VERSION ""

NS_ :

BS_:

BU_: ETH

BO_ 1332 VCFRONT_alertLog: 8 Vector__XXX
 SG_ VCFRONT_alertID M : 0|10@1+ (1,0) [0|0] "" Vector__XXX
 SG_ VCFRONT_a117_VEH_status m117 : 37|1@1+ (1,0) [0|0] "" Vector__XXX
 SG_ VCFRONT_a118_CH_12VBatteryStatus m118 : 37|1@1+ (1,0) [0|0] "" Vector__XXX
 SG_ VCFRONT_a120_VEH_estimatedBrakeTemp m120 : 37|1@1+ (1,0) [0|0] "" Vector__XXX
 SG_ VCFRONT_a171_OPCS m171 : 37|1@1+ (1,0) [0|0] "" Vector__XXX
 SG_ VCFRONT_a180_serviceMode m180 : 37|1@1+ (1,0) [0|0] "" Vector__XXX
 SG_ VCFRONT_a192_serviceMode m192 : 37|1@1+ (1,0) [0|0] "" Vector__XXX
 SG_ VCFRONT_a257_vbatFusedFault m257 : 37|1@1+ (1,0) [0|0] "" Vector__XXX
 SG_ VCFRONT_a365_showroomMode m365 : 37|1@1+ (1,0) [0|0] "" Vector__XXX
 SG_ VCFRONT_a366_TransportMode m366 : 37|1@1+ (1,0) [0|0] "" Vector__XXX
 SG_ VCFRONT_a368_coolantNotFilled m368 : 37|1@1+ (1,0) [0|0] "" Vector__XXX
 SG_ VCFRONT_a444_overTempShutdown m444 : 37|1@1+ (1,0) [0|0] "" Vector__XXX
 SG_ VCFRONT_a446_usingModeledPl m446 : 37|1@1+ (1,0) [0|0] "" Vector__XXX
 SG_ VCFRONT_a462_MOSFETStuckOpen m462 : 37|1@1+ (1,0) [0|0] "" Vector__XXX
 SG_ VCFRONT_a474_drl1Status m474 : 37|3@1+ (1,0) [0|0] "" Vector__XXX
 SG_ VCFRONT_a475_drl1Status m475 : 37|3@1+ (1,0) [0|0] "" Vector__XXX
 SG_ VCFRONT_a478_notEnoughPowerForSupport m478 : 37|1@1+ (1,0) [0|0] "" Vector__XXX
 SG_ VCFRONT_a480_spiNotDone m480 : 37|1@1+ (1,0) [0|0] "" Vector__XXX
 SG_ VCFRONT_a514_cell4Voltage m514 : 37|7@1+ (0.08,0) [0|0] "" Vector__XXX
 SG_ VCFRONT_a515_cell4Voltage m515 : 37|7@1+ (0.08,0) [0|0] "" Vector__XXX
 SG_ VCFRONT_a516_LVBatteryCannotSupportVehicle m516 : 37|1@1+ (1,0) [0|0] "" Vector__XXX
 SG_ VCFRONT_a522_LVBatteryCannotSupportVehicle m522 : 37|1@1+ (1,0) [0|0] "" Vector__XXX
 SG_ VCFRONT_a606_ccQdotTotalBeforeEntry m606 : 37|6@1+ (111.11111111111111,0) [0|0] "" Vector__XXX
 SG_ VCFRONT_a669_vehicleSpeed m669 : 37|7@1+ (2,0) [0|0] "" Vector__XXX
 SG_ VCFRONT_a670_gpioEfuseEn m670 : 37|1@1+ (1,0) [0|0] "" Vector__XXX
 SG_ VCFRONT_a104_BDY_control m104 : 38|1@1+ (1,0) [0|0] "" Vector__XXX
 SG_ VCFRONT_a113_VEH_tripPlanning m113 : 38|1@1+ (1,0) [0|0] "" Vector__XXX
 SG_ VCFRONT_a117_PARTY_prndStatus m117 : 38|1@1+ (1,0) [0|0] "" Vector__XXX
 SG_ VCFRONT_a118_CH_LVBMS_statusHigh m118 : 38|1@1+ (1,0) [0|0] "" Vector__XXX
 SG_ VCFRONT_a120_PARTY_prndControl m120 : 38|1@1+ (1,0) [0|0] "" Vector__XXX
 SG_ VCFRONT_a171_SCCM m171 : 38|1@1+ (1,0) [0|0] "" Vector__XXX
 SG_ VCFRONT_a180_transportMode m180 : 38|1@1+ (1,0) [0|0] "" Vector__XXX
 SG_ VCFRONT_a192_frunkOpen m192 : 38|1@1+ (1,0) [0|0] "" Vector__XXX
 SG_ VCFRONT_a197_prechargeSuccessful m197 : 38|1@1+ (1,0) [0|0] "" Vector__XXX
 SG_ VCFRONT_a257_iBoosterFault m257 : 38|1@1+ (1,0) [0|0] "" Vector__XXX
 SG_ VCFRONT_a365_TransportMode m365 : 38|1@1+ (1,0) [0|0] "" Vector__XXX
 SG_ VCFRONT_a366_ScheduledDeparture m366 : 38|1@1+ (1,0) [0|0] "" Vector__XXX
 SG_ VCFRONT_a368_coolantPumpsFaulted m368 : 38|1@1+ (1,0) [0|0] "" Vector__XXX
 SG_ VCFRONT_a379_minUnfilteredVoltageReached m379 : 38|12@1+ (0.005443676098,0) [0|0] "" Vector__XXX
 SG_ VCFRONT_a400_VrefType m400 : 38|2@1+ (1,0) [0|0] "" Vector__XXX
 SG_ VCFRONT_a413_VrefType m413 : 38|2@1+ (1,0) [0|0] "" Vector__XXX
 SG_ VCFRONT_a415_IBSVoltage m415 : 38|9@1+ (0.04,0) [0|0] "" Vector__XXX
 SG_ VCFRONT_a444_overTempWarning m444 : 38|1@1+ (1,0) [0|0] "" Vector__XXX
 SG_ VCFRONT_a446_usingModeledTs m446 : 38|1@1+ (1,0) [0|0] "" Vector__XXX
 SG_ VCFRONT_a462_Imbalance m462 : 38|1@1+ (1,0) [0|0] "" Vector__XXX
 SG_ VCFRONT_a476_ECPAState m476 : 38|2@1+ (1,0) [0|0] "" Vector__XXX
 SG_ VCFRONT_a478_crashDetected m478 : 38|1@1+ (1,0) [0|0] "" Vector__XXX
 SG_ VCFRONT_a480_configIncorrect m480 : 38|1@1+ (1,0) [0|0] "" Vector__XXX
 SG_ VCFRONT_a595_IBSVoltage m595 : 38|10@1+ (0.1,-1) [0|0] "" Vector__XXX
 SG_ VCFRONT_a058_prevREstimate m58 : 39|12@1+ (0.00061,0) [0|0] "" Vector__XXX
 SG_ VCFRONT_a104_BDY_status m104 : 39|1@1+ (1,0) [0|0] "" Vector__XXX
 SG_ VCFRONT_a113_VEH_vehicleControl3 m113 : 39|1@1+ (1,0) [0|0] "" Vector__XXX
 SG_ VCFRONT_a117_PARTY_lightingSecondary m117 : 39|1@1+ (1,0) [0|0] "" Vector__XXX
 SG_ VCFRONT_a118_CH_alertMatrix m118 : 39|1@1+ (1,0) [0|0] "" Vector__XXX
 SG_ VCFRONT_a120_PARTY_locStatus2 m120 : 39|1@1+ (1,0) [0|0] "" Vector__XXX
 SG_ VCFRONT_a171_LVBMS m171 : 39|1@1+ (1,0) [0|0] "" Vector__XXX
 SG_ VCFRONT_a178_inverterTemp m178 : 39|6@1+ (3,-40) [0|0] "" Vector__XXX
 SG_ VCFRONT_a180_frunkOpen m180 : 39|1@1+ (1,0) [0|0] "" Vector__XXX
 SG_ VCFRONT_a182_dischargedAmpHours m182 : 39|8@1+ (60,0) [0|0] "" Vector__XXX
 SG_ VCFRONT_a183_dischargedAmpHours m183 : 39|8@1+ (60,0) [0|0] "" Vector__XXX
 SG_ VCFRONT_a197_dcrMilliOhms m197 : 39|8@1+ (1,0) [0|0] "" Vector__XXX
 SG_ VCFRONT_a257_espFault m257 : 39|1@1+ (1,0) [0|0] "" Vector__XXX
 SG_ VCFRONT_a365_ScheduledDeparture m365 : 39|1@1+ (1,0) [0|0] "" Vector__XXX
 SG_ VCFRONT_a366_LowCoolant m366 : 39|1@1+ (1,0) [0|0] "" Vector__XXX
 SG_ VCFRONT_a368_preconditionsNotMet m368 : 39|1@1+ (1,0) [0|0] "" Vector__XXX
 SG_ VCFRONT_a407_avgPulseCurrent m407 : 39|7@1+ (1,-127) [0|0] "" Vector__XXX
 SG_ VCFRONT_a444_highSide2GateDriver m444 : 39|1@1+ (1,0) [0|0] "" Vector__XXX
 SG_ VCFRONT_a446_usingModeledTd m446 : 39|1@1+ (1,0) [0|0] "" Vector__XXX
 SG_ VCFRONT_a462_serviceMode m462 : 39|1@1+ (1,0) [0|0] "" Vector__XXX
 SG_ VCFRONT_a478_BMS_MIA m478 : 39|1@1+ (1,0) [0|0] "" Vector__XXX
 SG_ VCFRONT_a480_bufferFull m480 : 39|1@1+ (1,0) [0|0] "" Vector__XXX
 SG_ VCFRONT_a561_cell2Voltage m561 : 39|7@1+ (0.04,0) [0|0] "" Vector__XXX
 SG_ VCFRONT_a562_cell2Voltage m562 : 39|7@1+ (0.04,0) [0|0] "" Vector__XXX
 SG_ VCFRONT_a626_avgPulseCurrent m626 : 39|7@1+ (1,-127) [0|0] "" Vector__XXX
 SG_ VCFRONT_a663_hcmlValidatedGroupsHighWaterMarkPercent_IC500 m663 : 39|5@1+ (3.225806451612903,0) [0|0] "" Vector__XXX
 SG_ VCFRONT_a664_hcmrValidatedGroupsHighWaterMarkPercent_IC500 m664 : 39|5@1+ (3.225806451612903,0) [0|0] "" Vector__XXX
 SG_ VCFRONT_a009_PlAtExit m9 : 40|5@1+ (1,0) [0|0] "" Vector__XXX
 SG_ VCFRONT_a022_TaskInitError2 m22 : 40|8@1+ (1,0) [0|0] "" Vector__XXX
 SG_ VCFRONT_a031_uds_bytes_3 m31 : 40|8@1+ (1,0) [0|0] "" Vector__XXX
 SG_ VCFRONT_a038_faultSource m38 : 40|7@1+ (1,0) [0|0] "" Vector__XXX
 SG_ VCFRONT_a041_CPULoad100msTask m41 : 40|8@1+ (1,0) [0|0] "" Vector__XXX
 SG_ VCFRONT_a042_Usage1000msTask m42 : 40|8@1+ (1,0) [0|0] "" Vector__XXX
 SG_ VCFRONT_a043_CallTrace1 m43 : 40|24@1+ (1,0) [0|0] "" Vector__XXX
 SG_ VCFRONT_a044_CallTrace1 m44 : 40|24@1+ (1,0) [0|0] "" Vector__XXX
 SG_ VCFRONT_a045_CallTrace1 m45 : 40|24@1+ (1,0) [0|0] "" Vector__XXX
 SG_ VCFRONT_a046_CallTrace1 m46 : 40|24@1+ (1,0) [0|0] "" Vector__XXX
 SG_ VCFRONT_a047_CsvHf m47 : 40|16@1+ (1,0) [0|0] "" Vector__XXX
 SG_ VCFRONT_a059_current m59 : 40|12@1+ (0.05,0) [0|0] "" Vector__XXX
 SG_ VCFRONT_a063_disconnected m63 : 40|1@1+ (1,0) [0|0] "" Vector__XXX
 SG_ VCFRONT_a104_PARTY_autonomyControl m104 : 40|1@1+ (1,0) [0|0] "" Vector__XXX
 SG_ VCFRONT_a113_VEH_vehicleControlThermal m113 : 40|1@1+ (1,0) [0|0] "" Vector__XXX
 SG_ VCFRONT_a118_BDY_outputPowerStatus m118 : 40|1@1+ (1,0) [0|0] "" Vector__XXX
 SG_ VCFRONT_a120_VEH_chassisCntl m120 : 40|1@1+ (1,0) [0|0] "" Vector__XXX
 SG_ VCFRONT_a154_lastSilentWakeIBSAmpHours m154 : 40|6@1+ (0.05,-3) [0|0] "" Vector__XXX
 SG_ VCFRONT_a171_IDB m171 : 40|1@1+ (1,0) [0|0] "" Vector__XXX
 SG_ VCFRONT_a180_dcdcLVSupportStatus m180 : 40|2@1+ (1,0) [0|0] "" Vector__XXX
 SG_ VCFRONT_a184_humidityRatio m184 : 40|4@1+ (4,0) [0|0] "" Vector__XXX
 SG_ VCFRONT_a192_IBSCurrent m192 : 40|8@1+ (0.5,-63) [0|0] "" Vector__XXX
 SG_ VCFRONT_a196_disconnectedBatteryTestVoltage m196 : 40|8@1+ (0.0392156862745098,6) [0|0] "" Vector__XXX
 SG_ VCFRONT_a220_serviceMode m220 : 40|1@1+ (1,0) [0|0] "" Vector__XXX
 SG_ VCFRONT_a228_measurementInterval m228 : 40|8@1+ (1,0) [0|0] "" Vector__XXX
 SG_ VCFRONT_a229_measurementInterval m229 : 40|8@1+ (1,0) [0|0] "" Vector__XXX
 SG_ VCFRONT_a230_measurementInterval m230 : 40|8@1+ (1,0) [0|0] "" Vector__XXX
 SG_ VCFRONT_a248_vbatMonitor m248 : 40|12@1+ (0.005443676098,0) [0|0] "" Vector__XXX
 SG_ VCFRONT_a250_calibratedHorizontalPositionHCML m250 : 40|10@1+ (1,0) [0|0] "" Vector__XXX
 SG_ VCFRONT_a257_epas3pFault m257 : 40|1@1+ (1,0) [0|0] "" Vector__XXX
 SG_ VCFRONT_a260_vehiclePowerState m260 : 40|2@1+ (1,0) [0|0] "" Vector__XXX
 SG_ VCFRONT_a283_thmlFanPhaseI m283 : 40|7@1+ (0.25,0) [0|0] "" Vector__XXX
 SG_ VCFRONT_a310_avgTemp m310 : 40|11@1+ (0.125,-40) [0|0] "" Vector__XXX
 SG_ VCFRONT_a311_avgTemp m311 : 40|11@1+ (0.125,-40) [0|0] "" Vector__XXX
 SG_ VCFRONT_a312_avgTemp m312 : 40|11@1+ (0.125,-40) [0|0] "" Vector__XXX
 SG_ VCFRONT_a313_avgTemp m313 : 40|11@1+ (0.125,-40) [0|0] "" Vector__XXX
 SG_ VCFRONT_a314_avgTemp m314 : 40|11@1+ (0.125,-40) [0|0] "" Vector__XXX
 SG_ VCFRONT_a315_avgTemp m315 : 40|11@1+ (0.125,-40) [0|0] "" Vector__XXX
 SG_ VCFRONT_a316_avgTemp m316 : 40|11@1+ (0.125,-40) [0|0] "" Vector__XXX
 SG_ VCFRONT_a317_avgTemp m317 : 40|11@1+ (0.125,-40) [0|0] "" Vector__XXX
 SG_ VCFRONT_a318_avgTemp m318 : 40|11@1+ (0.125,-40) [0|0] "" Vector__XXX
 SG_ VCFRONT_a319_avgTemp m319 : 40|11@1+ (0.125,-40) [0|0] "" Vector__XXX
 SG_ VCFRONT_a320_avgTemp m320 : 40|11@1+ (0.125,-40) [0|0] "" Vector__XXX
 SG_ VCFRONT_a321_avgTemp m321 : 40|11@1+ (0.125,-40) [0|0] "" Vector__XXX
 SG_ VCFRONT_a322_avgTemp m322 : 40|11@1+ (0.125,-40) [0|0] "" Vector__XXX
 SG_ VCFRONT_a323_avgTemp m323 : 40|11@1+ (0.125,-40) [0|0] "" Vector__XXX
 SG_ VCFRONT_a324_avgTemp m324 : 40|11@1+ (0.125,-40) [0|0] "" Vector__XXX
 SG_ VCFRONT_a325_avgTemp m325 : 40|11@1+ (0.125,-40) [0|0] "" Vector__XXX
 SG_ VCFRONT_a334_maxCurrent m334 : 40|12@1+ (0.1,0) [0|0] "" Vector__XXX
 SG_ VCFRONT_a335_maxCurrent m335 : 40|12@1+ (0.1,0) [0|0] "" Vector__XXX
 SG_ VCFRONT_a336_maxCurrent m336 : 40|12@1+ (0.1,0) [0|0] "" Vector__XXX
 SG_ VCFRONT_a337_maxCurrent m337 : 40|12@1+ (0.1,0) [0|0] "" Vector__XXX
 SG_ VCFRONT_a338_maxCurrent m338 : 40|12@1+ (0.1,0) [0|0] "" Vector__XXX
 SG_ VCFRONT_a339_maxCurrent m339 : 40|12@1+ (0.1,0) [0|0] "" Vector__XXX
 SG_ VCFRONT_a340_maxCurrent m340 : 40|12@1+ (0.1,0) [0|0] "" Vector__XXX
 SG_ VCFRONT_a341_maxCurrent m341 : 40|12@1+ (0.1,0) [0|0] "" Vector__XXX
 SG_ VCFRONT_a342_maxCurrent m342 : 40|12@1+ (0.1,0) [0|0] "" Vector__XXX
 SG_ VCFRONT_a343_maxCurrent m343 : 40|12@1+ (0.1,0) [0|0] "" Vector__XXX
 SG_ VCFRONT_a344_maxCurrent m344 : 40|12@1+ (0.1,0) [0|0] "" Vector__XXX
 SG_ VCFRONT_a345_maxCurrent m345 : 40|12@1+ (0.1,0) [0|0] "" Vector__XXX
 SG_ VCFRONT_a346_maxCurrent m346 : 40|12@1+ (0.1,0) [0|0] "" Vector__XXX
 SG_ VCFRONT_a347_maxCurrent m347 : 40|12@1+ (0.1,0) [0|0] "" Vector__XXX
 SG_ VCFRONT_a348_maxCurrent m348 : 40|12@1+ (0.1,0) [0|0] "" Vector__XXX
 SG_ VCFRONT_a349_maxCurrent m349 : 40|12@1+ (0.1,0) [0|0] "" Vector__XXX
 SG_ VCFRONT_a359_vehiclePowerState m359 : 40|2@1+ (1,0) [0|0] "" Vector__XXX
 SG_ VCFRONT_a365_LowCoolant m365 : 40|1@1+ (1,0) [0|0] "" Vector__XXX
 SG_ VCFRONT_a366_userChargeStatus m366 : 40|3@1+ (1,0) [0|0] "" Vector__XXX
 SG_ VCFRONT_a368_belowSocMin m368 : 40|1@1+ (1,0) [0|0] "" Vector__XXX
 SG_ VCFRONT_a370_notEnoughPowerForSupport m370 : 40|1@1+ (1,0) [0|0] "" Vector__XXX
 SG_ VCFRONT_a373_compDemandChiller m373 : 40|7@1+ (1,0) [0|0] "" Vector__XXX
 SG_ VCFRONT_a389_latchStatus m389 : 40|4@1+ (1,0) [0|0] "" Vector__XXX
 SG_ VCFRONT_a405_intervalCompareV m405 : 40|8@1+ (0.02,9) [0|0] "" Vector__XXX
 SG_ VCFRONT_a406_avgPulseCurrent m406 : 40|7@1+ (1,-127) [0|0] "" Vector__XXX
 SG_ VCFRONT_a412_pulseCompareVShifted m412 : 40|8@1+ (0.02,9) [0|0] "" Vector__XXX
 SG_ VCFRONT_a428_avgBrickCac m428 : 40|13@1+ (0.1,0) [0|0] "" Vector__XXX
 SG_ VCFRONT_a429_usableEnergy m429 : 40|10@1+ (0.2,-0.2) [0|0] "" Vector__XXX
 SG_ VCFRONT_a433_cellTypeData m433 : 40|8@1+ (1,0) [0|0] "" Vector__XXX
 SG_ VCFRONT_a434_cellTypeData m434 : 40|8@1+ (1,0) [0|0] "" Vector__XXX
 SG_ VCFRONT_a442_numBricksChanged m442 : 40|8@1+ (1,0) [0|0] "" Vector__XXX
 SG_ VCFRONT_a444_lowSide2GateDriver m444 : 40|1@1+ (1,0) [0|0] "" Vector__XXX
 SG_ VCFRONT_a445_actualMSB m445 : 40|8@1+ (1,0) [0|0] "" Vector__XXX
 SG_ VCFRONT_a446_usingModeledTl m446 : 40|1@1+ (1,0) [0|0] "" Vector__XXX
 SG_ VCFRONT_a461_maxSocAhErrorBrickId m461 : 40|7@1+ (1,1) [0|0] "" Vector__XXX
 SG_ VCFRONT_a462_frunkOpen m462 : 40|1@1+ (1,0) [0|0] "" Vector__XXX
 SG_ VCFRONT_a464_subcoolFiltered m464 : 40|7@1+ (0.4,-10) [0|0] "" Vector__XXX
 SG_ VCFRONT_a465_subcoolFiltered m465 : 40|7@1+ (0.4,-10) [0|0] "" Vector__XXX
 SG_ VCFRONT_a466_subcoolFiltered m466 : 40|7@1+ (0.4,-10) [0|0] "" Vector__XXX
 SG_ VCFRONT_a472_headlampTemperature_C m472 : 40|8@1+ (0.5,-40) [0|0] "" Vector__XXX
 SG_ VCFRONT_a473_headlampTemperature_C m473 : 40|8@1+ (0.5,-40) [0|0] "" Vector__XXX
 SG_ VCFRONT_a474_drl2Status m474 : 40|3@1+ (1,0) [0|0] "" Vector__XXX
 SG_ VCFRONT_a475_drl2Status m475 : 40|3@1+ (1,0) [0|0] "" Vector__XXX
 SG_ VCFRONT_a478_PCS_MIA m478 : 40|1@1+ (1,0) [0|0] "" Vector__XXX
 SG_ VCFRONT_a480_hitAlertRateLimit m480 : 40|1@1+ (1,0) [0|0] "" Vector__XXX
 SG_ VCFRONT_a482_desiredPositionRelative m482 : 40|16@1- (1,0) [0|0] "" Vector__XXX
 SG_ VCFRONT_a485_desiredPositionRelative m485 : 40|16@1- (1,0) [0|0] "" Vector__XXX
 SG_ VCFRONT_a492_maxBrickSoc m492 : 40|8@1+ (0.5,0) [0|0] "" Vector__XXX
 SG_ VCFRONT_a493_maxBrickSocByOcvMin m493 : 40|8@1+ (0.5,0) [0|0] "" Vector__XXX
 SG_ VCFRONT_a502_worstBrickV m502 : 40|12@1+ (0.002,0) [0|0] "" Vector__XXX
 SG_ VCFRONT_a508_brickImpedanceId m508 : 40|5@1+ (1,1) [0|0] "" Vector__XXX
 SG_ VCFRONT_a509_ambientTemp m509 : 40|8@1+ (0.5,-40) [0|0] "" Vector__XXX
 SG_ VCFRONT_a510_serviceMode m510 : 40|1@1+ (1,0) [0|0] "" Vector__XXX
 SG_ VCFRONT_a512_sumCellVoltage m512 : 40|8@1+ (0.1,0) [0|0] "" Vector__XXX
 SG_ VCFRONT_a513_packVoltage m513 : 40|8@1+ (0.1,0) [0|0] "" Vector__XXX
 SG_ VCFRONT_a521_ambientTemp m521 : 40|8@1+ (0.5,-40) [0|0] "" Vector__XXX
 SG_ VCFRONT_a523_control2Byte3 m523 : 40|8@1+ (1,0) [0|0] "" Vector__XXX
 SG_ VCFRONT_a534_measuredCloseRange m534 : 40|8@1+ (7,0) [0|0] "" Vector__XXX
 SG_ VCFRONT_a535_measuredCloseRange m535 : 40|8@1+ (7,0) [0|0] "" Vector__XXX
 SG_ VCFRONT_a536_measuredCloseRange m536 : 40|8@1+ (7,0) [0|0] "" Vector__XXX
 SG_ VCFRONT_a537_measuredCloseRange m537 : 40|8@1+ (7,0) [0|0] "" Vector__XXX
 SG_ VCFRONT_a538_measuredCloseRange m538 : 40|8@1+ (7,0) [0|0] "" Vector__XXX
 SG_ VCFRONT_a539_measuredCloseRange m539 : 40|8@1+ (7,0) [0|0] "" Vector__XXX
 SG_ VCFRONT_a542_ambientTempRaw m542 : 40|8@1+ (0.5,-40) [0|0] "" Vector__XXX
 SG_ VCFRONT_a548_LVBMSSOC m548 : 40|5@1+ (3,0) [0|0] "" Vector__XXX
 SG_ VCFRONT_a556_disconnectedBatteryTestVoltage m556 : 40|8@1+ (0.0392156862745098,6) [0|0] "" Vector__XXX
 SG_ VCFRONT_a559_batterySMState m559 : 40|4@1+ (1,0) [0|0] "" Vector__XXX
 SG_ VCFRONT_a582_LVBusVoltageSource m582 : 40|2@1+ (1,0) [0|0] "" Vector__XXX
 SG_ VCFRONT_a587_IBSCurrent m587 : 40|12@1- (0.1,0) [0|0] "" Vector__XXX
 SG_ VCFRONT_a588_vcleftBTerm m588 : 40|8@1- (1,-78) [0|0] "" Vector__XXX
 SG_ VCFRONT_a590_vcrightBTerm m590 : 40|8@1- (1,-78) [0|0] "" Vector__XXX
 SG_ VCFRONT_a592_vcleftCutoffBTerm m592 : 40|8@1- (1,-78) [0|0] "" Vector__XXX
 SG_ VCFRONT_a596_vcrightCutoffBTerm m596 : 40|8@1- (1,-78) [0|0] "" Vector__XXX
 SG_ VCFRONT_a600_IBSCurrent m600 : 40|12@1- (0.1,0) [0|0] "" Vector__XXX
 SG_ VCFRONT_a608_retryCount m608 : 40|4@1+ (1,0) [0|0] "" Vector__XXX
 SG_ VCFRONT_a618_ptInletTemp m618 : 40|6@1+ (2,0) [0|0] "" Vector__XXX
 SG_ VCFRONT_a623_failureLvBatteryEnergyActiveDecel m623 : 40|1@1+ (1,0) [0|0] "" Vector__XXX
 SG_ VCFRONT_a644_minCycleCurrent m644 : 40|8@1- (0.0984251968503937,5.807086614173229) [0|0] "" Vector__XXX
 SG_ VCFRONT_a645_fluidLevelSensorRawLowAnyPointOfCycle m645 : 40|1@1+ (1,0) [0|0] "" Vector__XXX
 SG_ VCFRONT_a646_timeSinceLastValidWash m646 : 40|14@1+ (1,0) [0|0] "" Vector__XXX
 SG_ VCFRONT_a667_homologationRegionOverride m667 : 40|2@1+ (1,0) [0|0] "" Vector__XXX
 SG_ VCFRONT_a668_homologationRegionOverride m668 : 40|2@1+ (1,0) [0|0] "" Vector__XXX
 SG_ VCFRONT_a063_indeterminate m63 : 41|1@1+ (1,0) [0|0] "" Vector__XXX
 SG_ VCFRONT_a104_VEH_autonomyControl m104 : 41|1@1+ (1,0) [0|0] "" Vector__XXX
 SG_ VCFRONT_a113_CH_odo m113 : 41|1@1+ (1,0) [0|0] "" Vector__XXX
 SG_ VCFRONT_a118_BDY_vehicleTime m118 : 41|1@1+ (1,0) [0|0] "" Vector__XXX
 SG_ VCFRONT_a120_CH_locStatus2 m120 : 41|1@1+ (1,0) [0|0] "" Vector__XXX
 SG_ VCFRONT_a171_IDB1 m171 : 41|1@1+ (1,0) [0|0] "" Vector__XXX
 SG_ VCFRONT_a188_timeNotSleeping m188 : 41|6@1+ (1,0) [0|0] "" Vector__XXX
 SG_ VCFRONT_a220_frunkOpen m220 : 41|1@1+ (1,0) [0|0] "" Vector__XXX
 SG_ VCFRONT_a257_epas3sFault m257 : 41|1@1+ (1,0) [0|0] "" Vector__XXX
 SG_ VCFRONT_a365_userChargeStatus m365 : 41|3@1+ (1,0) [0|0] "" Vector__XXX
 SG_ VCFRONT_a370_serviceMode m370 : 41|1@1+ (1,0) [0|0] "" Vector__XXX
 SG_ VCFRONT_a444_highSide1GateDriver m444 : 41|1@1+ (1,0) [0|0] "" Vector__XXX
 SG_ VCFRONT_a446_sensorHasOffsetTd m446 : 41|1@1+ (1,0) [0|0] "" Vector__XXX
 SG_ VCFRONT_a478_HVBlockingMismatch m478 : 41|1@1+ (1,0) [0|0] "" Vector__XXX
 SG_ VCFRONT_a480_hwlo m480 : 41|1@1+ (1,0) [0|0] "" Vector__XXX
 SG_ VCFRONT_a498_testAbortReason m498 : 41|3@1+ (1,0) [0|0] "" Vector__XXX
 SG_ VCFRONT_a510_frunkOpen m510 : 41|1@1+ (1,0) [0|0] "" Vector__XXX
 SG_ VCFRONT_a518_outputVoltageAtPCS m518 : 41|8@1+ (0.1,0) [0|0] "" Vector__XXX
 SG_ VCFRONT_a594_fusionSessionCalibration m594 : 41|9@1- (0.0005,0) [0|0] "" Vector__XXX
 SG_ VCFRONT_a611_coolantFlow m611 : 41|5@1+ (1,0) [0|0] "" Vector__XXX
 SG_ VCFRONT_a623_failureLvBatteryEnergyCritical m623 : 41|1@1+ (1,0) [0|0] "" Vector__XXX
 SG_ VCFRONT_a645_fluidLevelSensorFilteredLowEndOfCycle m645 : 41|1@1+ (1,0) [0|0] "" Vector__XXX
 SG_ VCFRONT_a063_stuckActive m63 : 42|1@1+ (1,0) [0|0] "" Vector__XXX
 SG_ VCFRONT_a104_CH_autonomyControl m104 : 42|1@1+ (1,0) [0|0] "" Vector__XXX
 SG_ VCFRONT_a113_VEH_locationStatus m113 : 42|1@1+ (1,0) [0|0] "" Vector__XXX
 SG_ VCFRONT_a118_PARTY_AP_vehicleState1HzMuxed m118 : 42|1@1+ (1,0) [0|0] "" Vector__XXX
 SG_ VCFRONT_a120_VEH_locStatus m120 : 42|1@1+ (1,0) [0|0] "" Vector__XXX
 SG_ VCFRONT_a171_IDBCAL m171 : 42|1@1+ (1,0) [0|0] "" Vector__XXX
 SG_ VCFRONT_a257_revBattFault m257 : 42|1@1+ (1,0) [0|0] "" Vector__XXX
 SG_ VCFRONT_a260_batterySMState m260 : 42|4@1+ (1,0) [0|0] "" Vector__XXX
 SG_ VCFRONT_a352_startTime m352 : 42|10@1+ (10,0) [0|0] "" Vector__XXX
 SG_ VCFRONT_a359_batterySMState m359 : 42|4@1+ (1,0) [0|0] "" Vector__XXX
 SG_ VCFRONT_a370_sleepCurrent m370 : 42|10@1+ (0.1,0) [0|0] "" Vector__XXX
 SG_ VCFRONT_a391_switch2VoltageAverage m391 : 42|10@1+ (5,0) [0|0] "" Vector__XXX
 SG_ VCFRONT_a444_lowSide1GateDriver m444 : 42|1@1+ (1,0) [0|0] "" Vector__XXX
 SG_ VCFRONT_a446_sensorHasOffsetPd m446 : 42|1@1+ (1,0) [0|0] "" Vector__XXX
 SG_ VCFRONT_a463_switch2VoltageAverage m463 : 42|10@1+ (5,0) [0|0] "" Vector__XXX
 SG_ VCFRONT_a478_HV_UP m478 : 42|1@1+ (1,0) [0|0] "" Vector__XXX
 SG_ VCFRONT_a480_enable m480 : 42|1@1+ (1,0) [0|0] "" Vector__XXX
 SG_ VCFRONT_a484_currentVehiclePitch m484 : 42|10@1- (0.0001,0) [0|0] "" Vector__XXX
 SG_ VCFRONT_a582_batteryType m582 : 42|3@1+ (1,0) [0|0] "" Vector__XXX
 SG_ VCFRONT_a584_switch1StuckReason m584 : 42|2@1+ (1,0) [0|0] "" Vector__XXX
 SG_ VCFRONT_a623_failureReverseBatteryEfuseOff m623 : 42|1@1+ (1,0) [0|0] "" Vector__XXX
 SG_ VCFRONT_a645_totalWashDuration m645 : 42|10@1+ (9.775171065493646,0) [0|0] "" Vector__XXX
 SG_ VCFRONT_a667_isRightHandDrive m667 : 42|1@1+ (1,0) [0|0] "" Vector__XXX
 SG_ VCFRONT_a668_isRightHandDrive m668 : 42|1@1+ (1,0) [0|0] "" Vector__XXX
 SG_ VCFRONT_a063_faulted m63 : 43|1@1+ (1,0) [0|0] "" Vector__XXX
 SG_ VCFRONT_a104_BDY_autonomyControl m104 : 43|1@1+ (1,0) [0|0] "" Vector__XXX
 SG_ VCFRONT_a113_VEH_gpsTime m113 : 43|1@1+ (1,0) [0|0] "" Vector__XXX
 SG_ VCFRONT_a118_BDY_AP_vehicleState1HzMuxed m118 : 43|1@1+ (1,0) [0|0] "" Vector__XXX
 SG_ VCFRONT_a120_VEH_locStatus2 m120 : 43|1@1+ (1,0) [0|0] "" Vector__XXX
 SG_ VCFRONT_a162_ccRightExvFlow m162 : 43|7@1+ (1,0) [0|0] "" Vector__XXX
 SG_ VCFRONT_a171_RCU m171 : 43|1@1+ (1,0) [0|0] "" Vector__XXX
 SG_ VCFRONT_a187_ethBusRetryCount m187 : 43|9@1+ (1,0) [0|0] "" Vector__XXX
 SG_ VCFRONT_a257_vehicleState m257 : 43|5@1+ (1,0) [0|0] "" Vector__XXX
 SG_ VCFRONT_a366_chgNoFlowTetherStatus m366 : 43|2@1+ (1,0) [0|0] "" Vector__XXX
 SG_ VCFRONT_a414_IBSVoltage m414 : 43|11@1+ (0.01088735219,0) [0|0] "" Vector__XXX
 SG_ VCFRONT_a444_highSide2OverCurent m444 : 43|1@1+ (1,0) [0|0] "" Vector__XXX
 SG_ VCFRONT_a446_sensorDroopPd m446 : 43|1@1+ (1,0) [0|0] "" Vector__XXX
 SG_ VCFRONT_a474_drl3Status m474 : 43|3@1+ (1,0) [0|0] "" Vector__XXX
 SG_ VCFRONT_a475_drl3Status m475 : 43|3@1+ (1,0) [0|0] "" Vector__XXX
 SG_ VCFRONT_a477_cell4Voltage m477 : 43|9@1+ (0.01,0) [0|0] "" Vector__XXX
 SG_ VCFRONT_a478_pcsEFuseStable m478 : 43|1@1+ (1,0) [0|0] "" Vector__XXX
 SG_ VCFRONT_a606_ccQdotTotalAtExit m606 : 43|6@1+ (111.11111111111111,0) [0|0] "" Vector__XXX
 SG_ VCFRONT_a623_failureLvbmbEfuseOpen m623 : 43|1@1+ (1,0) [0|0] "" Vector__XXX
 SG_ VCFRONT_a627_cell4Voltage m627 : 43|9@1+ (0.01,0) [0|0] "" Vector__XXX
 SG_ VCFRONT_a104_VEH_wirelessChargingStatus m104 : 44|1@1+ (1,0) [0|0] "" Vector__XXX
 SG_ VCFRONT_a113_VEH_gpsVehicleSpeed m113 : 44|1@1+ (1,0) [0|0] "" Vector__XXX
 SG_ VCFRONT_a118_PARTY_VCFRONT_cameraCleaningStatus m118 : 44|1@1+ (1,0) [0|0] "" Vector__XXX
 SG_ VCFRONT_a120_VEH_prndControl m120 : 44|1@1+ (1,0) [0|0] "" Vector__XXX
 SG_ VCFRONT_a171_RCUCAL m171 : 44|1@1+ (1,0) [0|0] "" Vector__XXX
 SG_ VCFRONT_a184_evapOutTemp m184 : 44|5@1+ (1,0) [0|0] "" Vector__XXX
 SG_ VCFRONT_a190_maxResponseTime m190 : 44|8@1+ (0.1,0) [0|0] "" Vector__XXX
 SG_ VCFRONT_a191_ECPAState m191 : 44|2@1+ (1,0) [0|0] "" Vector__XXX
 SG_ VCFRONT_a258_maxCurrentReached m258 : 44|16@1- (0.005,0) [0|0] "" Vector__XXX
 SG_ VCFRONT_a365_chgNoFlowTetherStatus m365 : 44|2@1+ (1,0) [0|0] "" Vector__XXX
 SG_ VCFRONT_a444_lowSide2OverCurent m444 : 44|1@1+ (1,0) [0|0] "" Vector__XXX
 SG_ VCFRONT_a446_sensorHasOffsetTl m446 : 44|1@1+ (1,0) [0|0] "" Vector__XXX
 SG_ VCFRONT_a478_vcrightEFuseStable m478 : 44|1@1+ (1,0) [0|0] "" Vector__XXX
 SG_ VCFRONT_a498_targetVoltage m498 : 44|10@1+ (0.05,0) [0|0] "" Vector__XXX
 SG_ VCFRONT_a514_packVoltage m514 : 44|8@1+ (0.1,0) [0|0] "" Vector__XXX
 SG_ VCFRONT_a515_packVoltage m515 : 44|8@1+ (0.1,0) [0|0] "" Vector__XXX
 SG_ VCFRONT_a559_bmsState m559 : 44|4@1+ (1,0) [0|0] "" Vector__XXX
 SG_ VCFRONT_a584_switch2StuckReason m584 : 44|2@1+ (1,0) [0|0] "" Vector__XXX
 SG_ VCFRONT_a608_setFromNvm m608 : 44|1@1+ (1,0) [0|0] "" Vector__XXX
 SG_ VCFRONT_a623_failureLvBatteryComms m623 : 44|1@1+ (1,0) [0|0] "" Vector__XXX
 SG_ VCFRONT_a663_hcmlGroupsHighWaterMarkPercent_IC600 m663 : 44|5@1+ (3.225806451612903,0) [0|0] "" Vector__XXX
 SG_ VCFRONT_a664_hcmrGroupsHighWaterMarkPercent_IC600 m664 : 44|5@1+ (3.225806451612903,0) [0|0] "" Vector__XXX
 SG_ VCFRONT_a669_minPackSOC m669 : 44|9@1+ (0.2,0) [0|0] "" Vector__XXX
 SG_ VCFRONT_a104_VEH_control m104 : 45|1@1+ (1,0) [0|0] "" Vector__XXX
 SG_ VCFRONT_a113_VEH_status2 m113 : 45|1@1+ (1,0) [0|0] "" Vector__XXX
 SG_ VCFRONT_a120_VEH_vehicleEstimates m120 : 45|1@1+ (1,0) [0|0] "" Vector__XXX
 SG_ VCFRONT_a171_DPB m171 : 45|1@1+ (1,0) [0|0] "" Vector__XXX
 SG_ VCFRONT_a178_ambientTempFiltered m178 : 45|8@1+ (0.5,-40) [0|0] "" Vector__XXX
 SG_ VCFRONT_a366_updateInProgress m366 : 45|1@1+ (1,0) [0|0] "" Vector__XXX
 SG_ VCFRONT_a403_IBSTemp m403 : 45|7@1+ (1,-40) [0|0] "" Vector__XXX
 SG_ VCFRONT_a444_highSide1OverCurent m444 : 45|1@1+ (1,0) [0|0] "" Vector__XXX
 SG_ VCFRONT_a446_sensorIntermittentPs m446 : 45|1@1+ (1,0) [0|0] "" Vector__XXX
 SG_ VCFRONT_a478_contactorEFuseStable m478 : 45|1@1+ (1,0) [0|0] "" Vector__XXX
 SG_ VCFRONT_a541_AverageCurrent m541 : 45|10@1+ (0.05,0) [0|0] "" Vector__XXX
 SG_ VCFRONT_a548_serviceMode m548 : 45|1@1+ (1,0) [0|0] "" Vector__XXX
 SG_ VCFRONT_a582_inFactoryMode m582 : 45|1@1+ (1,0) [0|0] "" Vector__XXX
 SG_ VCFRONT_a623_failureLvBatterySensorIbsMia m623 : 45|1@1+ (1,0) [0|0] "" Vector__XXX
 SG_ VCFRONT_a104_VEH_redundantBrakingControl m104 : 46|1@1+ (1,0) [0|0] "" Vector__XXX
 SG_ VCFRONT_a113_VEH_autopilotControl m113 : 46|1@1+ (1,0) [0|0] "" Vector__XXX
 SG_ VCFRONT_a120_PARTY_motorStatus m120 : 46|1@1+ (1,0) [0|0] "" Vector__XXX
 SG_ VCFRONT_a171_DPBCAL m171 : 46|1@1+ (1,0) [0|0] "" Vector__XXX
 SG_ VCFRONT_a191_LVBMSCurrentTargetValid m191 : 46|1@1+ (1,0) [0|0] "" Vector__XXX
 SG_ VCFRONT_a260_HV_UP m260 : 46|1@1+ (1,0) [0|0] "" Vector__XXX
 SG_ VCFRONT_a365_updateInProgress m365 : 46|1@1+ (1,0) [0|0] "" Vector__XXX
 SG_ VCFRONT_a366_dcCharging m366 : 46|1@1+ (1,0) [0|0] "" Vector__XXX
 SG_ VCFRONT_a407_pulseCurrentVarianceShifted m407 : 46|6@1+ (0.25,0) [0|0] "" Vector__XXX
 SG_ VCFRONT_a408_IBSTemp m408 : 46|7@1+ (1,-40) [0|0] "" Vector__XXX
 SG_ VCFRONT_a416_socMin m416 : 46|8@1+ (0.5,0) [0|0] "" Vector__XXX
 SG_ VCFRONT_a417_socMax m417 : 46|8@1+ (0.5,0) [0|0] "" Vector__XXX
 SG_ VCFRONT_a418_socMax m418 : 46|8@1+ (0.5,0) [0|0] "" Vector__XXX
 SG_ VCFRONT_a419_socMin m419 : 46|8@1+ (0.5,0) [0|0] "" Vector__XXX
 SG_ VCFRONT_a423_socMin m423 : 46|8@1+ (0.5,0) [0|0] "" Vector__XXX
 SG_ VCFRONT_a424_socMin m424 : 46|8@1+ (0.5,0) [0|0] "" Vector__XXX
 SG_ VCFRONT_a444_lowSide1OverCurent m444 : 46|1@1+ (1,0) [0|0] "" Vector__XXX
 SG_ VCFRONT_a446_sensorIntermittentPd m446 : 46|1@1+ (1,0) [0|0] "" Vector__XXX
 SG_ VCFRONT_a478_hvcEFuseStable m478 : 46|1@1+ (1,0) [0|0] "" Vector__XXX
 SG_ VCFRONT_a481_stuckOnFinished m481 : 46|1@1+ (1,0) [0|0] "" Vector__XXX
 SG_ VCFRONT_a503_socMax m503 : 46|8@1+ (0.5,0) [0|0] "" Vector__XXX
 SG_ VCFRONT_a527_cell4Voltage m527 : 46|10@1+ (0.01,0) [0|0] "" Vector__XXX
 SG_ VCFRONT_a548_frunkOpen m548 : 46|1@1+ (1,0) [0|0] "" Vector__XXX
 SG_ VCFRONT_a555_cell4Voltage m555 : 46|10@1+ (0.01,0) [0|0] "" Vector__XXX
 SG_ VCFRONT_a561_cell3Voltage m561 : 46|7@1+ (0.04,0) [0|0] "" Vector__XXX
 SG_ VCFRONT_a562_cell3Voltage m562 : 46|7@1+ (0.04,0) [0|0] "" Vector__XXX
 SG_ VCFRONT_a582_frunkOpen m582 : 46|1@1+ (1,0) [0|0] "" Vector__XXX
 SG_ VCFRONT_a584_firstFaultedSwitch m584 : 46|3@1+ (1,0) [0|0] "" Vector__XXX
 SG_ VCFRONT_a611_compressorPower m611 : 46|6@1+ (200,0) [0|0] "" Vector__XXX
 SG_ VCFRONT_a623_failureLvBatteryConnection m623 : 46|1@1+ (1,0) [0|0] "" Vector__XXX
 SG_ VCFRONT_a626_pulseCurrentVarianceShifted m626 : 46|6@1+ (0.25,0) [0|0] "" Vector__XXX
 SG_ VCFRONT_a634_ajar2ClosingDeltaV m634 : 46|10@1- (0.01,0) [0|0] "" Vector__XXX
 SG_ VCFRONT_a104_BDY_bodyControls m104 : 47|1@1+ (1,0) [0|0] "" Vector__XXX
 SG_ VCFRONT_a113_VEH_ambientLightingCtrls m113 : 47|1@1+ (1,0) [0|0] "" Vector__XXX
 SG_ VCFRONT_a120_VEH_motorStatus m120 : 47|1@1+ (1,0) [0|0] "" Vector__XXX
 SG_ VCFRONT_a171_serviceMode m171 : 47|1@1+ (1,0) [0|0] "" Vector__XXX
 SG_ VCFRONT_a182_chargedAmpHours m182 : 47|8@1+ (60,0) [0|0] "" Vector__XXX
 SG_ VCFRONT_a183_chargedAmpHours m183 : 47|8@1+ (60,0) [0|0] "" Vector__XXX
 SG_ VCFRONT_a188_chargeRequest m188 : 47|1@1+ (1,0) [0|0] "" Vector__XXX
 SG_ VCFRONT_a191_LVBMSVoltageTargetValid m191 : 47|1@1+ (1,0) [0|0] "" Vector__XXX
 SG_ VCFRONT_a197_validityStatus m197 : 47|7@1+ (1,0) [0|0] "" Vector__XXX
 SG_ VCFRONT_a260_notEnoughPowerForSupport m260 : 47|1@1+ (1,0) [0|0] "" Vector__XXX
 SG_ VCFRONT_a365_dcCharging m365 : 47|1@1+ (1,0) [0|0] "" Vector__XXX
 SG_ VCFRONT_a366_finishedSuccessfully m366 : 47|1@1+ (1,0) [0|0] "" Vector__XXX
 SG_ VCFRONT_a406_pulseCurrentVariance m406 : 47|6@1+ (0.25,0) [0|0] "" Vector__XXX
 SG_ VCFRONT_a415_IBSAmpHours m415 : 47|7@1+ (0.02,-2.55) [0|0] "" Vector__XXX
 SG_ VCFRONT_a444_spiInit m444 : 47|1@1+ (1,0) [0|0] "" Vector__XXX
 SG_ VCFRONT_a446_sensorIntermittentPl m446 : 47|1@1+ (1,0) [0|0] "" Vector__XXX
 SG_ VCFRONT_a465_flaggedAtSteadyState m465 : 47|1@1+ (1,0) [0|0] "" Vector__XXX
 SG_ VCFRONT_a478_frunkOpen m478 : 47|1@1+ (1,0) [0|0] "" Vector__XXX
 SG_ VCFRONT_a481_stuckOnFailure m481 : 47|1@1+ (1,0) [0|0] "" Vector__XXX
 SG_ VCFRONT_a623_failureLvBatteryConnectionUnknown m623 : 47|1@1+ (1,0) [0|0] "" Vector__XXX
 SG_ VCFRONT_a000_alertDataW2 m0 : 48|16@1+ (1,0) [0|0] "" Vector__XXX
 SG_ VCFRONT_a003_Data m3 : 48|16@1+ (1,0) [0|0] "" Vector__XXX
 SG_ VCFRONT_a009_subcoolAtExit m9 : 48|5@1- (1,6) [0|0] "" Vector__XXX
 SG_ VCFRONT_a022_TaskInitError3 m22 : 48|8@1+ (1,0) [0|0] "" Vector__XXX
 SG_ VCFRONT_a031_uds_bytes_4 m31 : 48|8@1+ (1,0) [0|0] "" Vector__XXX
 SG_ VCFRONT_a041_CPULoad1000msTask m41 : 48|8@1+ (1,0) [0|0] "" Vector__XXX
 SG_ VCFRONT_a042_UsageUDSTask m42 : 48|8@1+ (1,0) [0|0] "" Vector__XXX
 SG_ VCFRONT_a113_VEH_driverAssistMapData m113 : 48|1@1+ (1,0) [0|0] "" Vector__XXX
 SG_ VCFRONT_a120_BDY_speed m120 : 48|1@1+ (1,0) [0|0] "" Vector__XXX
 SG_ VCFRONT_a127_vcleftEFuseTemp m127 : 48|11@1+ (0.125,-40) [0|0] "" Vector__XXX
 SG_ VCFRONT_a128_vcrightEFuseTemp m128 : 48|11@1+ (0.125,-40) [0|0] "" Vector__XXX
 SG_ VCFRONT_a129_pcsEFuseTemp m129 : 48|11@1+ (0.125,-40) [0|0] "" Vector__XXX
 SG_ VCFRONT_a130_epas3pEFuseTemp m130 : 48|11@1+ (0.125,-40) [0|0] "" Vector__XXX
 SG_ VCFRONT_a131_epas3sEFuseTemp m131 : 48|11@1+ (0.125,-40) [0|0] "" Vector__XXX
 SG_ VCFRONT_a132_iBoosterEFuseTemp m132 : 48|11@1+ (0.125,-40) [0|0] "" Vector__XXX
 SG_ VCFRONT_a133_espEFuseTemp m133 : 48|11@1+ (0.125,-40) [0|0] "" Vector__XXX
 SG_ VCFRONT_a134_fusedHighTemp m134 : 48|11@1+ (0.125,-40) [0|0] "" Vector__XXX
 SG_ VCFRONT_a154_lastSilentWakeTimeSlept m154 : 48|8@1+ (0.2,0) [0|0] "" Vector__XXX
 SG_ VCFRONT_a155_minHVComingUpIBSTemperature m155 : 48|7@1+ (1,-24) [0|0] "" Vector__XXX
 SG_ VCFRONT_a180_IBSVoltage m180 : 48|8@1+ (0.08741903380905883,0) [0|0] "" Vector__XXX
 SG_ VCFRONT_a188_12VSupport m188 : 48|1@1+ (1,0) [0|0] "" Vector__XXX
 SG_ VCFRONT_a191_serviceMode m191 : 48|1@1+ (1,0) [0|0] "" Vector__XXX
 SG_ VCFRONT_a192_PCSCurrent m192 : 48|8@1+ (0.5,-127) [0|0] "" Vector__XXX
 SG_ VCFRONT_a196_disconnectedBatteryTestPrevVoltage m196 : 48|8@1+ (0.0392156862745098,6) [0|0] "" Vector__XXX
 SG_ VCFRONT_a213_LVBatteryTemp m213 : 48|16@1- (0.01,0) [0|0] "" Vector__XXX
 SG_ VCFRONT_a219_IBSCurrent m219 : 48|16@1- (0.005,0) [0|0] "" Vector__XXX
 SG_ VCFRONT_a242_IBSAmpHours m242 : 48|8@1+ (0.01,-2.55) [0|0] "" Vector__XXX
 SG_ VCFRONT_a243_LVBatteryTemp m243 : 48|16@1- (0.01,0) [0|0] "" Vector__XXX
 SG_ VCFRONT_a244_vbatProtVoltage m244 : 48|16@1+ (0.1,0) [0|0] "" Vector__XXX
 SG_ VCFRONT_a245_eFuseRemainingRetries m245 : 48|4@1+ (1,0) [0|0] "" Vector__XXX
 SG_ VCFRONT_a246_eFuseRemainingRetries m246 : 48|4@1+ (1,0) [0|0] "" Vector__XXX
 SG_ VCFRONT_a252_IBSCurrent m252 : 48|16@1- (0.005,0) [0|0] "" Vector__XXX
 SG_ VCFRONT_a253_LVBatteryTemp m253 : 48|7@1+ (1,-40) [0|0] "" Vector__XXX
 SG_ VCFRONT_a259_maxCurrentReached m259 : 48|16@1- (0.005,0) [0|0] "" Vector__XXX
 SG_ VCFRONT_a260_coolantHasBeenFilled m260 : 48|1@1+ (1,0) [0|0] "" Vector__XXX
 SG_ VCFRONT_a269_IBSAmpHours m269 : 48|8@1+ (0.01,-2.55) [0|0] "" Vector__XXX
 SG_ VCFRONT_a283_thmlFanPhaseILimit m283 : 48|7@1+ (0.25,0) [0|0] "" Vector__XXX
 SG_ VCFRONT_a303_lockStatus m303 : 48|2@1+ (1,0) [0|0] "" Vector__XXX
 SG_ VCFRONT_a309_lockStatus m309 : 48|2@1+ (1,0) [0|0] "" Vector__XXX
 SG_ VCFRONT_a326_vehicleState m326 : 48|2@1+ (1,0) [0|0] "" Vector__XXX
 SG_ VCFRONT_a327_vehicleState m327 : 48|2@1+ (1,0) [0|0] "" Vector__XXX
 SG_ VCFRONT_a328_vehicleState m328 : 48|2@1+ (1,0) [0|0] "" Vector__XXX
 SG_ VCFRONT_a329_vehicleState m329 : 48|2@1+ (1,0) [0|0] "" Vector__XXX
 SG_ VCFRONT_a330_vehicleState m330 : 48|2@1+ (1,0) [0|0] "" Vector__XXX
 SG_ VCFRONT_a331_vehicleState m331 : 48|2@1+ (1,0) [0|0] "" Vector__XXX
 SG_ VCFRONT_a332_vehicleState m332 : 48|2@1+ (1,0) [0|0] "" Vector__XXX
 SG_ VCFRONT_a333_vehicleState m333 : 48|2@1+ (1,0) [0|0] "" Vector__XXX
 SG_ VCFRONT_a359_hvState m359 : 48|3@1+ (1,0) [0|0] "" Vector__XXX
 SG_ VCFRONT_a363_checkIntervalDays m363 : 48|5@1+ (1,0) [0|0] "" Vector__XXX
 SG_ VCFRONT_a365_pcsTooHot m365 : 48|1@1+ (1,0) [0|0] "" Vector__XXX
 SG_ VCFRONT_a366_pcsReportsUnavailable m366 : 48|1@1+ (1,0) [0|0] "" Vector__XXX
 SG_ VCFRONT_a387_maxCurrentReached m387 : 48|16@1- (0.005,0) [0|0] "" Vector__XXX
 SG_ VCFRONT_a388_maxCurrentReached m388 : 48|16@1- (0.005,0) [0|0] "" Vector__XXX
 SG_ VCFRONT_a401_IBSAmpHours m401 : 48|8@1+ (0.01,-2.55) [0|0] "" Vector__XXX
 SG_ VCFRONT_a404_maxCurrentReached m404 : 48|16@1- (0.005,0) [0|0] "" Vector__XXX
 SG_ VCFRONT_a405_avgIntervalCurrent m405 : 48|5@1+ (1,-31) [0|0] "" Vector__XXX
 SG_ VCFRONT_a410_IBSAmpHours m410 : 48|8@1+ (0.01,-2.55) [0|0] "" Vector__XXX
 SG_ VCFRONT_a411_IBSAmpHours m411 : 48|8@1+ (0.01,-2.55) [0|0] "" Vector__XXX
 SG_ VCFRONT_a412_avgPulseCurrentShifted m412 : 48|7@1+ (1,-127) [0|0] "" Vector__XXX
 SG_ VCFRONT_a421_hcmlTxBufferHighWaterMarkPercent m421 : 48|5@1+ (3.225806451612903,0) [0|0] "" Vector__XXX
 SG_ VCFRONT_a427_cacChangeBrickId m427 : 48|7@1+ (1,1) [0|0] "" Vector__XXX
 SG_ VCFRONT_a430_hvjbCurrentLimit m430 : 48|16@1- (0.1,0) [0|0] "" Vector__XXX
 SG_ VCFRONT_a431_hvjbCurrentLimit m431 : 48|16@1- (0.1,0) [0|0] "" Vector__XXX
 SG_ VCFRONT_a433_bmbModuleIdValid m433 : 48|1@1+ (1,0) [0|0] "" Vector__XXX
 SG_ VCFRONT_a434_bmbModuleIdValid m434 : 48|1@1+ (1,0) [0|0] "" Vector__XXX
 SG_ VCFRONT_a435_hvjbCurrentLimit m435 : 48|16@1- (0.1,0) [0|0] "" Vector__XXX
 SG_ VCFRONT_a436_hvjbCurrentLimit m436 : 48|16@1- (0.1,0) [0|0] "" Vector__XXX
 SG_ VCFRONT_a442_brickChangeHystRatio m442 : 48|10@1+ (0.001,0) [0|0] "" Vector__XXX
 SG_ VCFRONT_a444_spiPeriodicCheck m444 : 48|1@1+ (1,0) [0|0] "" Vector__XXX
 SG_ VCFRONT_a445_actualLSB m445 : 48|8@1+ (1,0) [0|0] "" Vector__XXX
 SG_ VCFRONT_a446_sensorIntermittentTs m446 : 48|1@1+ (1,0) [0|0] "" Vector__XXX
 SG_ VCFRONT_a461_numBricksHighSocAhError m461 : 48|8@1+ (1,0) [0|0] "" Vector__XXX
 SG_ VCFRONT_a465_flaggedAtUnsteadyState m465 : 48|1@1+ (1,0) [0|0] "" Vector__XXX
 SG_ VCFRONT_a474_turnStatus m474 : 48|3@1+ (1,0) [0|0] "" Vector__XXX
 SG_ VCFRONT_a475_turnStatus m475 : 48|3@1+ (1,0) [0|0] "" Vector__XXX
 SG_ VCFRONT_a481_hardShortThresholdReached m481 : 48|1@1+ (1,0) [0|0] "" Vector__XXX
 SG_ VCFRONT_a492_avgBrickSoc m492 : 48|8@1+ (0.5,0) [0|0] "" Vector__XXX
 SG_ VCFRONT_a493_maxBrickSoc m493 : 48|7@1+ (1,0) [0|0] "" Vector__XXX
 SG_ VCFRONT_a497_SumCellVoltage m497 : 48|8@1+ (0.1,0) [0|0] "" Vector__XXX
 SG_ VCFRONT_a509_serviceMode m509 : 48|1@1+ (1,0) [0|0] "" Vector__XXX
 SG_ VCFRONT_a511_hvState m511 : 48|3@1+ (1,0) [0|0] "" Vector__XXX
 SG_ VCFRONT_a512_overcurrentDirection m512 : 48|2@1+ (1,0) [0|0] "" Vector__XXX
 SG_ VCFRONT_a513_packSOC m513 : 48|10@1+ (0.1,0) [0|0] "" Vector__XXX
 SG_ VCFRONT_a521_serviceMode m521 : 48|1@1+ (1,0) [0|0] "" Vector__XXX
 SG_ VCFRONT_a523_control3Byte2 m523 : 48|8@1+ (1,0) [0|0] "" Vector__XXX
 SG_ VCFRONT_a529_externalPowerSupply m529 : 48|1@1+ (1,0) [0|0] "" Vector__XXX
 SG_ VCFRONT_a530_vehicleState m530 : 48|2@1+ (1,0) [0|0] "" Vector__XXX
 SG_ VCFRONT_a542_ambientTempFiltered m542 : 48|8@1+ (0.5,-40) [0|0] "" Vector__XXX
 SG_ VCFRONT_a548_PCSTargetVoltage m548 : 48|8@1+ (0.1,0) [0|0] "" Vector__XXX
 SG_ VCFRONT_a556_disconnectedBatteryTestPrevVoltage m556 : 48|8@1+ (0.0392156862745098,6) [0|0] "" Vector__XXX
 SG_ VCFRONT_a558_levelingOffsetPriorToAiming m558 : 48|8@1- (1,0) [0|0] "" Vector__XXX
 SG_ VCFRONT_a559_dcdcLVSupportStatus m559 : 48|2@1+ (1,0) [0|0] "" Vector__XXX
 SG_ VCFRONT_a564_levelingOffsetPriorToAiming m564 : 48|8@1- (1,0) [0|0] "" Vector__XXX
 SG_ VCFRONT_a579_leftHeadlightRemainingRetries m579 : 48|4@1+ (1,0) [0|0] "" Vector__XXX
 SG_ VCFRONT_a580_rightHeadlightRemainingRetries m580 : 48|4@1+ (1,0) [0|0] "" Vector__XXX
 SG_ VCFRONT_a588_vcleftCTerm m588 : 48|16@1- (50,0) [0|0] "" Vector__XXX
 SG_ VCFRONT_a589_vcleftMaxCount m589 : 48|5@1+ (1,0) [0|0] "" Vector__XXX
 SG_ VCFRONT_a590_vcrightCTerm m590 : 48|16@1- (50,0) [0|0] "" Vector__XXX
 SG_ VCFRONT_a591_vcrightMaxCount m591 : 48|5@1+ (1,0) [0|0] "" Vector__XXX
 SG_ VCFRONT_a592_vcleftCutoffCTerm m592 : 48|16@1- (50,0) [0|0] "" Vector__XXX
 SG_ VCFRONT_a593_vcleftCutoffMaxCount m593 : 48|5@1+ (1,0) [0|0] "" Vector__XXX
 SG_ VCFRONT_a596_vcrightCutoffCTerm m596 : 48|16@1- (50,0) [0|0] "" Vector__XXX
 SG_ VCFRONT_a597_vcrightCutoffMaxCount m597 : 48|5@1+ (1,0) [0|0] "" Vector__XXX
 SG_ VCFRONT_a618_relativeHumidity m618 : 48|6@1+ (0.02,0) [0|0] "" Vector__XXX
 SG_ VCFRONT_a623_failurePcsEfuseOff m623 : 48|1@1+ (1,0) [0|0] "" Vector__XXX
 SG_ VCFRONT_a635_sleepShutdownCompleteCore1 m635 : 48|1@1+ (1,0) [0|0] "" Vector__XXX
 SG_ VCFRONT_a643_hcmrTxBufferHighWaterMarkPercent m643 : 48|5@1+ (3.225806451612903,0) [0|0] "" Vector__XXX
 SG_ VCFRONT_a644_maxCycleCurrent m644 : 48|8@1- (0.0984251968503937,5.807086614173229) [0|0] "" Vector__XXX
 SG_ VCFRONT_a113_CH_vehicleControl2 m113 : 49|1@1+ (1,0) [0|0] "" Vector__XXX
 SG_ VCFRONT_a184_evapOutTempNominal m184 : 49|5@1+ (1,0) [0|0] "" Vector__XXX
 SG_ VCFRONT_a188_ThermalSupport m188 : 49|1@1+ (1,0) [0|0] "" Vector__XXX
 SG_ VCFRONT_a191_frunkOpen m191 : 49|1@1+ (1,0) [0|0] "" Vector__XXX
 SG_ VCFRONT_a260_ampHourTrigger m260 : 49|1@1+ (1,0) [0|0] "" Vector__XXX
 SG_ VCFRONT_a365_pcsReportsUnavailable m365 : 49|1@1+ (1,0) [0|0] "" Vector__XXX
 SG_ VCFRONT_a366_bmsTooHot m366 : 49|1@1+ (1,0) [0|0] "" Vector__XXX
 SG_ VCFRONT_a433_useBmbModuleId m433 : 49|1@1+ (1,0) [0|0] "" Vector__XXX
 SG_ VCFRONT_a434_useBmbModuleId m434 : 49|1@1+ (1,0) [0|0] "" Vector__XXX
 SG_ VCFRONT_a444_spiFault m444 : 49|1@1+ (1,0) [0|0] "" Vector__XXX
 SG_ VCFRONT_a446_sensorIntermittentTd m446 : 49|1@1+ (1,0) [0|0] "" Vector__XXX
 SG_ VCFRONT_a481_softShortThresholdReached m481 : 49|1@1+ (1,0) [0|0] "" Vector__XXX
 SG_ VCFRONT_a509_frunkOpen m509 : 49|1@1+ (1,0) [0|0] "" Vector__XXX
 SG_ VCFRONT_a518_packSOC m518 : 49|10@1+ (0.1,0) [0|0] "" Vector__XXX
 SG_ VCFRONT_a521_frunkOpen m521 : 49|1@1+ (1,0) [0|0] "" Vector__XXX
 SG_ VCFRONT_a529_LVBusVoltageNotControllable m529 : 49|1@1+ (1,0) [0|0] "" Vector__XXX
 SG_ VCFRONT_a584_elapsedTime m584 : 49|15@1+ (100,0) [0|0] "" Vector__XXX
 SG_ VCFRONT_a606_battLPMBeforeEntry m606 : 49|5@1+ (1,0) [0|0] "" Vector__XXX
 SG_ VCFRONT_a623_failurePcsNotActive m623 : 49|1@1+ (1,0) [0|0] "" Vector__XXX
 SG_ VCFRONT_a635_sleepShutdownCompleteCore2 m635 : 49|1@1+ (1,0) [0|0] "" Vector__XXX
 SG_ VCFRONT_a663_hcmlValidatedGroupsHighWaterMarkPercent_IC600 m663 : 49|5@1+ (3.225806451612903,0) [0|0] "" Vector__XXX
 SG_ VCFRONT_a664_hcmrValidatedGroupsHighWaterMarkPercent_IC600 m664 : 49|5@1+ (3.225806451612903,0) [0|0] "" Vector__XXX
 SG_ VCFRONT_a113_VEH_odo m113 : 50|1@1+ (1,0) [0|0] "" Vector__XXX
 SG_ VCFRONT_a162_evapExvFlow m162 : 50|7@1+ (1,0) [0|0] "" Vector__XXX
 SG_ VCFRONT_a188_accessoryRequest m188 : 50|1@1+ (1,0) [0|0] "" Vector__XXX
 SG_ VCFRONT_a191_vehicleLoadShedStage m191 : 50|2@1+ (1,0) [0|0] "" Vector__XXX
 SG_ VCFRONT_a250_calibratedHorizontalPositionHCMR m250 : 50|10@1+ (1,0) [0|0] "" Vector__XXX
 SG_ VCFRONT_a260_voltageTrigger m260 : 50|1@1+ (1,0) [0|0] "" Vector__XXX
 SG_ VCFRONT_a365_bmsTooHot m365 : 50|1@1+ (1,0) [0|0] "" Vector__XXX
 SG_ VCFRONT_a379_timeBelowVoltageThreshold m379 : 50|6@1+ (32,0) [0|0] "" Vector__XXX
 SG_ VCFRONT_a429_duration m429 : 50|6@1+ (1,-1) [0|0] "" Vector__XXX
 SG_ VCFRONT_a444_voltageMonitor m444 : 50|1@1+ (1,0) [0|0] "" Vector__XXX
 SG_ VCFRONT_a446_sensorIntermittentTl m446 : 50|1@1+ (1,0) [0|0] "" Vector__XXX
 SG_ VCFRONT_a481_currentSenseVoltageDiff m481 : 50|8@1+ (1,0) [0|0] "" Vector__XXX
 SG_ VCFRONT_a512_serviceMode m512 : 50|1@1+ (1,0) [0|0] "" Vector__XXX
 SG_ VCFRONT_a559_factoryMode m559 : 50|1@1+ (1,0) [0|0] "" Vector__XXX
 SG_ VCFRONT_a594_lifetimeSampleCount m594 : 50|10@1+ (100,0) [0|0] "" Vector__XXX
 SG_ VCFRONT_a623_failurePcsMia m623 : 50|1@1+ (1,0) [0|0] "" Vector__XXX
 SG_ VCFRONT_a635_didCore1EverSleep m635 : 50|1@1+ (1,0) [0|0] "" Vector__XXX
 SG_ VCFRONT_a058_newREstimate m58 : 51|12@1+ (0.00061,0) [0|0] "" Vector__XXX
 SG_ VCFRONT_a188_CANAfterQuiet m188 : 51|1@1+ (1,0) [0|0] "" Vector__XXX
 SG_ VCFRONT_a260_crashDetected m260 : 51|1@1+ (1,0) [0|0] "" Vector__XXX
 SG_ VCFRONT_a310_vehicleState m310 : 51|2@1+ (1,0) [0|0] "" Vector__XXX
 SG_ VCFRONT_a311_vehicleState m311 : 51|2@1+ (1,0) [0|0] "" Vector__XXX
 SG_ VCFRONT_a312_vehicleState m312 : 51|2@1+ (1,0) [0|0] "" Vector__XXX
 SG_ VCFRONT_a313_vehicleState m313 : 51|2@1+ (1,0) [0|0] "" Vector__XXX
 SG_ VCFRONT_a314_vehicleState m314 : 51|2@1+ (1,0) [0|0] "" Vector__XXX
 SG_ VCFRONT_a315_vehicleState m315 : 51|2@1+ (1,0) [0|0] "" Vector__XXX
 SG_ VCFRONT_a316_vehicleState m316 : 51|2@1+ (1,0) [0|0] "" Vector__XXX
 SG_ VCFRONT_a317_vehicleState m317 : 51|2@1+ (1,0) [0|0] "" Vector__XXX
 SG_ VCFRONT_a318_vehicleState m318 : 51|2@1+ (1,0) [0|0] "" Vector__XXX
 SG_ VCFRONT_a319_vehicleState m319 : 51|2@1+ (1,0) [0|0] "" Vector__XXX
 SG_ VCFRONT_a320_vehicleState m320 : 51|2@1+ (1,0) [0|0] "" Vector__XXX
 SG_ VCFRONT_a321_vehicleState m321 : 51|2@1+ (1,0) [0|0] "" Vector__XXX
 SG_ VCFRONT_a322_vehicleState m322 : 51|2@1+ (1,0) [0|0] "" Vector__XXX
 SG_ VCFRONT_a323_vehicleState m323 : 51|2@1+ (1,0) [0|0] "" Vector__XXX
 SG_ VCFRONT_a324_vehicleState m324 : 51|2@1+ (1,0) [0|0] "" Vector__XXX
 SG_ VCFRONT_a325_vehicleState m325 : 51|2@1+ (1,0) [0|0] "" Vector__XXX
 SG_ VCFRONT_a359_coolantHasBeenFilled m359 : 51|1@1+ (1,0) [0|0] "" Vector__XXX
 SG_ VCFRONT_a444_enableLow m444 : 51|1@1+ (1,0) [0|0] "" Vector__XXX
 SG_ VCFRONT_a446_highSuctionSuperheat m446 : 51|1@1+ (1,0) [0|0] "" Vector__XXX
 SG_ VCFRONT_a474_fanStatus m474 : 51|1@1+ (1,0) [0|0] "" Vector__XXX
 SG_ VCFRONT_a475_fanStatus m475 : 51|1@1+ (1,0) [0|0] "" Vector__XXX
 SG_ VCFRONT_a511_DCDCOutputIsLimited m511 : 51|1@1+ (1,0) [0|0] "" Vector__XXX
 SG_ VCFRONT_a512_frunkOpen m512 : 51|1@1+ (1,0) [0|0] "" Vector__XXX
 SG_ VCFRONT_a559_serviceMode m559 : 51|1@1+ (1,0) [0|0] "" Vector__XXX
 SG_ VCFRONT_a623_failurePcsOpenCircuit m623 : 51|1@1+ (1,0) [0|0] "" Vector__XXX
 SG_ VCFRONT_a635_didCore2EverSleep m635 : 51|1@1+ (1,0) [0|0] "" Vector__XXX
 SG_ VCFRONT_a187_chBusRetryCount m187 : 52|9@1+ (1,0) [0|0] "" Vector__XXX
 SG_ VCFRONT_a188_SleepRequestTimeout m188 : 52|1@1+ (1,0) [0|0] "" Vector__XXX
 SG_ VCFRONT_a190_maxMessagePeriod m190 : 52|12@1+ (1,0) [0|0] "" Vector__XXX
 SG_ VCFRONT_a191_exitDriveWarningTimerExpired m191 : 52|1@1+ (1,0) [0|0] "" Vector__XXX
 SG_ VCFRONT_a248_voltageCalScaling m248 : 52|12@1+ (0.025,0) [0|0] "" Vector__XXX
 SG_ VCFRONT_a260_BMS_MIA m260 : 52|1@1+ (1,0) [0|0] "" Vector__XXX
 SG_ VCFRONT_a334_vehicleState m334 : 52|2@1+ (1,0) [0|0] "" Vector__XXX
 SG_ VCFRONT_a335_vehicleState m335 : 52|2@1+ (1,0) [0|0] "" Vector__XXX
 SG_ VCFRONT_a336_vehicleState m336 : 52|2@1+ (1,0) [0|0] "" Vector__XXX
 SG_ VCFRONT_a337_vehicleState m337 : 52|2@1+ (1,0) [0|0] "" Vector__XXX
 SG_ VCFRONT_a338_vehicleState m338 : 52|2@1+ (1,0) [0|0] "" Vector__XXX
 SG_ VCFRONT_a339_vehicleState m339 : 52|2@1+ (1,0) [0|0] "" Vector__XXX
 SG_ VCFRONT_a340_vehicleState m340 : 52|2@1+ (1,0) [0|0] "" Vector__XXX
 SG_ VCFRONT_a341_vehicleState m341 : 52|2@1+ (1,0) [0|0] "" Vector__XXX
 SG_ VCFRONT_a342_vehicleState m342 : 52|2@1+ (1,0) [0|0] "" Vector__XXX
 SG_ VCFRONT_a343_vehicleState m343 : 52|2@1+ (1,0) [0|0] "" Vector__XXX
 SG_ VCFRONT_a344_vehicleState m344 : 52|2@1+ (1,0) [0|0] "" Vector__XXX
 SG_ VCFRONT_a345_vehicleState m345 : 52|2@1+ (1,0) [0|0] "" Vector__XXX
 SG_ VCFRONT_a346_vehicleState m346 : 52|2@1+ (1,0) [0|0] "" Vector__XXX
 SG_ VCFRONT_a347_vehicleState m347 : 52|2@1+ (1,0) [0|0] "" Vector__XXX
 SG_ VCFRONT_a348_vehicleState m348 : 52|2@1+ (1,0) [0|0] "" Vector__XXX
 SG_ VCFRONT_a349_vehicleState m349 : 52|2@1+ (1,0) [0|0] "" Vector__XXX
 SG_ VCFRONT_a352_duration m352 : 52|10@1+ (1,0) [0|0] "" Vector__XXX
 SG_ VCFRONT_a359_crashDetected m359 : 52|1@1+ (1,0) [0|0] "" Vector__XXX
 SG_ VCFRONT_a370_SOC m370 : 52|3@1+ (2.5,5) [0|0] "" Vector__XXX
 SG_ VCFRONT_a391_switch2VoltageInstant m391 : 52|10@1+ (5,0) [0|0] "" Vector__XXX
 SG_ VCFRONT_a403_chargeTime m403 : 52|10@1+ (1,0) [0|0] "" Vector__XXX
 SG_ VCFRONT_a407_IBSTemperature m407 : 52|8@1+ (0.5,-30) [0|0] "" Vector__XXX
 SG_ VCFRONT_a446_evapLowPsCutout m446 : 52|1@1+ (1,0) [0|0] "" Vector__XXX
 SG_ VCFRONT_a463_switch2VoltageInstant m463 : 52|10@1+ (5,0) [0|0] "" Vector__XXX
 SG_ VCFRONT_a474_TPS92520_COMPOV m474 : 52|1@1+ (1,0) [0|0] "" Vector__XXX
 SG_ VCFRONT_a475_TPS92520_COMPOV m475 : 52|1@1+ (1,0) [0|0] "" Vector__XXX
 SG_ VCFRONT_a477_sumCellVoltage m477 : 52|8@1+ (0.1,0) [0|0] "" Vector__XXX
 SG_ VCFRONT_a484_headlampAimingDebugReason m484 : 52|3@1+ (1,0) [0|0] "" Vector__XXX
 SG_ VCFRONT_a502_shortImpedance m502 : 52|10@1+ (1,0) [0|0] "" Vector__XXX
 SG_ VCFRONT_a511_PCSSignalsAreValid m511 : 52|1@1+ (1,0) [0|0] "" Vector__XXX
 SG_ VCFRONT_a512_vehiclePowerState m512 : 52|2@1+ (1,0) [0|0] "" Vector__XXX
 SG_ VCFRONT_a514_packSOC m514 : 52|8@1+ (0.4,0) [0|0] "" Vector__XXX
 SG_ VCFRONT_a515_packSOC m515 : 52|8@1+ (0.4,0) [0|0] "" Vector__XXX
 SG_ VCFRONT_a559_transportMode m559 : 52|1@1+ (1,0) [0|0] "" Vector__XXX
 SG_ VCFRONT_a600_version m600 : 52|4@1+ (1,0) [0|0] "" Vector__XXX
 SG_ VCFRONT_a611_heatGenTotal m611 : 52|6@1+ (500,0) [0|0] "" Vector__XXX
 SG_ VCFRONT_a623_failureLvBatteryPowerActiveDecel m623 : 52|1@1+ (1,0) [0|0] "" Vector__XXX
 SG_ VCFRONT_a626_IBSTemperature m626 : 52|8@1+ (0.5,-30) [0|0] "" Vector__XXX
 SG_ VCFRONT_a627_sumCellVoltage m627 : 52|8@1+ (0.1,0) [0|0] "" Vector__XXX
 SG_ VCFRONT_a178_isInSilentMode m178 : 53|1@1+ (1,0) [0|0] "" Vector__XXX
 SG_ VCFRONT_a188_wakeUpMsgID m188 : 53|11@1+ (1,0) [0|0] "" Vector__XXX
 SG_ VCFRONT_a191_LVBMSMIA m191 : 53|1@1+ (1,0) [0|0] "" Vector__XXX
 SG_ VCFRONT_a260_PCS_MIA m260 : 53|1@1+ (1,0) [0|0] "" Vector__XXX
 SG_ VCFRONT_a359_BMS_MIA m359 : 53|1@1+ (1,0) [0|0] "" Vector__XXX
 SG_ VCFRONT_a405_intervalCurrentVariance m405 : 53|6@1+ (0.1,0) [0|0] "" Vector__XXX
 SG_ VCFRONT_a406_IBSTemperature m406 : 53|6@1+ (1,-3) [0|0] "" Vector__XXX
 SG_ VCFRONT_a408_standbyChargeProfileTime m408 : 53|10@1+ (1,0) [0|0] "" Vector__XXX
 SG_ VCFRONT_a428_modCacImbalancePct m428 : 53|10@1+ (0.1,0) [0|0] "" Vector__XXX
 SG_ VCFRONT_a446_batteryOverTemp m446 : 53|1@1+ (1,0) [0|0] "" Vector__XXX
 SG_ VCFRONT_a474_TPS92520_HSILIM m474 : 53|1@1+ (1,0) [0|0] "" Vector__XXX
 SG_ VCFRONT_a475_TPS92520_HSILIM m475 : 53|1@1+ (1,0) [0|0] "" Vector__XXX
 SG_ VCFRONT_a511_factoryGated m511 : 53|1@1+ (1,0) [0|0] "" Vector__XXX
 SG_ VCFRONT_a559_notEnoughPowerForSupport m559 : 53|1@1+ (1,0) [0|0] "" Vector__XXX
 SG_ VCFRONT_a561_cell4Voltage m561 : 53|7@1+ (0.04,0) [0|0] "" Vector__XXX
 SG_ VCFRONT_a562_cell4Voltage m562 : 53|7@1+ (0.04,0) [0|0] "" Vector__XXX
 SG_ VCFRONT_a623_failureLvBatteryCapabilityLowAccuracy m623 : 53|1@1+ (1,0) [0|0] "" Vector__XXX
 SG_ VCFRONT_a669_minPackTemperature m669 : 53|6@1+ (2,-40) [0|0] "" Vector__XXX
 SG_ VCFRONT_a178_isPsAvailable m178 : 54|1@1+ (1,0) [0|0] "" Vector__XXX
 SG_ VCFRONT_a184_recircDoorPercent m184 : 54|6@1+ (2,0) [0|0] "" Vector__XXX
 SG_ VCFRONT_a191_PCS_MIA m191 : 54|1@1+ (1,0) [0|0] "" Vector__XXX
 SG_ VCFRONT_a197_serviceMode m197 : 54|1@1+ (1,0) [0|0] "" Vector__XXX
 SG_ VCFRONT_a260_HVBlockingMismatch m260 : 54|1@1+ (1,0) [0|0] "" Vector__XXX
 SG_ VCFRONT_a359_PCS_MIA m359 : 54|1@1+ (1,0) [0|0] "" Vector__XXX
 SG_ VCFRONT_a414_IBSAmpHours m414 : 54|8@1+ (0.01,-2.55) [0|0] "" Vector__XXX
 SG_ VCFRONT_a415_vehiclePowerState m415 : 54|2@1+ (1,0) [0|0] "" Vector__XXX
 SG_ VCFRONT_a416_brickId m416 : 54|8@1+ (1,1) [0|0] "" Vector__XXX
 SG_ VCFRONT_a417_brickId m417 : 54|8@1+ (1,1) [0|0] "" Vector__XXX
 SG_ VCFRONT_a418_brickId m418 : 54|8@1+ (1,1) [0|0] "" Vector__XXX
 SG_ VCFRONT_a419_brickId m419 : 54|8@1+ (1,1) [0|0] "" Vector__XXX
 SG_ VCFRONT_a423_brickId m423 : 54|8@1+ (1,1) [0|0] "" Vector__XXX
 SG_ VCFRONT_a424_brickId m424 : 54|8@1+ (1,1) [0|0] "" Vector__XXX
 SG_ VCFRONT_a446_hvacSystemFault m446 : 54|1@1+ (1,0) [0|0] "" Vector__XXX
 SG_ VCFRONT_a474_TPS92520_BSTUV m474 : 54|1@1+ (1,0) [0|0] "" Vector__XXX
 SG_ VCFRONT_a475_TPS92520_BSTUV m475 : 54|1@1+ (1,0) [0|0] "" Vector__XXX
 SG_ VCFRONT_a498_measuredVoltage m498 : 54|10@1+ (0.05,0) [0|0] "" Vector__XXX
 SG_ VCFRONT_a503_brickId m503 : 54|8@1+ (1,1) [0|0] "" Vector__XXX
 SG_ VCFRONT_a511_vehicleIsUpdating m511 : 54|1@1+ (1,0) [0|0] "" Vector__XXX
 SG_ VCFRONT_a559_crashDetected m559 : 54|1@1+ (1,0) [0|0] "" Vector__XXX
 SG_ VCFRONT_a606_battLPMAtExit m606 : 54|5@1+ (1,0) [0|0] "" Vector__XXX
 SG_ VCFRONT_a623_failureLvBatteryConfiguration m623 : 54|1@1+ (1,0) [0|0] "" Vector__XXX
 SG_ VCFRONT_a663_hcmlGroupsHighWaterMarkPercent_IC700 m663 : 54|5@1+ (3.225806451612903,0) [0|0] "" Vector__XXX
 SG_ VCFRONT_a664_hcmrGroupsHighWaterMarkPercent_IC700 m664 : 54|5@1+ (3.225806451612903,0) [0|0] "" Vector__XXX
 SG_ VCFRONT_a178_isPdAvailable m178 : 55|1@1+ (1,0) [0|0] "" Vector__XXX
 SG_ VCFRONT_a182_calibrationLostFault m182 : 55|1@1+ (1,0) [0|0] "" Vector__XXX
 SG_ VCFRONT_a183_calibrationLostFault m183 : 55|1@1+ (1,0) [0|0] "" Vector__XXX
 SG_ VCFRONT_a191_NotEnoughPowerForSupport m191 : 55|1@1+ (1,0) [0|0] "" Vector__XXX
 SG_ VCFRONT_a197_frunkOpen m197 : 55|1@1+ (1,0) [0|0] "" Vector__XXX
 SG_ VCFRONT_a253_firstChargeOTA m253 : 55|1@1+ (1,0) [0|0] "" Vector__XXX
 SG_ VCFRONT_a260_serviceMode m260 : 55|1@1+ (1,0) [0|0] "" Vector__XXX
 SG_ VCFRONT_a359_serviceMode m359 : 55|1@1+ (1,0) [0|0] "" Vector__XXX
 SG_ VCFRONT_a446_coolantSysLockedOut m446 : 55|1@1+ (1,0) [0|0] "" Vector__XXX
 SG_ VCFRONT_a474_BoostRailStatus m474 : 55|1@1+ (1,0) [0|0] "" Vector__XXX
 SG_ VCFRONT_a475_BoostRailStatus m475 : 55|1@1+ (1,0) [0|0] "" Vector__XXX
 SG_ VCFRONT_a511_serviceMode m511 : 55|1@1+ (1,0) [0|0] "" Vector__XXX
 SG_ VCFRONT_a559_BMS_MIA m559 : 55|1@1+ (1,0) [0|0] "" Vector__XXX
 SG_ VCFRONT_a623_failureLvBatteryHighImpedance m623 : 55|1@1+ (1,0) [0|0] "" Vector__XXX
 SG_ VCFRONT_a009_LCCInletCoolantAtExit m9 : 56|6@1- (1,12) [0|0] "" Vector__XXX
 SG_ VCFRONT_a022_TaskInitError4 m22 : 56|8@1+ (1,0) [0|0] "" Vector__XXX
 SG_ VCFRONT_a031_uds_bytes_5 m31 : 56|8@1+ (1,0) [0|0] "" Vector__XXX
 SG_ VCFRONT_a041_CPULoadNVMMTask m41 : 56|8@1+ (1,0) [0|0] "" Vector__XXX
 SG_ VCFRONT_a042_UsageNVMMTask m42 : 56|8@1+ (1,0) [0|0] "" Vector__XXX
 SG_ VCFRONT_a047_CsvRef m47 : 56|1@1+ (1,0) [0|0] "" Vector__XXX
 SG_ VCFRONT_a154_minVoltageAlignedDcrMilliOhms m154 : 56|8@1+ (1,0) [0|0] "" Vector__XXX
 SG_ VCFRONT_a155_minCurrentAlignedDcrMilliOhms m155 : 56|8@1+ (1,0) [0|0] "" Vector__XXX
 SG_ VCFRONT_a178_isAmbientAvailable m178 : 56|1@1+ (1,0) [0|0] "" Vector__XXX
 SG_ VCFRONT_a180_targetPCSVoltage m180 : 56|8@1+ (0.1,0) [0|0] "" Vector__XXX
 SG_ VCFRONT_a182_samplingHWError m182 : 56|1@1+ (1,0) [0|0] "" Vector__XXX
 SG_ VCFRONT_a183_samplingHWError m183 : 56|1@1+ (1,0) [0|0] "" Vector__XXX
 SG_ VCFRONT_a191_bmsState m191 : 56|4@1+ (1,0) [0|0] "" Vector__XXX
 SG_ VCFRONT_a192_HVFaultLoadShedActive m192 : 56|1@1+ (1,0) [0|0] "" Vector__XXX
 SG_ VCFRONT_a196_ECPAState m196 : 56|2@1+ (1,0) [0|0] "" Vector__XXX
 SG_ VCFRONT_a197_dcrMilliOhmsFiltered m197 : 56|8@1+ (1,0) [0|0] "" Vector__XXX
 SG_ VCFRONT_a242_vehiclePowerState m242 : 56|2@1+ (1,0) [0|0] "" Vector__XXX
 SG_ VCFRONT_a253_firstChargePOR m253 : 56|1@1+ (1,0) [0|0] "" Vector__XXX
 SG_ VCFRONT_a260_dcdcLVSupportStatus m260 : 56|2@1+ (1,0) [0|0] "" Vector__XXX
 SG_ VCFRONT_a269_vehiclePowerState m269 : 56|2@1+ (1,0) [0|0] "" Vector__XXX
 SG_ VCFRONT_a359_dcdcLVSupportStatus m359 : 56|2@1+ (1,0) [0|0] "" Vector__XXX
 SG_ VCFRONT_a363_minBleedChargeBrickId m363 : 56|5@1+ (1,1) [0|0] "" Vector__XXX
 SG_ VCFRONT_a379_testFailed m379 : 56|1@1+ (1,0) [0|0] "" Vector__XXX
 SG_ VCFRONT_a412_pulseCurrentVarianceShifted m412 : 56|6@1+ (0.25,0) [0|0] "" Vector__XXX
 SG_ VCFRONT_a415_HV_UP m415 : 56|1@1+ (1,0) [0|0] "" Vector__XXX
 SG_ VCFRONT_a421_hcmlReadBufferHighWaterMarkPercent m421 : 56|5@1+ (3.225806451612903,0) [0|0] "" Vector__XXX
 SG_ VCFRONT_a427_cacUpdateError m427 : 56|8@1+ (0.1,0) [0|0] "" Vector__XXX
 SG_ VCFRONT_a429_testType m429 : 56|1@1+ (1,0) [0|0] "" Vector__XXX
 SG_ VCFRONT_a446_refSysLockedOut m446 : 56|1@1+ (1,0) [0|0] "" Vector__XXX
 SG_ VCFRONT_a474_EEPROM_DataStatus m474 : 56|1@1+ (1,0) [0|0] "" Vector__XXX
 SG_ VCFRONT_a475_EEPROM_DataStatus m475 : 56|1@1+ (1,0) [0|0] "" Vector__XXX
 SG_ VCFRONT_a482_previousAimedPositionValid m482 : 56|1@1+ (1,0) [0|0] "" Vector__XXX
 SG_ VCFRONT_a484_leftHeadlampMigrationState m484 : 56|2@1+ (1,0) [0|0] "" Vector__XXX
 SG_ VCFRONT_a485_previousAimedPositionValid m485 : 56|1@1+ (1,0) [0|0] "" Vector__XXX
 SG_ VCFRONT_a493_avgBrickSoc m493 : 56|7@1+ (1,0) [0|0] "" Vector__XXX
 SG_ VCFRONT_a497_frunkOpen m497 : 56|1@1+ (1,0) [0|0] "" Vector__XXX
 SG_ VCFRONT_a511_frunkOpen m511 : 56|1@1+ (1,0) [0|0] "" Vector__XXX
 SG_ VCFRONT_a523_control3Byte3 m523 : 56|8@1+ (1,0) [0|0] "" Vector__XXX
 SG_ VCFRONT_a527_serviceMode m527 : 56|1@1+ (1,0) [0|0] "" Vector__XXX
 SG_ VCFRONT_a541_SOC m541 : 56|7@1+ (1,0) [0|0] "" Vector__XXX
 SG_ VCFRONT_a542_inFactoryMode m542 : 56|1@1+ (1,0) [0|0] "" Vector__XXX
 SG_ VCFRONT_a548_ampHourBucketFilled m548 : 56|1@1+ (1,0) [0|0] "" Vector__XXX
 SG_ VCFRONT_a559_PCS_MIA m559 : 56|1@1+ (1,0) [0|0] "" Vector__XXX
 SG_ VCFRONT_a585_inFactoryMode m585 : 56|1@1+ (1,0) [0|0] "" Vector__XXX
 SG_ VCFRONT_a623_failureLvBatteryExtendedOverVoltage m623 : 56|1@1+ (1,0) [0|0] "" Vector__XXX
 SG_ VCFRONT_a643_hcmrReadBufferHighWaterMarkPercent m643 : 56|5@1+ (3.225806451612903,0) [0|0] "" Vector__XXX
 SG_ VCFRONT_a646_fluidSuccessPercent m646 : 56|8@1+ (1,0) [0|0] "" Vector__XXX
 SG_ VCFRONT_a047_uds m47 : 57|1@1+ (1,0) [0|0] "" Vector__XXX
 SG_ VCFRONT_a162_recircExvFlow m162 : 57|7@1+ (1,0) [0|0] "" Vector__XXX
 SG_ VCFRONT_a178_hpMode m178 : 57|5@1+ (1,0) [0|0] "" Vector__XXX
 SG_ VCFRONT_a182_brickOverDischarged m182 : 57|1@1+ (1,0) [0|0] "" Vector__XXX
 SG_ VCFRONT_a183_brickOverDischarged m183 : 57|1@1+ (1,0) [0|0] "" Vector__XXX
 SG_ VCFRONT_a192_postCrashLoadShedActive m192 : 57|1@1+ (1,0) [0|0] "" Vector__XXX
 SG_ VCFRONT_a253_serviceMode m253 : 57|1@1+ (1,0) [0|0] "" Vector__XXX
 SG_ VCFRONT_a379_testCompleted m379 : 57|1@1+ (1,0) [0|0] "" Vector__XXX
 SG_ VCFRONT_a415_hvUpFirstTrigger m415 : 57|1@1+ (1,0) [0|0] "" Vector__XXX
 SG_ VCFRONT_a429_totalDuration m429 : 57|6@1+ (1,-1) [0|0] "" Vector__XXX
 SG_ VCFRONT_a446_chillerEXVNotReady m446 : 57|1@1+ (1,0) [0|0] "" Vector__XXX
 SG_ VCFRONT_a474_LMMVariant m474 : 57|2@1+ (1,0) [0|0] "" Vector__XXX
 SG_ VCFRONT_a475_LMMVariant m475 : 57|2@1+ (1,0) [0|0] "" Vector__XXX
 SG_ VCFRONT_a482_rangeValid m482 : 57|1@1+ (1,0) [0|0] "" Vector__XXX
 SG_ VCFRONT_a485_rangeValid m485 : 57|1@1+ (1,0) [0|0] "" Vector__XXX
 SG_ VCFRONT_a527_frunkOpen m527 : 57|1@1+ (1,0) [0|0] "" Vector__XXX
 SG_ VCFRONT_a542_inServiceMode m542 : 57|1@1+ (1,0) [0|0] "" Vector__XXX
 SG_ VCFRONT_a548_HVNotConfirmedUpTrigger m548 : 57|1@1+ (1,0) [0|0] "" Vector__XXX
 SG_ VCFRONT_a559_HVBlockingMismatch m559 : 57|1@1+ (1,0) [0|0] "" Vector__XXX
 SG_ VCFRONT_a585_inServiceMode m585 : 57|1@1+ (1,0) [0|0] "" Vector__XXX
 SG_ VCFRONT_a623_factoryMode m623 : 57|1@1+ (1,0) [0|0] "" Vector__XXX
 SG_ VCFRONT_a047_SingleCoreM4_M7_0 m47 : 58|1@1+ (1,0) [0|0] "" Vector__XXX
 SG_ VCFRONT_a182_impedanceGrowth m182 : 58|1@1+ (1,0) [0|0] "" Vector__XXX
 SG_ VCFRONT_a183_impedanceGrowth m183 : 58|1@1+ (1,0) [0|0] "" Vector__XXX
 SG_ VCFRONT_a253_frunkOpen m253 : 58|1@1+ (1,0) [0|0] "" Vector__XXX
 SG_ VCFRONT_a260_PCSAndVCREFuseStable m260 : 58|1@1+ (1,0) [0|0] "" Vector__XXX
 SG_ VCFRONT_a359_bmsState m359 : 58|4@1+ (1,0) [0|0] "" Vector__XXX
 SG_ VCFRONT_a379_maxCurrentReached m379 : 58|6@1+ (1,-63) [0|0] "" Vector__XXX
 SG_ VCFRONT_a415_hvUpAnyTrigger m415 : 58|1@1+ (1,0) [0|0] "" Vector__XXX
 SG_ VCFRONT_a446_CCLEXVNotReady m446 : 58|1@1+ (1,0) [0|0] "" Vector__XXX
 SG_ VCFRONT_a481_currentSenseFinished m481 : 58|1@1+ (1,0) [0|0] "" Vector__XXX
 SG_ VCFRONT_a484_rightHeadlampMigrationState m484 : 58|2@1+ (1,0) [0|0] "" Vector__XXX
 SG_ VCFRONT_a513_serviceMode m513 : 58|1@1+ (1,0) [0|0] "" Vector__XXX
 SG_ VCFRONT_a542_isCommissioned m542 : 58|1@1+ (1,0) [0|0] "" Vector__XXX
 SG_ VCFRONT_a548_PCSNotMeetingTargetTrigger m548 : 58|1@1+ (1,0) [0|0] "" Vector__XXX
 SG_ VCFRONT_a559_HV_UP m559 : 58|1@1+ (1,0) [0|0] "" Vector__XXX
 SG_ VCFRONT_a585_inTransportMode m585 : 58|1@1+ (1,0) [0|0] "" Vector__XXX
 SG_ VCFRONT_a611_radCoolantToAirUAEst m611 : 58|6@1+ (20,0) [0|0] "" Vector__XXX
 SG_ VCFRONT_a623_serviceMode m623 : 58|1@1+ (1,0) [0|0] "" Vector__XXX
 SG_ VCFRONT_a047_SingleCoreM7_1 m47 : 59|1@1+ (1,0) [0|0] "" Vector__XXX
 SG_ VCFRONT_a127_vcleftEFuseRemainingRetries m127 : 59|4@1+ (1,0) [0|0] "" Vector__XXX
 SG_ VCFRONT_a128_vcrightEFuseRemainingRetries m128 : 59|4@1+ (1,0) [0|0] "" Vector__XXX
 SG_ VCFRONT_a129_pcsEFuseRemainingRetries m129 : 59|4@1+ (1,0) [0|0] "" Vector__XXX
 SG_ VCFRONT_a134_vbatFusedEFuseRemainingRetries m134 : 59|4@1+ (1,0) [0|0] "" Vector__XXX
 SG_ VCFRONT_a182_batteryType m182 : 59|3@1+ (1,0) [0|0] "" Vector__XXX
 SG_ VCFRONT_a183_batteryType m183 : 59|3@1+ (1,0) [0|0] "" Vector__XXX
 SG_ VCFRONT_a260_bmsState m260 : 59|4@1+ (1,0) [0|0] "" Vector__XXX
 SG_ VCFRONT_a405_testCounter m405 : 59|2@1+ (1,0) [0|0] "" Vector__XXX
 SG_ VCFRONT_a406_testValid m406 : 59|1@1+ (1,0) [0|0] "" Vector__XXX
 SG_ VCFRONT_a415_pcsEFuseUnstable m415 : 59|1@1+ (1,0) [0|0] "" Vector__XXX
 SG_ VCFRONT_a446_CCREXVNotReady m446 : 59|1@1+ (1,0) [0|0] "" Vector__XXX
 SG_ VCFRONT_a474_headlampECURevision m474 : 59|4@1+ (1,0) [0|0] "" Vector__XXX
 SG_ VCFRONT_a475_headlampECURevision m475 : 59|4@1+ (1,0) [0|0] "" Vector__XXX
 SG_ VCFRONT_a481_currentSenseFailure m481 : 59|1@1+ (1,0) [0|0] "" Vector__XXX
 SG_ VCFRONT_a513_frunkOpen m513 : 59|1@1+ (1,0) [0|0] "" Vector__XXX
 SG_ VCFRONT_a518_serviceMode m518 : 59|1@1+ (1,0) [0|0] "" Vector__XXX
 SG_ VCFRONT_a548_PCSMIATrigger m548 : 59|1@1+ (1,0) [0|0] "" Vector__XXX
 SG_ VCFRONT_a559_pcsEFuseStable m559 : 59|1@1+ (1,0) [0|0] "" Vector__XXX
 SG_ VCFRONT_a585_uiMia m585 : 59|1@1+ (1,0) [0|0] "" Vector__XXX
 SG_ VCFRONT_a606_timeInMode m606 : 59|5@1+ (1,0) [0|0] "" Vector__XXX
 SG_ VCFRONT_a663_hcmlValidatedGroupsHighWaterMarkPercent_IC700 m663 : 59|5@1+ (3.225806451612903,0) [0|0] "" Vector__XXX
 SG_ VCFRONT_a664_hcmrValidatedGroupsHighWaterMarkPercent_IC700 m664 : 59|5@1+ (3.225806451612903,0) [0|0] "" Vector__XXX
 SG_ VCFRONT_a669_ambientTempFiltered m669 : 59|5@1+ (3,-40) [0|0] "" Vector__XXX
 SG_ VCFRONT_a047_SingleCoreFailed m47 : 60|1@1+ (1,0) [0|0] "" Vector__XXX
 SG_ VCFRONT_a184_systemAbnormal m184 : 60|1@1+ (1,0) [0|0] "" Vector__XXX
 SG_ VCFRONT_a258_lowCapacity m258 : 60|1@1+ (1,0) [0|0] "" Vector__XXX
 SG_ VCFRONT_a406_opportunisticTest m406 : 60|1@1+ (1,0) [0|0] "" Vector__XXX
 SG_ VCFRONT_a407_testCounter m407 : 60|2@1+ (1,0) [0|0] "" Vector__XXX
 SG_ VCFRONT_a415_vcrightEfuseUnstable m415 : 60|1@1+ (1,0) [0|0] "" Vector__XXX
 SG_ VCFRONT_a446_LCCEXVNotReady m446 : 60|1@1+ (1,0) [0|0] "" Vector__XXX
 SG_ VCFRONT_a477_deepDischargeFlag m477 : 60|1@1+ (1,0) [0|0] "" Vector__XXX
 SG_ VCFRONT_a513_vehiclePowerState m513 : 60|2@1+ (1,0) [0|0] "" Vector__XXX
 SG_ VCFRONT_a514_serviceMode m514 : 60|1@1+ (1,0) [0|0] "" Vector__XXX
 SG_ VCFRONT_a515_serviceMode m515 : 60|1@1+ (1,0) [0|0] "" Vector__XXX
 SG_ VCFRONT_a518_frunkOpen m518 : 60|1@1+ (1,0) [0|0] "" Vector__XXX
 SG_ VCFRONT_a548_PCSSaturatedTrigger m548 : 60|1@1+ (1,0) [0|0] "" Vector__XXX
 SG_ VCFRONT_a559_vcrightEFuseStable m559 : 60|1@1+ (1,0) [0|0] "" Vector__XXX
 SG_ VCFRONT_a561_factoryMode m561 : 60|1@1+ (1,0) [0|0] "" Vector__XXX
 SG_ VCFRONT_a562_factoryMode m562 : 60|1@1+ (1,0) [0|0] "" Vector__XXX
 SG_ VCFRONT_a585_frunkOpen m585 : 60|1@1+ (1,0) [0|0] "" Vector__XXX
 SG_ VCFRONT_a594_fusionSessionSampleCount m594 : 60|4@1+ (16,0) [0|0] "" Vector__XXX
 SG_ VCFRONT_a626_testCounter m626 : 60|2@1+ (1,0) [0|0] "" Vector__XXX
 SG_ VCFRONT_a627_deepDischargeFlag m627 : 60|1@1+ (1,0) [0|0] "" Vector__XXX
 SG_ VCFRONT_a047_IpcWatchdog m47 : 61|1@1+ (1,0) [0|0] "" Vector__XXX
 SG_ VCFRONT_a258_completed m258 : 61|1@1+ (1,0) [0|0] "" Vector__XXX
 SG_ VCFRONT_a363_setFromNvm m363 : 61|1@1+ (1,0) [0|0] "" Vector__XXX
 SG_ VCFRONT_a405_overchargeTrigger m405 : 61|1@1+ (1,0) [0|0] "" Vector__XXX
 SG_ VCFRONT_a406_disconnectedBatteryTestTrigger m406 : 61|1@1+ (1,0) [0|0] "" Vector__XXX
 SG_ VCFRONT_a415_vcleftEfuseUnstable m415 : 61|1@1+ (1,0) [0|0] "" Vector__XXX
 SG_ VCFRONT_a446_evapEXVNotReady m446 : 61|1@1+ (1,0) [0|0] "" Vector__XXX
 SG_ VCFRONT_a477_serviceMode m477 : 61|1@1+ (1,0) [0|0] "" Vector__XXX
 SG_ VCFRONT_a514_frunkOpen m514 : 61|1@1+ (1,0) [0|0] "" Vector__XXX
 SG_ VCFRONT_a515_frunkOpen m515 : 61|1@1+ (1,0) [0|0] "" Vector__XXX
 SG_ VCFRONT_a518_vehiclePowerState m518 : 61|2@1+ (1,0) [0|0] "" Vector__XXX
 SG_ VCFRONT_a548_backstopHit m548 : 61|1@1+ (1,0) [0|0] "" Vector__XXX
 SG_ VCFRONT_a559_contactorEFuseStable m559 : 61|1@1+ (1,0) [0|0] "" Vector__XXX
 SG_ VCFRONT_a561_serviceMode m561 : 61|1@1+ (1,0) [0|0] "" Vector__XXX
 SG_ VCFRONT_a562_serviceMode m562 : 61|1@1+ (1,0) [0|0] "" Vector__XXX
 SG_ VCFRONT_a585_leftRailVoltageLow m585 : 61|1@1+ (1,0) [0|0] "" Vector__XXX
 SG_ VCFRONT_a627_serviceMode m627 : 61|1@1+ (1,0) [0|0] "" Vector__XXX
 SG_ VCFRONT_a178_runDueToHpCommissioning m178 : 62|1@1+ (1,0) [0|0] "" Vector__XXX
 SG_ VCFRONT_a182_bleedFetTestFailure m182 : 62|1@1+ (1,0) [0|0] "" Vector__XXX
 SG_ VCFRONT_a183_bleedFetTestFailure m183 : 62|1@1+ (1,0) [0|0] "" Vector__XXX
 SG_ VCFRONT_a403_firstChargeOTA m403 : 62|1@1+ (1,0) [0|0] "" Vector__XXX
 SG_ VCFRONT_a405_voltDropOnHighCurrentTrigger m405 : 62|1@1+ (1,0) [0|0] "" Vector__XXX
 SG_ VCFRONT_a406_maxChargeTimeoutTrigger m406 : 62|1@1+ (1,0) [0|0] "" Vector__XXX
 SG_ VCFRONT_a407_testingExpended m407 : 62|1@1+ (1,0) [0|0] "" Vector__XXX
 SG_ VCFRONT_a412_serviceMode m412 : 62|1@1+ (1,0) [0|0] "" Vector__XXX
 SG_ VCFRONT_a414_vehiclePowerState m414 : 62|2@1+ (1,0) [0|0] "" Vector__XXX
 SG_ VCFRONT_a415_contactorEFuseUnstable m415 : 62|1@1+ (1,0) [0|0] "" Vector__XXX
 SG_ VCFRONT_a446_recircEXVNotReady m446 : 62|1@1+ (1,0) [0|0] "" Vector__XXX
 SG_ VCFRONT_a477_frunkOpen m477 : 62|1@1+ (1,0) [0|0] "" Vector__XXX
 SG_ VCFRONT_a514_vehiclePowerState m514 : 62|2@1+ (1,0) [0|0] "" Vector__XXX
 SG_ VCFRONT_a515_vehiclePowerState m515 : 62|2@1+ (1,0) [0|0] "" Vector__XXX
 SG_ VCFRONT_a559_hvcEFuseStable m559 : 62|1@1+ (1,0) [0|0] "" Vector__XXX
 SG_ VCFRONT_a561_frunkOpen m561 : 62|1@1+ (1,0) [0|0] "" Vector__XXX
 SG_ VCFRONT_a562_frunkOpen m562 : 62|1@1+ (1,0) [0|0] "" Vector__XXX
 SG_ VCFRONT_a585_rightRailVoltageLow m585 : 62|1@1+ (1,0) [0|0] "" Vector__XXX
 SG_ VCFRONT_a626_testingExpended m626 : 62|1@1+ (1,0) [0|0] "" Vector__XXX
 SG_ VCFRONT_a627_frunkOpen m627 : 62|1@1+ (1,0) [0|0] "" Vector__XXX
 SG_ VCFRONT_a058_faultReason m58 : 63|1@1+ (1,0) [0|0] "" Vector__XXX
 SG_ VCFRONT_a172_serviceMode m172 : 63|1@1+ (1,0) [0|0] "" Vector__XXX
 SG_ VCFRONT_a173_serviceMode m173 : 63|1@1+ (1,0) [0|0] "" Vector__XXX
 SG_ VCFRONT_a182_weakShort m182 : 63|1@1+ (1,0) [0|0] "" Vector__XXX
 SG_ VCFRONT_a183_weakShort m183 : 63|1@1+ (1,0) [0|0] "" Vector__XXX
 SG_ VCFRONT_a403_IBSTempShortOrOpen m403 : 63|1@1+ (1,0) [0|0] "" Vector__XXX
 SG_ VCFRONT_a405_voltageDipTrigger m405 : 63|1@1+ (1,0) [0|0] "" Vector__XXX
 SG_ VCFRONT_a406_voltageFloorReachedTrigger m406 : 63|1@1+ (1,0) [0|0] "" Vector__XXX
 SG_ VCFRONT_a407_opportunisticTest m407 : 63|1@1+ (1,0) [0|0] "" Vector__XXX
 SG_ VCFRONT_a408_IBSTempShortOrOpen m408 : 63|1@1+ (1,0) [0|0] "" Vector__XXX
 SG_ VCFRONT_a412_frunkOpen m412 : 63|1@1+ (1,0) [0|0] "" Vector__XXX
 SG_ VCFRONT_a415_hvcEFuseUnstable m415 : 63|1@1+ (1,0) [0|0] "" Vector__XXX
 SG_ VCFRONT_a446_checkA447Alert m446 : 63|1@1+ (1,0) [0|0] "" Vector__XXX
 SG_ VCFRONT_a559_frunkOpen m559 : 63|1@1+ (1,0) [0|0] "" Vector__XXX
 SG_ VCFRONT_a626_opportunisticTest m626 : 63|1@1+ (1,0) [0|0] "" Vector__XXX

BO_ 1337 DAS_info: 8 Vector__XXX
 SG_ DAS_infoIndex M : 0|8@1+ (1,0) [0|0] "" Vector__XXX
 SG_ DAS_infoAppGitHashBytes m17 : 8|56@1+ (1,0) [0|0] "" Vector__XXX
 SG_ DAS_infoBootGitHashBytes m18 : 8|56@1+ (1,0) [0|0] "" Vector__XXX
 SG_ DAS_infoBootUdsProtoVersion m20 : 8|8@1+ (1,0) [0|0] "" Vector__XXX
 SG_ DAS_infoBootloaderSvnRevision m14 : 8|24@1+ (1,0) [0|0] "" Vector__XXX
 SG_ DAS_infoBuildType m10 : 8|8@1+ (1,0) [0|0] "" Vector__XXX
 SG_ DAS_infoPlatformType m19 : 8|8@1+ (1,0) [0|0] "" Vector__XXX
 SG_ DAS_infoBuildConfigID m10 : 16|16@1+ (1,0) [0|0] "" Vector__XXX
 SG_ DAS_infoEyeQAppCRC m23 : 16|32@1+ (1,0) [0|0] "" Vector__XXX
 SG_ DAS_infoEyeQBootCRC m16 : 16|32@1+ (1,0) [0|0] "" Vector__XXX
 SG_ DAS_infoEyeQFfsCRC m24 : 16|32@1+ (1,0) [0|0] "" Vector__XXX
 SG_ DAS_infoMajorVersion m19 : 16|8@1+ (1,0) [0|0] "" Vector__XXX
 SG_ DAS_infoPcbaID m11 : 16|8@1+ (1,0) [0|0] "" Vector__XXX
 SG_ DAS_infoAssemblyID m11 : 24|8@1+ (1,0) [0|0] "" Vector__XXX
 SG_ DAS_infoBranchOrigin m19 : 24|8@1+ (1,0) [0|0] "" Vector__XXX
 SG_ DAS_infoApplicationCRC m13 : 32|32@1+ (1,0) [0|0] "" Vector__XXX
 SG_ DAS_infoBootloaderCRC m20 : 32|32@1+ (1,0) [0|0] "" Vector__XXX
 SG_ DAS_infoHardwareID m10 : 32|16@1+ (1,0) [0|0] "" Vector__XXX
 SG_ DAS_infoMaturity m19 : 32|8@1+ (1,0) [0|0] "" Vector__XXX
 SG_ DAS_infoUsageID m11 : 32|16@1+ (1,0) [0|0] "" Vector__XXX
 SG_ DAS_infoHardwareRevision m19 : 40|8@1+ (1,0) [0|0] "" Vector__XXX
 SG_ DAS_infoComponentID m10 : 48|16@1+ (1,0) [0|0] "" Vector__XXX
 SG_ DAS_infoSubUsageID m11 : 48|16@1+ (1,0) [0|0] "" Vector__XXX

BO_ 1352 APB_info: 8 Vector__XXX
 SG_ APB_infoIndex M : 0|8@1+ (1,0) [0|0] "" Vector__XXX
 SG_ APB_bootCount m3 : 8|32@1+ (1,0) [0|0] "" Vector__XXX
 SG_ APB_buildType m0 : 8|8@1+ (1,0) [0|0] "" Vector__XXX
 SG_ APB_infoApbApGitHashBytes m2 : 8|56@1+ (1,0) [0|0] "" Vector__XXX
 SG_ APB_infoApbFwGitHashBytes m1 : 8|56@1+ (1,0) [0|0] "" Vector__XXX

BO_ 1353 APP_info: 8 Vector__XXX
 SG_ APP_infoIndex M : 0|8@1+ (1,0) [0|0] "" Vector__XXX
 SG_ APP_bootCount m3 : 8|32@1+ (1,0) [0|0] "" Vector__XXX
 SG_ APP_buildType m0 : 8|8@1+ (1,0) [0|0] "" Vector__XXX
 SG_ APP_infoAppApGitHashBytes m2 : 8|56@1+ (1,0) [0|0] "" Vector__XXX
 SG_ APP_infoAppFwGitHashBytes m1 : 8|56@1+ (1,0) [0|0] "" Vector__XXX

BO_ 1361 EPAS3S_bootID: 8 Vector__XXX
 SG_ EPAS3S_bootIdData : 0|64@1+ (1,0) [0|0] "" Vector__XXX

BO_ 1365 RADC_alertLog: 8 Vector__XXX
 SG_ RADC_alertID M : 0|6@1+ (1,0) [0|0] "" Vector__XXX
 SG_ RADC_alertState : 15|1@1+ (1,0) [0|0] "" Vector__XXX
 SG_ RADC_a002_ecuAdcErrType m2 : 16|8@1+ (1,0) [0|0] "" Vector__XXX
 SG_ RADC_a008_interLockErrType m8 : 16|8@1+ (1,0) [0|0] "" Vector__XXX
 SG_ RADC_a011_ecuMcemErrType m11 : 16|8@1+ (1,0) [0|0] "" Vector__XXX
 SG_ RADC_a013_ecuWdgErrType m13 : 16|8@1+ (1,0) [0|0] "" Vector__XXX
 SG_ RADC_a016_adcOverVoltType m16 : 16|8@1+ (1,0) [0|0] "" Vector__XXX
 SG_ RADC_a017_adcUnderVoltType m17 : 16|8@1+ (1,0) [0|0] "" Vector__XXX
 SG_ RADC_a019_internalSWFaultType m19 : 16|8@1+ (1,0) [0|0] "" Vector__XXX
 SG_ RADC_a020_ecuTemp m20 : 16|16@1+ (0.1,-44) [0|0] "" Vector__XXX
 SG_ RADC_a023_ecuTemp m23 : 16|16@1+ (0.1,-44) [0|0] "" Vector__XXX
 SG_ RADC_a025_ecuVoltage m25 : 16|8@1+ (0.1,0) [0|0] "" Vector__XXX
 SG_ RADC_a026_ecuVoltage m26 : 16|8@1+ (0.1,0) [0|0] "" Vector__XXX
 SG_ RADC_a027_nvmFailureType m27 : 16|8@1+ (1,0) [0|0] "" Vector__XXX
 SG_ RADC_a028_rfComRegCheckFail m28 : 16|8@1+ (1,0) [0|0] "" Vector__XXX
 SG_ RADC_a029_rhcChirpMonErrType m29 : 16|8@1+ (1,0) [0|0] "" Vector__XXX
 SG_ RADC_a030_rspErrType m30 : 16|8@1+ (1,0) [0|0] "" Vector__XXX
 SG_ RADC_a031_horizMisalignAngle m31 : 16|8@1+ (0.001953125,-0.25) [0|0] "" Vector__XXX
 SG_ RADC_a032_blockageType m32 : 16|8@1+ (1,0) [0|0] "" Vector__XXX
 SG_ RADC_a034_vehDynamicsErrorType m34 : 16|8@1+ (1,0) [0|0] "" Vector__XXX
 SG_ RADC_a035_msgId m35 : 16|12@1+ (1,0) [0|0] "" Vector__XXX
 SG_ RADC_a036_msgId m36 : 16|12@1+ (1,0) [0|0] "" Vector__XXX
 SG_ RADC_a037_msgId m37 : 16|12@1+ (1,0) [0|0] "" Vector__XXX
 SG_ RADC_a038_msgId m38 : 16|12@1+ (1,0) [0|0] "" Vector__XXX
 SG_ RADC_a039_msgId m39 : 16|12@1+ (1,0) [0|0] "" Vector__XXX
 SG_ RADC_a040_msgId m40 : 16|12@1+ (1,0) [0|0] "" Vector__XXX
 SG_ RADC_a041_vinErrType m41 : 16|4@1+ (1,0) [0|0] "" Vector__XXX
 SG_ RADC_a042_carConfigErrType m42 : 16|4@1+ (1,0) [0|0] "" Vector__XXX
 SG_ RADC_a043_inertialSignalsErrType m43 : 16|4@1+ (1,0) [0|0] "" Vector__XXX
 SG_ RADC_a044_stwAngleErrType m44 : 16|4@1+ (1,0) [0|0] "" Vector__XXX
 SG_ RADC_a045_vehicleStateErrType m45 : 16|4@1+ (1,0) [0|0] "" Vector__XXX
 SG_ RADC_a046_wheelSpeedsErrType m46 : 16|4@1+ (1,0) [0|0] "" Vector__XXX
 SG_ RADC_a047_chassisTypeExp m47 : 16|8@1+ (1,0) [0|0] "" Vector__XXX
 SG_ RADC_a048_airSuspensionExp m48 : 16|8@1+ (1,0) [0|0] "" Vector__XXX
 SG_ RADC_a049_fourWheelDriveExp m49 : 16|8@1+ (1,0) [0|0] "" Vector__XXX
 SG_ RADC_a050_countryExp m50 : 16|16@1+ (1,0) [0|0] "" Vector__XXX
 SG_ RADC_a051_epasTypeExp m51 : 16|8@1+ (1,0) [0|0] "" Vector__XXX
 SG_ RADC_a052_radarPositionExp m52 : 16|8@1+ (1,0) [0|0] "" Vector__XXX
 SG_ RADC_a053_emError_LatYawRate m53 : 16|1@1+ (1,0) [0|0] "" Vector__XXX
 SG_ RADC_a054_block_ucObjLossProb m54 : 16|8@1+ (1,0) [0|0] "" Vector__XXX
 SG_ RADC_a055_block_usTimeoutWayCnt m55 : 16|16@1+ (1,0) [0|0] "" Vector__XXX
 SG_ RADC_a053_emError_EGOAccelState m53 : 17|1@1+ (1,0) [0|0] "" Vector__XXX
 SG_ RADC_a053_emError_EGOMotionState m53 : 18|1@1+ (1,0) [0|0] "" Vector__XXX
 SG_ RADC_a053_emError_EGOCurveState m53 : 19|1@1+ (1,0) [0|0] "" Vector__XXX
 SG_ RADC_a041_vinErrExp m41 : 20|16@1+ (1,0) [0|0] "" Vector__XXX
 SG_ RADC_a042_carConfigErrExp m42 : 20|16@1+ (1,0) [0|0] "" Vector__XXX
 SG_ RADC_a043_inertialSignalsErrExp m43 : 20|16@1+ (1,0) [0|0] "" Vector__XXX
 SG_ RADC_a044_stwAngleErrExp m44 : 20|16@1+ (1,0) [0|0] "" Vector__XXX
 SG_ RADC_a045_vehicleStateErrExp m45 : 20|16@1+ (1,0) [0|0] "" Vector__XXX
 SG_ RADC_a046_wheelSpeedsErrExp m46 : 20|16@1+ (1,0) [0|0] "" Vector__XXX
 SG_ RADC_a053_emError_EGOSpeedState m53 : 20|1@1+ (1,0) [0|0] "" Vector__XXX
 SG_ RADC_a053_emError_EGOSpeedCorrSt m53 : 21|1@1+ (1,0) [0|0] "" Vector__XXX
 SG_ RADC_a053_emError_MountVertPos m53 : 22|1@1+ (1,0) [0|0] "" Vector__XXX
 SG_ RADC_a053_emError_MountLongPos m53 : 23|1@1+ (1,0) [0|0] "" Vector__XXX
 SG_ RADC_a016_adcVoltage m16 : 24|6@1+ (0.1,0) [0|0] "" Vector__XXX
 SG_ RADC_a017_adcVoltage m17 : 24|6@1+ (0.1,0) [0|0] "" Vector__XXX
 SG_ RADC_a019_internalSWFaultCoreID m19 : 24|4@1+ (1,0) [0|0] "" Vector__XXX
 SG_ RADC_a029_rhcRxLongTermErrType m29 : 24|8@1+ (1,0) [0|0] "" Vector__XXX
 SG_ RADC_a031_vertMisalignAngle m31 : 24|12@1+ (0.0001220703125,-0.25) [0|0] "" Vector__XXX
 SG_ RADC_a032_block_SPMBlockageState m32 : 24|3@1+ (1,0) [0|0] "" Vector__XXX
 SG_ RADC_a047_chassisTypeRx m47 : 24|8@1+ (1,0) [0|0] "" Vector__XXX
 SG_ RADC_a048_airSuspensionRx m48 : 24|8@1+ (1,0) [0|0] "" Vector__XXX
 SG_ RADC_a049_fourWheelDriveRx m49 : 24|8@1+ (1,0) [0|0] "" Vector__XXX
 SG_ RADC_a051_epasTypeRx m51 : 24|8@1+ (1,0) [0|0] "" Vector__XXX
 SG_ RADC_a052_radarPositionRx m52 : 24|8@1+ (1,0) [0|0] "" Vector__XXX
 SG_ RADC_a053_emError_LongPosToCoG m53 : 24|1@1+ (1,0) [0|0] "" Vector__XXX
 SG_ RADC_a054_block_ucObjLossConf m54 : 24|8@1+ (1,0) [0|0] "" Vector__XXX
 SG_ RADC_a053_emError_WheelbaseStat m53 : 25|1@1+ (1,0) [0|0] "" Vector__XXX
 SG_ RADC_a053_emError_TrackWidthFr m53 : 26|1@1+ (1,0) [0|0] "" Vector__XXX
 SG_ RADC_a032_block_dummy m32 : 27|3@1+ (1,0) [0|0] "" Vector__XXX
 SG_ RADC_a053_emError_TrackWidthRe m53 : 27|1@1+ (1,0) [0|0] "" Vector__XXX
 SG_ RADC_a053_emError_VehicleWeight m53 : 28|1@1+ (1,0) [0|0] "" Vector__XXX
 SG_ RADC_a053_emError_CentGravHeight m53 : 29|1@1+ (1,0) [0|0] "" Vector__XXX
 SG_ RADC_a032_block_SPMSelfTestState m32 : 30|2@1+ (1,0) [0|0] "" Vector__XXX
 SG_ RADC_a053_emError_AxisLoadDistr m53 : 30|1@1+ (1,0) [0|0] "" Vector__XXX
 SG_ RADC_a053_emError_PreClusterList m53 : 31|1@1+ (1,0) [0|0] "" Vector__XXX
 SG_ RADC_a029_rhcRxErrType m29 : 32|8@1+ (1,0) [0|0] "" Vector__XXX
 SG_ RADC_a032_block_ucEstiRange m32 : 32|8@1+ (1,0) [0|0] "" Vector__XXX
 SG_ RADC_a050_countryRx m50 : 32|16@1+ (1,0) [0|0] "" Vector__XXX
 SG_ RADC_a053_emError_RSPClusterList m53 : 32|1@1+ (1,0) [0|0] "" Vector__XXX
 SG_ RADC_a054_block_ucOverallProb m54 : 32|8@1+ (1,0) [0|0] "" Vector__XXX
 SG_ RADC_a055_block_ucTimeoutTimeCnt m55 : 32|8@1+ (1,0) [0|0] "" Vector__XXX
 SG_ RADC_a041_vinErrRx m41 : 36|16@1+ (1,0) [0|0] "" Vector__XXX
 SG_ RADC_a042_carConfigErrRx m42 : 36|16@1+ (1,0) [0|0] "" Vector__XXX
 SG_ RADC_a043_inertialSignalsErrRx m43 : 36|16@1+ (1,0) [0|0] "" Vector__XXX
 SG_ RADC_a044_stwAngleErrRx m44 : 36|16@1+ (1,0) [0|0] "" Vector__XXX
 SG_ RADC_a045_vehicleStateErrRx m45 : 36|16@1+ (1,0) [0|0] "" Vector__XXX
 SG_ RADC_a046_wheelSpeedsErrRx m46 : 36|16@1+ (1,0) [0|0] "" Vector__XXX
 SG_ RADC_a029_rhcVcoPowerErrType m29 : 40|8@1+ (1,0) [0|0] "" Vector__XXX
 SG_ RADC_a032_block_ucEstiRangeConf m32 : 40|8@1+ (1,0) [0|0] "" Vector__XXX
 SG_ RADC_a054_block_ucOverallConf m54 : 40|8@1+ (1,0) [0|0] "" Vector__XXX
 SG_ RADC_a055_bblock_ucTimeoutBlkProb m55 : 40|8@1+ (1,0) [0|0] "" Vector__XXX
 SG_ RADC_a029_rhcSp1ErrType m29 : 48|8@1+ (1,0) [0|0] "" Vector__XXX
 SG_ RADC_a032_block_ucEstiRangeProb m32 : 48|8@1+ (1,0) [0|0] "" Vector__XXX
 SG_ RADC_a054_block_RoadbeamTimeCnt m54 : 48|16@1+ (1,0) [0|0] "" Vector__XXX
 SG_ RADC_a055_block_usFullBlkTimer m55 : 48|16@1+ (1,0) [0|0] "" Vector__XXX
 SG_ RADC_a041_msgId m41 : 52|12@1+ (1,0) [0|0] "" Vector__XXX
 SG_ RADC_a042_msgId m42 : 52|12@1+ (1,0) [0|0] "" Vector__XXX
 SG_ RADC_a043_msgId m43 : 52|12@1+ (1,0) [0|0] "" Vector__XXX
 SG_ RADC_a044_msgId m44 : 52|12@1+ (1,0) [0|0] "" Vector__XXX
 SG_ RADC_a045_msgId m45 : 52|12@1+ (1,0) [0|0] "" Vector__XXX
 SG_ RADC_a046_msgId m46 : 52|12@1+ (1,0) [0|0] "" Vector__XXX
 SG_ RADC_a029_rhcFdcErrType m29 : 56|8@1+ (1,0) [0|0] "" Vector__XXX
 SG_ RADC_a032_block_ucTimeoutBlkConf m32 : 56|8@1+ (1,0) [0|0] "" Vector__XXX

BO_ 1368 GTW_gitHash: 12 Vector__XXX
 SG_ GTW_appGitHash : 7|64@0+ (1,0) [0|0] "" Vector__XXX

BO_ 1383 ADSP_state: 8 Vector__XXX
 SG_ ADSP_a2baState : 0|5@1+ (1,0) [0|0] "" Vector__XXX
 SG_ ADSP_a2bbState : 8|5@1+ (1,0) [0|0] "" Vector__XXX
 SG_ ADSP_baseamp0State : 13|3@1+ (1,0) [0|0] "" Vector__XXX
 SG_ ADSP_baseamp1State : 16|3@1+ (1,0) [0|0] "" Vector__XXX
 SG_ ADSP_baseamp2State : 19|3@1+ (1,0) [0|0] "" Vector__XXX
 SG_ ADSP_baseamp3State : 24|3@1+ (1,0) [0|0] "" Vector__XXX
 SG_ ADSP_audioReady : 27|1@1+ (1,0) [0|0] "" Vector__XXX
 SG_ ADSP_tcuI2SEnabled : 28|1@1+ (1,0) [0|0] "" Vector__XXX
 SG_ ADSP_telephonyRxMute : 31|1@1+ (1,0) [0|0] "" Vector__XXX
 SG_ ADSP_ancState : 32|3@1+ (1,0) [0|0] "" Vector__XXX
 SG_ ADSP_sourceSelect : 35|2@1+ (1,0) [0|0] "" Vector__XXX
 SG_ ADSP_tunerSelect : 37|1@1+ (1,0) [0|0] "" Vector__XXX
 SG_ ADSP_ancMode : 38|5@1+ (1,0) [0|0] "" Vector__XXX
 SG_ ADSP_spkMuteAll : 43|1@1+ (1,0) [0|0] "" Vector__XXX
 SG_ ADSP_eCall_ENS_state : 44|3@1+ (1,0) [0|0] "" Vector__XXX
 SG_ ADSP_eCallSelfTest : 47|2@1+ (1,0) [0|0] "" Vector__XXX
 SG_ ADSP_eCallState : 49|1@1+ (1,0) [0|0] "" Vector__XXX
 SG_ ADSP_allAudioReady : 50|1@1+ (1,0) [0|0] "" Vector__XXX
 SG_ ADSP_callState : 51|1@1+ (1,0) [0|0] "" Vector__XXX
 SG_ ADSP_telephonyTxMute : 52|1@1+ (1,0) [0|0] "" Vector__XXX
 SG_ ADSP_eCallMicrophoneStatus : 53|2@1+ (1,0) [0|0] "" Vector__XXX
 SG_ ADSP_eCallSpeakerStatus : 56|2@1+ (1,0) [0|0] "" Vector__XXX
 SG_ ADSP_a2baLoadShedded : 58|1@1+ (1,0) [0|0] "" Vector__XXX
 SG_ ADSP_requestFailoverSpeaker : 59|1@1+ (1,0) [0|0] "" Vector__XXX
 SG_ ADSP_microphoneDataState : 60|1@1+ (1,0) [0|0] "" Vector__XXX

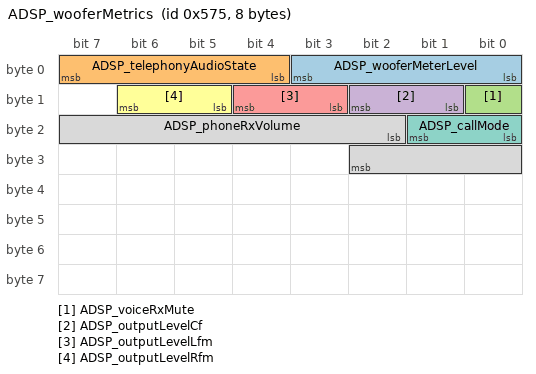
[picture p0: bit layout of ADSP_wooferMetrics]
BO_ 1397 ADSP_wooferMetrics: 8 Vector__XXX
 SG_ ADSP_wooferMeterLevel : 0|4@1+ (10,-100) [0|0] "" Vector__XXX
 SG_ ADSP_telephonyAudioState : 4|4@1+ (1,0) [0|0] "" Vector__XXX
 SG_ ADSP_voiceRxMute : 8|1@1+ (1,0) [0|0] "" Vector__XXX
 SG_ ADSP_outputLevelCf : 9|2@1+ (1,0) [0|0] "" Vector__XXX
 SG_ ADSP_outputLevelLfm : 11|2@1+ (1,0) [0|0] "" Vector__XXX
 SG_ ADSP_outputLevelRfm : 13|2@1+ (1,0) [0|0] "" Vector__XXX
 SG_ ADSP_callMode : 16|2@1+ (1,0) [0|0] "" Vector__XXX
 SG_ ADSP_phoneRxVolume : 18|9@1- (1,0) [0|0] "" Vector__XXX

BO_ 1425 EPAS3S_alertLog: 8 Vector__XXX
 SG_ EPAS3S_alertID M : 0|8@1+ (1,0) [0|0] "" Vector__XXX
 SG_ EPAS3S_alertState : 15|1@1+ (1,0) [0|0] "" Vector__XXX
 SG_ EPAS3S_a084_eacCancelMtrq m84 : 16|10@1+ (0.01,0) [0|0] "" Vector__XXX
 SG_ EPAS3S_a132_motorTorqueCommand m132 : 16|8@1- (0.0787,0) [0|0] "" Vector__XXX
 SG_ EPAS3S_a133_motorTorqueCommand m133 : 16|8@1- (0.0787,0) [0|0] "" Vector__XXX
 SG_ EPAS3S_a134_motorTorqueCommand m134 : 16|8@1- (0.0787,0) [0|0] "" Vector__XXX
 SG_ EPAS3S_a135_motorTorqueCommand m135 : 16|8@1- (0.0787,0) [0|0] "" Vector__XXX
 SG_ EPAS3S_a136_motorTorqueCommand m136 : 16|8@1- (0.0787,0) [0|0] "" Vector__XXX
 SG_ EPAS3S_a137_motorTorqueCommand m137 : 16|8@1- (0.0787,0) [0|0] "" Vector__XXX
 SG_ EPAS3S_a147_transitionReason m147 : 16|2@1+ (1,0) [0|0] "" Vector__XXX
 SG_ EPAS3S_a148_vehicleSpeed m148 : 16|10@1+ (0.5,0) [0|0] "" Vector__XXX
 SG_ EPAS3S_a149_pcbTemp m149 : 16|8@1- (1,60) [0|0] "" Vector__XXX
 SG_ EPAS3S_a150_pcbTemp m150 : 16|8@1- (1,60) [0|0] "" Vector__XXX
 SG_ EPAS3S_a151_dcsVBridge m151 : 16|6@1+ (0.328,0) [0|0] "" Vector__XXX
 SG_ EPAS3S_a152_dcsVBridge m152 : 16|6@1+ (0.328,0) [0|0] "" Vector__XXX
 SG_ EPAS3S_a153_dcsOffsetA m153 : 16|10@1- (1,0) [0|0] "" Vector__XXX
 SG_ EPAS3S_a154_vehicleSpeed m154 : 16|10@1+ (0.5,0) [0|0] "" Vector__XXX
 SG_ EPAS3S_a155_vehicleSpeed m155 : 16|10@1+ (0.5,0) [0|0] "" Vector__XXX
 SG_ EPAS3S_a156_vehicleSpeed m156 : 16|10@1+ (0.5,0) [0|0] "" Vector__XXX
 SG_ EPAS3S_a160_currentSensorStatus m160 : 16|2@1+ (1,0) [0|0] "" Vector__XXX
 SG_ EPAS3S_a161_pcoMinPhaseBCurrent m161 : 16|12@1- (0.1025,0) [0|0] "" Vector__XXX
 SG_ EPAS3S_a162_vBridgeClosed m162 : 16|16@1+ (0.00537,0) [0|0] "" Vector__XXX
 SG_ EPAS3S_a163_gateDrvrStatusReg m163 : 16|11@1+ (1,0) [0|0] "" Vector__XXX
 SG_ EPAS3S_a164_dcsRegister0x19 m164 : 16|16@1+ (1,0) [0|0] "" Vector__XXX
 SG_ EPAS3S_a160_gateDriverStatus m160 : 18|2@1+ (1,0) [0|0] "" Vector__XXX
 SG_ EPAS3S_a160_highSideDisconnectFetStatus m160 : 20|2@1+ (1,0) [0|0] "" Vector__XXX
 SG_ EPAS3S_a151_dcsMainChannelA m151 : 22|10@1- (0.41,0) [0|0] "" Vector__XXX
 SG_ EPAS3S_a160_phaseDisconnectFetStatus m160 : 22|2@1+ (1,0) [0|0] "" Vector__XXX
 SG_ EPAS3S_a152_dcsModIndex m152 : 23|7@1+ (1,0) [0|0] "" Vector__XXX
 SG_ EPAS3S_a132_motorTorqueInverse m132 : 24|8@1- (0.0787,0) [0|0] "" Vector__XXX
 SG_ EPAS3S_a133_motorTorqueInverse m133 : 24|8@1- (0.0787,0) [0|0] "" Vector__XXX
 SG_ EPAS3S_a134_motorTorqueInverse m134 : 24|8@1- (0.0787,0) [0|0] "" Vector__XXX
 SG_ EPAS3S_a135_iqReference m135 : 24|9@1- (0.78125,0) [0|0] "" Vector__XXX
 SG_ EPAS3S_a136_iqReference m136 : 24|9@1- (0.78125,0) [0|0] "" Vector__XXX
 SG_ EPAS3S_a137_iqReference m137 : 24|9@1- (0.78125,0) [0|0] "" Vector__XXX
 SG_ EPAS3S_a150_phaUMainPathCalcDiff m150 : 24|15@1+ (1,0) [0|0] "" Vector__XXX
 SG_ EPAS3S_a160_inverterFetStatus m160 : 24|2@1+ (1,0) [0|0] "" Vector__XXX
 SG_ EPAS3S_a084_eacCancelTtrq m84 : 26|10@1+ (0.05,-25) [0|0] "" Vector__XXX
 SG_ EPAS3S_a153_dcsOffsetB m153 : 26|10@1- (1,0) [0|0] "" Vector__XXX
 SG_ EPAS3S_a160_hsdFetFailShortTest m160 : 26|2@1+ (1,0) [0|0] "" Vector__XXX
 SG_ EPAS3S_a163_gateDrvrDiag2Reg m163 : 27|9@1+ (1,0) [0|0] "" Vector__XXX
 SG_ EPAS3S_a160_phaDisconnFailOpenTest m160 : 28|2@1+ (1,0) [0|0] "" Vector__XXX
 SG_ EPAS3S_a161_pcoMaxPhaseBCurrent m161 : 28|12@1- (0.1025,0) [0|0] "" Vector__XXX
 SG_ EPAS3S_a152_dcsMainPathErrReg m152 : 30|11@1+ (1,0) [0|0] "" Vector__XXX
 SG_ EPAS3S_a160_phaDisconnFailShortTest m160 : 30|2@1+ (1,0) [0|0] "" Vector__XXX
 SG_ EPAS3S_a132_idMeasured m132 : 32|8@1+ (0.787,0) [0|0] "" Vector__XXX
 SG_ EPAS3S_a133_idMeasured m133 : 32|8@1+ (0.787,0) [0|0] "" Vector__XXX
 SG_ EPAS3S_a134_idMeasured m134 : 32|8@1+ (0.787,0) [0|0] "" Vector__XXX
 SG_ EPAS3S_a151_dcsMainChannelB m151 : 32|10@1- (0.41,0) [0|0] "" Vector__XXX
 SG_ EPAS3S_a160_invFetInitTest m160 : 32|2@1+ (1,0) [0|0] "" Vector__XXX
 SG_ EPAS3S_a162_vBridgeOpen m162 : 32|16@1+ (0.00537,0) [0|0] "" Vector__XXX
 SG_ EPAS3S_a164_currentSensorRailed m164 : 32|1@1+ (1,0) [0|0] "" Vector__XXX
 SG_ EPAS3S_a135_idMeasured m135 : 33|8@1+ (0.787,0) [0|0] "" Vector__XXX
 SG_ EPAS3S_a136_idMeasured m136 : 33|8@1+ (0.787,0) [0|0] "" Vector__XXX
 SG_ EPAS3S_a137_idMeasured m137 : 33|8@1+ (0.787,0) [0|0] "" Vector__XXX
 SG_ EPAS3S_a160_gateDrvrInitTest m160 : 34|2@1+ (1,0) [0|0] "" Vector__XXX
 SG_ EPAS3S_a084_eacCancelAngleGrad m84 : 36|12@1+ (1,-2048) [0|0] "" Vector__XXX
 SG_ EPAS3S_a163_gateDrvrDiag1Reg m163 : 36|9@1+ (1,0) [0|0] "" Vector__XXX
 SG_ EPAS3S_a150_phaVMainPathCalcDiff m150 : 39|15@1+ (1,0) [0|0] "" Vector__XXX
 SG_ EPAS3S_a132_iqMeasured m132 : 40|9@1- (0.78125,0) [0|0] "" Vector__XXX
 SG_ EPAS3S_a133_iqMeasured m133 : 40|9@1- (0.78125,0) [0|0] "" Vector__XXX
 SG_ EPAS3S_a134_iqMeasured m134 : 40|9@1- (0.78125,0) [0|0] "" Vector__XXX
 SG_ EPAS3S_a161_pcoMinPhaseACurrent m161 : 40|12@1- (0.1025,0) [0|0] "" Vector__XXX
 SG_ EPAS3S_a135_iqMeasured m135 : 41|9@1- (0.78125,0) [0|0] "" Vector__XXX
 SG_ EPAS3S_a136_iqMeasured m136 : 41|9@1- (0.78125,0) [0|0] "" Vector__XXX
 SG_ EPAS3S_a137_iqMeasured m137 : 41|9@1- (0.78125,0) [0|0] "" Vector__XXX
 SG_ EPAS3S_a152_dcsTubErrReg m152 : 41|6@1+ (1,0) [0|0] "" Vector__XXX
 SG_ EPAS3S_a151_dcsOffsetA m151 : 42|10@1- (1,0) [0|0] "" Vector__XXX
 SG_ EPAS3S_a163_gateDrvrDiag0Reg m163 : 45|9@1+ (1,0) [0|0] "" Vector__XXX
 SG_ EPAS3S_a152_dcsErrSumReg m152 : 47|10@1+ (1,0) [0|0] "" Vector__XXX
 SG_ EPAS3S_a084_eacCancelAngle m84 : 48|12@1+ (1,-2048) [0|0] "" Vector__XXX
 SG_ EPAS3S_a132_motorVelocity m132 : 49|10@1- (0.9765625,0) [0|0] "" Vector__XXX
 SG_ EPAS3S_a133_motorVelocity m133 : 49|10@1- (0.9765625,0) [0|0] "" Vector__XXX
 SG_ EPAS3S_a134_motorVelocity m134 : 49|10@1- (0.9765625,0) [0|0] "" Vector__XXX
 SG_ EPAS3S_a135_motorVelocity m135 : 50|10@1- (0.9765625,0) [0|0] "" Vector__XXX
 SG_ EPAS3S_a136_motorVelocity m136 : 50|10@1- (0.9765625,0) [0|0] "" Vector__XXX
 SG_ EPAS3S_a137_motorVelocity m137 : 50|10@1- (0.9765625,0) [0|0] "" Vector__XXX
 SG_ EPAS3S_a151_dcsOffsetB m151 : 52|10@1- (1,0) [0|0] "" Vector__XXX
 SG_ EPAS3S_a161_pcoMaxPhaseACurrent m161 : 52|12@1- (0.1025,0) [0|0] "" Vector__XXX
 SG_ EPAS3S_a150_otherECUAssistStatusFlag m150 : 54|1@1+ (1,0) [0|0] "" Vector__XXX
 SG_ EPAS3S_a163_diagStatus m163 : 54|1@1+ (1,0) [0|0] "" Vector__XXX
 SG_ EPAS3S_a163_powerStatus m163 : 55|1@1+ (1,0) [0|0] "" Vector__XXX
 SG_ EPAS3S_a152_dcsVbusDiagPathErrReg m152 : 57|7@1+ (1,0) [0|0] "" Vector__XXX
 SG_ EPAS3S_a084_eacCancelCode m84 : 60|4@1+ (1,0) [0|0] "" Vector__XXX
 SG_ EPAS3S_a151_dcsCBootA m151 : 62|1@1+ (1,0) [0|0] "" Vector__XXX
 SG_ EPAS3S_a151_dcsCBootB m151 : 63|1@1+ (1,0) [0|0] "" Vector__XXX

BO_ 1429 OCS1P_alertLog: 8 Vector__XXX
 SG_ OCS1P_alertID M : 0|8@1+ (1,0) [0|0] "" Vector__XXX
 SG_ OCS1P_alertState : 15|1@1+ (1,0) [0|0] "" Vector__XXX
 SG_ OCS1P_a000_alertDataW0 m0 : 16|16@1+ (1,0) [0|0] "" Vector__XXX
 SG_ OCS1P_a015_NVMMRecordNotFound m15 : 16|1@1+ (1,0) [0|0] "" Vector__XXX
 SG_ OCS1P_a121_sandwichFreq m121 : 16|32@1+ (1,0) [0|0] "" Vector__XXX
 SG_ OCS1P_a122_sandwichFreq m122 : 16|32@1+ (1,0) [0|0] "" Vector__XXX
 SG_ OCS1P_a123_sandwichFreq m123 : 16|32@1+ (1,0) [0|0] "" Vector__XXX
 SG_ OCS1P_a124_cushionSelfFreq m124 : 16|32@1+ (1,0) [0|0] "" Vector__XXX
 SG_ OCS1P_a125_cushionSelfFreq m125 : 16|32@1+ (1,0) [0|0] "" Vector__XXX
 SG_ OCS1P_a126_cushionSelfFreq m126 : 16|32@1+ (1,0) [0|0] "" Vector__XXX
 SG_ OCS1P_a127_seatbackSelfFreq m127 : 16|32@1+ (1,0) [0|0] "" Vector__XXX
 SG_ OCS1P_a128_seatbackSelfFreq m128 : 16|32@1+ (1,0) [0|0] "" Vector__XXX
 SG_ OCS1P_a129_seatbackSelfFreq m129 : 16|32@1+ (1,0) [0|0] "" Vector__XXX
 SG_ OCS1P_a130_sandwichNoCalib m130 : 16|1@1+ (1,0) [0|0] "" Vector__XXX
 SG_ OCS1P_a131_cushionSelfNoCalib m131 : 16|1@1+ (1,0) [0|0] "" Vector__XXX
 SG_ OCS1P_a132_seatbackSelfNoCalib m132 : 16|1@1+ (1,0) [0|0] "" Vector__XXX
 SG_ OCS1P_a133_sandwichBadCalib m133 : 16|1@1+ (1,0) [0|0] "" Vector__XXX
 SG_ OCS1P_a134_uninitializedCalib m134 : 16|1@1+ (1,0) [0|0] "" Vector__XXX
 SG_ OCS1P_a135_tempNoCalib m135 : 16|1@1+ (1,0) [0|0] "" Vector__XXX
 SG_ OCS1P_a136_cushionSelfDuty m136 : 16|32@1+ (1,0) [0|0] "" Vector__XXX
 SG_ OCS1P_a137_cushionSelfDuty m137 : 16|32@1+ (1,0) [0|0] "" Vector__XXX
 SG_ OCS1P_a138_seatbackSelfDuty m138 : 16|32@1+ (1,0) [0|0] "" Vector__XXX
 SG_ OCS1P_a139_seatbackSelfDuty m139 : 16|32@1+ (1,0) [0|0] "" Vector__XXX
 SG_ OCS1P_a140_tempInvalidCalib m140 : 16|1@1+ (1,0) [0|0] "" Vector__XXX
 SG_ OCS1P_a141_humidityInvalidCalib m141 : 16|1@1+ (1,0) [0|0] "" Vector__XXX
 SG_ OCS1P_a142_tempHumidityInvalid m142 : 16|1@1+ (1,0) [0|0] "" Vector__XXX
 SG_ OCS1P_a143_mismatchPassAirbag m143 : 16|1@1+ (1,0) [0|0] "" Vector__XXX
 SG_ OCS1P_a144_mismatchCarRegion m144 : 16|1@1+ (1,0) [0|0] "" Vector__XXX
 SG_ OCS1P_a145_cushionSelfOffset m145 : 16|16@1- (0.005,0) [0|0] "" Vector__XXX
 SG_ OCS1P_a148_rawCapVsFreq m148 : 16|1@1+ (1,0) [0|0] "" Vector__XXX
 SG_ OCS1P_a150_cushionSelfBaseline m150 : 16|16@1+ (0.005,0) [0|0] "" Vector__XXX
 SG_ OCS1P_a151_reason m151 : 16|3@1+ (1,0) [0|0] "" Vector__XXX
 SG_ OCS1P_a152_cushionSelfPreExit m152 : 16|16@1+ (0.005,0) [0|0] "" Vector__XXX
 SG_ OCS1P_a153_reason m153 : 16|3@1+ (1,0) [0|0] "" Vector__XXX
 SG_ OCS1P_a154_reason m154 : 16|3@1+ (1,0) [0|0] "" Vector__XXX
 SG_ OCS1P_a155_cushionSelfBaseline m155 : 16|16@1+ (0.005,0) [0|0] "" Vector__XXX
 SG_ OCS1P_a015_NVMMCRCMismatch m15 : 17|1@1+ (1,0) [0|0] "" Vector__XXX
 SG_ OCS1P_a148_rawRBVsFreq m148 : 17|1@1+ (1,0) [0|0] "" Vector__XXX
 SG_ OCS1P_a015_NVMMVersionMismatch m15 : 18|1@1+ (1,0) [0|0] "" Vector__XXX
 SG_ OCS1P_a148_rawRBVsCap m148 : 18|1@1+ (1,0) [0|0] "" Vector__XXX
 SG_ OCS1P_a015_NVMMRecordUpgraded m15 : 19|1@1+ (1,0) [0|0] "" Vector__XXX
 SG_ OCS1P_a148_filtCapVsFreq m148 : 19|1@1+ (1,0) [0|0] "" Vector__XXX
 SG_ OCS1P_a015_NVMMMemOverflow m15 : 20|1@1+ (1,0) [0|0] "" Vector__XXX
 SG_ OCS1P_a148_filtRBVsFreq m148 : 20|1@1+ (1,0) [0|0] "" Vector__XXX
 SG_ OCS1P_a015_NVMMWriteFailed m15 : 21|1@1+ (1,0) [0|0] "" Vector__XXX
 SG_ OCS1P_a148_filtRBVsCap m148 : 21|1@1+ (1,0) [0|0] "" Vector__XXX
 SG_ OCS1P_a148_rawFreqClass m148 : 24|3@1+ (1,0) [0|0] "" Vector__XXX
 SG_ OCS1P_a151_cushionSelfMin m151 : 24|16@1+ (0.005,0) [0|0] "" Vector__XXX
 SG_ OCS1P_a154_cushionSelfMin m154 : 24|16@1+ (0.005,0) [0|0] "" Vector__XXX
 SG_ OCS1P_a148_rawCapClass m148 : 27|3@1+ (1,0) [0|0] "" Vector__XXX
 SG_ OCS1P_a000_alertDataW1 m0 : 32|16@1+ (1,0) [0|0] "" Vector__XXX
 SG_ OCS1P_a145_seatbackSelfOffset m145 : 32|16@1- (0.0025,0) [0|0] "" Vector__XXX
 SG_ OCS1P_a148_rawRBClass m148 : 32|3@1+ (1,0) [0|0] "" Vector__XXX
 SG_ OCS1P_a150_seatbackSelfBaseline m150 : 32|16@1+ (0.005,0) [0|0] "" Vector__XXX
 SG_ OCS1P_a152_seatbackSelfPreExit m152 : 32|16@1+ (0.005,0) [0|0] "" Vector__XXX
 SG_ OCS1P_a155_seatbackSelfBaseline m155 : 32|16@1+ (0.005,0) [0|0] "" Vector__XXX
 SG_ OCS1P_a148_filtFreqClass m148 : 35|3@1+ (1,0) [0|0] "" Vector__XXX
 SG_ OCS1P_a148_filtCapClass m148 : 40|3@1+ (1,0) [0|0] "" Vector__XXX
 SG_ OCS1P_a151_seatbackSelfMin m151 : 40|16@1+ (0.005,0) [0|0] "" Vector__XXX
 SG_ OCS1P_a154_seatbackSelfMin m154 : 40|16@1+ (0.005,0) [0|0] "" Vector__XXX
 SG_ OCS1P_a148_filtRBClass m148 : 43|3@1+ (1,0) [0|0] "" Vector__XXX
 SG_ OCS1P_a000_alertDataW2 m0 : 48|16@1+ (1,0) [0|0] "" Vector__XXX
 SG_ OCS1P_a145_temperature m145 : 48|8@1+ (1,-40) [0|0] "" Vector__XXX
 SG_ OCS1P_a145_humidity m145 : 56|8@1+ (1,0) [0|0] "" Vector__XXX

BO_ 1451 OCS1P_alertCleared: 8 Vector__XXX
 SG_ OCS1P_alertClearedID : 0|8@1+ (1,0) [0|0] "" Vector__XXX

BO_ 1465 DAS_alertLog: 8 Vector__XXX
 SG_ DAS_alertID M : 0|15@1+ (1,0) [0|0] "" Vector__XXX
 SG_ DAS_alertState : 15|1@1+ (1,0) [0|0] "" Vector__XXX
 SG_ DAS_sw004_radIssue m4 : 16|1@1+ (1,0) [0|0] "" Vector__XXX
 SG_ DAS_sw005_AutofixOutOfCalib m5 : 16|1@1+ (1,0) [0|0] "" Vector__XXX
 SG_ DAS_sw006_RadarLowVisibility m6 : 16|1@1+ (1,0) [0|0] "" Vector__XXX
 SG_ DAS_sw009_DIaebState_fault m9 : 16|1@1+ (1,0) [0|0] "" Vector__XXX
 SG_ DAS_sw010_a04calibNotDone m10 : 16|1@1+ (1,0) [0|0] "" Vector__XXX
 SG_ DAS_sw011_scaState m11 : 16|3@1+ (1,0) [0|0] "" Vector__XXX
 SG_ DAS_sw012_bootTestResults m12 : 16|16@1+ (1,0) [0|0] "" Vector__XXX
 SG_ DAS_sw013_stateBeforeWatchdog m13 : 16|5@1+ (1,0) [0|0] "" Vector__XXX
 SG_ DAS_sw014_fileNameHash m14 : 16|16@1+ (1,0) [0|0] "" Vector__XXX
 SG_ DAS_sw015_RadarLowVisibility m15 : 16|2@1+ (1,0) [0|0] "" Vector__XXX
 SG_ DAS_sw016_targetDist m16 : 16|9@1+ (0.2,0) [0|0] "" Vector__XXX
 SG_ DAS_sw017_Camera_Msg_Lanes_MIA m17 : 16|1@1+ (1,0) [0|0] "" Vector__XXX
 SG_ DAS_sw018_minThreshold m18 : 16|13@1+ (1,0) [0|0] "" Vector__XXX
 SG_ DAS_sw019_taskId m19 : 16|8@1+ (1,0) [0|0] "" Vector__XXX
 SG_ DAS_sw020_unusedW0 m20 : 16|16@1+ (1,0) [0|0] "" Vector__XXX
 SG_ DAS_sw021_tempSensorId m21 : 16|8@1+ (1,0) [0|0] "" Vector__XXX
 SG_ DAS_sw022_operation m22 : 16|4@1+ (1,0) [0|0] "" Vector__XXX
 SG_ DAS_sw024_Task_ID m24 : 16|4@1+ (1,0) [0|0] "" Vector__XXX
 SG_ DAS_sw025_state_before_override m25 : 16|4@1+ (1,0) [0|0] "" Vector__XXX
 SG_ DAS_sw026_task_id m26 : 16|2@1+ (1,0) [0|0] "" Vector__XXX
 SG_ DAS_sw027_JTAG_Reset m27 : 16|1@1+ (1,0) [0|0] "" Vector__XXX
 SG_ DAS_sw028_rx_buffer_full m28 : 16|1@1+ (1,0) [0|0] "" Vector__XXX
 SG_ DAS_sw029_tx_buffer_full m29 : 16|1@1+ (1,0) [0|0] "" Vector__XXX
 SG_ DAS_sw030_heaterState m30 : 16|8@1+ (1,0) [0|0] "" Vector__XXX
 SG_ DAS_sw031_canBus m31 : 16|4@1+ (1,0) [0|0] "" Vector__XXX
 SG_ DAS_sw032_canBus m32 : 16|4@1+ (1,0) [0|0] "" Vector__XXX
 SG_ DAS_sw033_gtwMia m33 : 16|8@1+ (1,0) [0|0] "" Vector__XXX
 SG_ DAS_sw034_sccmMia m34 : 16|8@1+ (1,0) [0|0] "" Vector__XXX
 SG_ DAS_sw035_espMia m35 : 16|8@1+ (1,0) [0|0] "" Vector__XXX
 SG_ DAS_sw036_bdyMia m36 : 16|8@1+ (1,0) [0|0] "" Vector__XXX
 SG_ DAS_sw037_camera m37 : 16|8@1+ (1,0) [0|0] "" Vector__XXX
 SG_ DAS_sw038_RadarMisalignment m38 : 16|1@1+ (1,0) [0|0] "" Vector__XXX
 SG_ DAS_sw039_sdm_rcm_Mia m39 : 16|8@1+ (1,0) [0|0] "" Vector__XXX
 SG_ DAS_sw040_accel_pedal_pos m40 : 16|8@1+ (0.5,0) [0|0] "" Vector__XXX
 SG_ DAS_sw041_rate m41 : 16|10@1- (1,0) [0|0] "" Vector__XXX
 SG_ DAS_sw042_health_state m42 : 16|3@1+ (1,0) [0|0] "" Vector__XXX
 SG_ DAS_sw043_mobileye_status m43 : 16|16@1+ (1,0) [0|0] "" Vector__XXX
 SG_ DAS_sw044_countLSB m44 : 16|8@1+ (1,0) [0|0] "" Vector__XXX
 SG_ DAS_sw045_radMia m45 : 16|5@1+ (1,0) [0|0] "" Vector__XXX
 SG_ DAS_sw046_recordId m46 : 16|16@1+ (1,0) [0|0] "" Vector__XXX
 SG_ DAS_sw047_edrStatus m47 : 16|4@1+ (1,0) [0|0] "" Vector__XXX
 SG_ DAS_sw048_swAssert m48 : 16|1@1+ (1,0) [0|0] "" Vector__XXX
 SG_ DAS_sw049_boot_version_msw m49 : 16|16@1+ (1,0) [0|0] "" Vector__XXX
 SG_ DAS_sw050_targetDist m50 : 16|9@1+ (0.2,0) [0|0] "" Vector__XXX
 SG_ DAS_sw051_a01ecuInternalPerf m51 : 16|1@1+ (1,0) [0|0] "" Vector__XXX
 SG_ DAS_sw052_a07sensorBlinded m52 : 16|1@1+ (1,0) [0|0] "" Vector__XXX
 SG_ DAS_sw053_a10canBusOff m53 : 16|1@1+ (1,0) [0|0] "" Vector__XXX
 SG_ DAS_sw054_Autofix_cnvrgnceStatus m54 : 16|8@1+ (1,0) [0|0] "" Vector__XXX
 SG_ DAS_sw055_detectedRadcVersion m55 : 16|32@1+ (1,0) [0|0] "" Vector__XXX
 SG_ DAS_sw056_diMia m56 : 16|8@1+ (1,0) [0|0] "" Vector__XXX
 SG_ DAS_sw057_chCtrlMia m57 : 16|1@1+ (1,0) [0|0] "" Vector__XXX
 SG_ DAS_sw058_epbMia m58 : 16|8@1+ (1,0) [0|0] "" Vector__XXX
 SG_ DAS_sw059_parkMia m59 : 16|8@1+ (1,0) [0|0] "" Vector__XXX
 SG_ DAS_sw060_targetDist m60 : 16|9@1+ (0.2,0) [0|0] "" Vector__XXX
 SG_ DAS_sw061_airSuspensionMia m61 : 16|8@1+ (1,0) [0|0] "" Vector__XXX
 SG_ DAS_sw062_HorizontalMisalignment m62 : 16|16@1+ (0.00137332,-45) [0|0] "" Vector__XXX
 SG_ DAS_sw063_expectedMajorVer m63 : 16|8@1+ (1,0) [0|0] "" Vector__XXX
 SG_ DAS_sw064_sysStatus m64 : 16|1@1+ (1,0) [0|0] "" Vector__XXX
 SG_ DAS_sw065_app_mobileye_status m65 : 16|8@1+ (1,0) [0|0] "" Vector__XXX
 SG_ DAS_sw066_app_mobileye_status m66 : 16|8@1+ (1,0) [0|0] "" Vector__XXX
 SG_ DAS_sw067_sccmSTW m67 : 16|14@1+ (0.1,-819.2) [0|0] "" Vector__XXX
 SG_ DAS_sw068_percentConsistency m68 : 16|10@1+ (0.1,0) [0|0] "" Vector__XXX
 SG_ DAS_sw069_epasMia m69 : 16|1@1+ (1,0) [0|0] "" Vector__XXX
 SG_ DAS_sw070_currTireFitment m70 : 16|3@1+ (1,0) [0|0] "" Vector__XXX
 SG_ DAS_sw071_selfParkType m71 : 16|4@1+ (1,0) [0|0] "" Vector__XXX
 SG_ DAS_sw072_vehicleX m72 : 16|10@1+ (0.05,-25.6) [0|0] "" Vector__XXX
 SG_ DAS_sw073_escalateLDWs m73 : 16|1@1+ (1,0) [0|0] "" Vector__XXX
 SG_ DAS_sw074_ipsoDx m74 : 16|6@1+ (2,0) [0|0] "" Vector__XXX
 SG_ DAS_sw075_scMia m75 : 16|8@1+ (1,0) [0|0] "" Vector__XXX
 SG_ DAS_sw076_targetDist m76 : 16|9@1+ (0.2,0) [0|0] "" Vector__XXX
 SG_ DAS_sw077_oocDistance m77 : 16|9@1+ (1,0) [0|0] "" Vector__XXX
 SG_ DAS_sw078_camCipv_dx m78 : 16|8@1+ (0.2,0) [0|0] "" Vector__XXX
 SG_ DAS_sw080_sensors_healty_check m80 : 16|1@1+ (1,0) [0|0] "" Vector__XXX
 SG_ DAS_sw081_radarDistance m81 : 16|8@1+ (0.0625,0) [0|0] "" Vector__XXX
 SG_ DAS_sw082_L_VL m82 : 16|8@1+ (0.05,-6.4) [0|0] "" Vector__XXX
 SG_ DAS_sw083_Targ5_RCS m83 : 16|16@1+ (0.0039063096,0) [0|0] "" Vector__XXX
 SG_ DAS_sw084_ipsoTTC m84 : 16|8@1+ (0.02,0) [0|0] "" Vector__XXX
 SG_ DAS_sw085_radarDistance m85 : 16|8@1+ (0.0625,0) [0|0] "" Vector__XXX
 SG_ DAS_sw086_distanceException m86 : 16|8@1+ (1,90) [0|0] "" Vector__XXX
 SG_ DAS_sw103_objectDx m103 : 16|8@1+ (0.5,0) [0|0] "" Vector__XXX
 SG_ DAS_sw106_torsionBarOffset m106 : 16|8@1+ (0.005,-0.64) [0|0] "" Vector__XXX
 SG_ DAS_sw129_mainCamExtNoCalFile m129 : 16|1@1+ (1,0) [0|0] "" Vector__XXX
 SG_ DAS_sw130_narrowCamExtNoCalFile m130 : 16|1@1+ (1,0) [0|0] "" Vector__XXX
 SG_ DAS_sw131_mainCamExtPitchCal m131 : 16|9@1- (0.05,0) [0|0] "" Vector__XXX
 SG_ DAS_sw132_narrowCamExtPitchCal m132 : 16|9@1- (0.05,0) [0|0] "" Vector__XXX
 SG_ DAS_sw133_mainCamDeserFault m133 : 16|3@1+ (1,0) [0|0] "" Vector__XXX
 SG_ DAS_sw134_narrowCamDeserFault m134 : 16|3@1+ (1,0) [0|0] "" Vector__XXX
 SG_ DAS_sw135_fisheyeCamDeserFault m135 : 16|3@1+ (1,0) [0|0] "" Vector__XXX
 SG_ DAS_sw136_lPillarCamDeserFault m136 : 16|3@1+ (1,0) [0|0] "" Vector__XXX
 SG_ DAS_sw137_rPillarCamDeserFault m137 : 16|3@1+ (1,0) [0|0] "" Vector__XXX
 SG_ DAS_sw138_lRepeatCamDeserFault m138 : 16|3@1+ (1,0) [0|0] "" Vector__XXX
 SG_ DAS_sw139_rhtRptrCamDeserFault m139 : 16|3@1+ (1,0) [0|0] "" Vector__XXX
 SG_ DAS_sw140_backupCamCSIBridgeFlt m140 : 16|3@1+ (1,0) [0|0] "" Vector__XXX
 SG_ DAS_sw141_maxThreshold m141 : 16|8@1- (1,0) [0|0] "" Vector__XXX
 SG_ DAS_sw142_camExtPitchCal m142 : 16|9@1+ (0.05,-12.5) [0|0] "" Vector__XXX
 SG_ DAS_sw144_selfieCamDeserFault m144 : 16|3@1+ (1,0) [0|0] "" Vector__XXX
 SG_ DAS_sw171_fisheyeCamExtNoCalFile m171 : 16|1@1+ (1,0) [0|0] "" Vector__XXX
 SG_ DAS_sw172_lPillarCamExtNoCalFile m172 : 16|1@1+ (1,0) [0|0] "" Vector__XXX
 SG_ DAS_sw173_rPillarCamExtNoCalFile m173 : 16|1@1+ (1,0) [0|0] "" Vector__XXX
 SG_ DAS_sw174_lRepeatCamExtNoCalFile m174 : 16|1@1+ (1,0) [0|0] "" Vector__XXX
 SG_ DAS_sw175_rRepeatCamExtNoCalFile m175 : 16|1@1+ (1,0) [0|0] "" Vector__XXX
 SG_ DAS_sw177_fisheyeCamExtPitchCal m177 : 16|9@1- (0.05,0) [0|0] "" Vector__XXX
 SG_ DAS_sw178_lPillarCamExtPitchCal m178 : 16|9@1- (0.05,0) [0|0] "" Vector__XXX
 SG_ DAS_sw179_rPillarCamExtPitchCal m179 : 16|9@1- (0.05,0) [0|0] "" Vector__XXX
 SG_ DAS_sw180_lRepeatCamExtPitchCal m180 : 16|9@1- (0.05,0) [0|0] "" Vector__XXX
 SG_ DAS_sw181_rRepeatCamExtPitchCal m181 : 16|9@1- (0.05,0) [0|0] "" Vector__XXX
 SG_ DAS_sw193_blurredImage m193 : 16|1@1+ (1,0) [0|0] "" Vector__XXX
 SG_ DAS_sw194_leadAx m194 : 16|6@1- (0.2,0) [0|0] "" Vector__XXX
 SG_ DAS_sw195_s1Blocked m195 : 16|1@1+ (1,0) [0|0] "" Vector__XXX
 SG_ DAS_sw198_fullBlockage m198 : 16|1@1+ (1,0) [0|0] "" Vector__XXX
 SG_ DAS_sw199_abortCodeDas m199 : 16|6@1+ (1,0) [0|0] "" Vector__XXX
 SG_ DAS_sw200_autopilotIntState m200 : 16|4@1+ (1,0) [0|0] "" Vector__XXX
 SG_ DAS_sw201_virtualLaneInputOAL m201 : 16|3@1+ (1,0) [0|0] "" Vector__XXX
 SG_ DAS_sw202_s1Blocked m202 : 16|1@1+ (1,0) [0|0] "" Vector__XXX
 SG_ DAS_sw203_controlType m203 : 16|4@1+ (1,0) [0|0] "" Vector__XXX
 SG_ DAS_sw204_frLeft m204 : 16|8@1+ (1,0) [0|0] "" Vector__XXX
 SG_ DAS_sw205_oocDistance m205 : 16|8@1+ (1,0) [0|0] "" Vector__XXX
 SG_ DAS_sw207_appMobileyeStatus m207 : 16|8@1+ (1,0) [0|0] "" Vector__XXX
 SG_ DAS_sw213_autopilotIntState m213 : 16|4@1+ (1,0) [0|0] "" Vector__XXX
 SG_ DAS_sw218_cipvDist m218 : 16|8@1+ (0.2,0) [0|0] "" Vector__XXX
 SG_ DAS_sw219_controlledAccess m219 : 16|1@1+ (1,0) [0|0] "" Vector__XXX
 SG_ DAS_sw220_controlledAccess m220 : 16|1@1+ (1,0) [0|0] "" Vector__XXX
 SG_ DAS_sw227_sensorSide m227 : 16|1@1+ (1,0) [0|0] "" Vector__XXX
 SG_ DAS_sw230_sensor1Blocked m230 : 16|1@1+ (1,0) [0|0] "" Vector__XXX
 SG_ DAS_sw231_timeToImpact m231 : 16|9@1+ (1,0) [0|0] "" Vector__XXX
 SG_ DAS_sw004_radHWFailure m4 : 17|1@1+ (1,0) [0|0] "" Vector__XXX
 SG_ DAS_sw005_AutofixOutOfCalibYaw m5 : 17|1@1+ (1,0) [0|0] "" Vector__XXX
 SG_ DAS_sw006_RadarMisaligned m6 : 17|1@1+ (1,0) [0|0] "" Vector__XXX
 SG_ DAS_sw009_DI_aeb_unresponsive m9 : 17|1@1+ (1,0) [0|0] "" Vector__XXX
 SG_ DAS_sw010_a05calibReqd m10 : 17|1@1+ (1,0) [0|0] "" Vector__XXX
 SG_ DAS_sw017_Camera_Msg_Objects_MIA m17 : 17|1@1+ (1,0) [0|0] "" Vector__XXX
 SG_ DAS_sw027_Core_Reset m27 : 17|1@1+ (1,0) [0|0] "" Vector__XXX
 SG_ DAS_sw028_rx_inv_len m28 : 17|1@1+ (1,0) [0|0] "" Vector__XXX
 SG_ DAS_sw029_unusedBits m29 : 17|15@1+ (1,0) [0|0] "" Vector__XXX
 SG_ DAS_sw038_OutOfFocusImage m38 : 17|1@1+ (1,0) [0|0] "" Vector__XXX
 SG_ DAS_sw048_thermalIssue m48 : 17|1@1+ (1,0) [0|0] "" Vector__XXX
 SG_ DAS_sw051_a02flashPerformance m51 : 17|1@1+ (1,0) [0|0] "" Vector__XXX
 SG_ DAS_sw052_sensorDirty m52 : 17|1@1+ (1,0) [0|0] "" Vector__XXX
 SG_ DAS_sw053_a11bdyMIA m53 : 17|1@1+ (1,0) [0|0] "" Vector__XXX
 SG_ DAS_sw057_dasMapDataMia m57 : 17|1@1+ (1,0) [0|0] "" Vector__XXX
 SG_ DAS_sw064_status m64 : 17|1@1+ (1,0) [0|0] "" Vector__XXX
 SG_ DAS_sw069_espMia m69 : 17|1@1+ (1,0) [0|0] "" Vector__XXX
 SG_ DAS_sw073_silentEscalatedLDW m73 : 17|1@1+ (1,0) [0|0] "" Vector__XXX
 SG_ DAS_sw080_dist_travelled_check m80 : 17|1@1+ (1,0) [0|0] "" Vector__XXX
 SG_ DAS_sw193_fullBlockage m193 : 17|1@1+ (1,0) [0|0] "" Vector__XXX
 SG_ DAS_sw195_s6Blocked m195 : 17|1@1+ (1,0) [0|0] "" Vector__XXX
 SG_ DAS_sw198_partialBlockage m198 : 17|1@1+ (1,0) [0|0] "" Vector__XXX
 SG_ DAS_sw202_s6Blocked m202 : 17|1@1+ (1,0) [0|0] "" Vector__XXX
 SG_ DAS_sw219_roadClass m219 : 17|3@1+ (1,0) [0|0] "" Vector__XXX
 SG_ DAS_sw220_roadClass m220 : 17|3@1+ (1,0) [0|0] "" Vector__XXX
 SG_ DAS_sw227_sensorNumber m227 : 17|1@1+ (1,0) [0|0] "" Vector__XXX
 SG_ DAS_sw230_sensor2Blocked m230 : 17|1@1+ (1,0) [0|0] "" Vector__XXX
 SG_ DAS_sw004_radSensorBlind m4 : 18|1@1+ (1,0) [0|0] "" Vector__XXX
 SG_ DAS_sw005_RadarMisalignment m5 : 18|1@1+ (1,0) [0|0] "" Vector__XXX
 SG_ DAS_sw006_radCalibration m6 : 18|1@1+ (1,0) [0|0] "" Vector__XXX
 SG_ DAS_sw009_DI_MIA m9 : 18|1@1+ (1,0) [0|0] "" Vector__XXX
 SG_ DAS_sw010_a06calibNotOK m10 : 18|1@1+ (1,0) [0|0] "" Vector__XXX
 SG_ DAS_sw015_RadarMisalignment m15 : 18|2@1+ (1,0) [0|0] "" Vector__XXX
 SG_ DAS_sw017_Camera_Msg_Tsr_MIA m17 : 18|1@1+ (1,0) [0|0] "" Vector__XXX
 SG_ DAS_sw026_tardiness m26 : 18|9@1+ (0.25,0) [0|0] "" Vector__XXX
 SG_ DAS_sw027_Unused_Bit_0 m27 : 18|1@1+ (1,0) [0|0] "" Vector__XXX
 SG_ DAS_sw028_inv_multifrm_1st m28 : 18|1@1+ (1,0) [0|0] "" Vector__XXX
 SG_ DAS_sw038_AutofixOutOfCalib m38 : 18|1@1+ (1,0) [0|0] "" Vector__XXX
 SG_ DAS_sw048_powerIssue m48 : 18|1@1+ (1,0) [0|0] "" Vector__XXX
 SG_ DAS_sw051_a03vBatHigh m51 : 18|1@1+ (1,0) [0|0] "" Vector__XXX
 SG_ DAS_sw052_HWFail m52 : 18|1@1+ (1,0) [0|0] "" Vector__XXX
 SG_ DAS_sw053_a12espMIA m53 : 18|1@1+ (1,0) [0|0] "" Vector__XXX
 SG_ DAS_sw057_locStatusMia m57 : 18|1@1+ (1,0) [0|0] "" Vector__XXX
 SG_ DAS_sw069_parkMia m69 : 18|1@1+ (1,0) [0|0] "" Vector__XXX
 SG_ DAS_sw073_escalateLDWreason m73 : 18|3@1+ (1,0) [0|0] "" Vector__XXX
 SG_ DAS_sw080_road_class_check m80 : 18|1@1+ (1,0) [0|0] "" Vector__XXX
 SG_ DAS_sw193_impairedVD m193 : 18|1@1+ (1,0) [0|0] "" Vector__XXX
 SG_ DAS_sw195_s7Blocked m195 : 18|1@1+ (1,0) [0|0] "" Vector__XXX
 SG_ DAS_sw198_tflMsgInvalid m198 : 18|1@1+ (1,0) [0|0] "" Vector__XXX
 SG_ DAS_sw202_s7Blocked m202 : 18|1@1+ (1,0) [0|0] "" Vector__XXX
 SG_ DAS_sw227_vehicleSpeed m227 : 18|12@1+ (0.05,-25) [0|0] "" Vector__XXX
 SG_ DAS_sw230_sensor3Blocked m230 : 18|1@1+ (1,0) [0|0] "" Vector__XXX
 SG_ DAS_sw004_radSGUFailure m4 : 19|1@1+ (1,0) [0|0] "" Vector__XXX
 SG_ DAS_sw005_partialBlockage m5 : 19|1@1+ (1,0) [0|0] "" Vector__XXX
 SG_ DAS_sw006_OutOfFocusImage m6 : 19|1@1+ (1,0) [0|0] "" Vector__XXX
 SG_ DAS_sw010_a08PlantMode m10 : 19|1@1+ (1,0) [0|0] "" Vector__XXX
 SG_ DAS_sw011_scaLeft m11 : 19|1@1+ (1,0) [0|0] "" Vector__XXX
 SG_ DAS_sw017_Camera_Msg_Hlb_MIA m17 : 19|1@1+ (1,0) [0|0] "" Vector__XXX
 SG_ DAS_sw027_CPU_Checkstop_Error m27 : 19|1@1+ (1,0) [0|0] "" Vector__XXX
 SG_ DAS_sw028_inv_multifrm_id m28 : 19|1@1+ (1,0) [0|0] "" Vector__XXX
 SG_ DAS_sw038_AutofixOutOfCalibHorzn m38 : 19|1@1+ (1,0) [0|0] "" Vector__XXX
 SG_ DAS_sw042_abort_reason m42 : 19|5@1+ (1,0) [0|0] "" Vector__XXX
 SG_ DAS_sw048_stackOverflow m48 : 19|1@1+ (1,0) [0|0] "" Vector__XXX
 SG_ DAS_sw051_a09configMismatch m51 : 19|1@1+ (1,0) [0|0] "" Vector__XXX
 SG_ DAS_sw052_overTemperature m52 : 19|1@1+ (1,0) [0|0] "" Vector__XXX
 SG_ DAS_sw053_a13gtwMIA m53 : 19|1@1+ (1,0) [0|0] "" Vector__XXX
 SG_ DAS_sw057_gpsVehSpeedMia m57 : 19|1@1+ (1,0) [0|0] "" Vector__XXX
 SG_ DAS_sw069_sccmMia m69 : 19|1@1+ (1,0) [0|0] "" Vector__XXX
 SG_ DAS_sw070_lastTireFitment m70 : 19|3@1+ (1,0) [0|0] "" Vector__XXX
 SG_ DAS_sw080_stw_angle_check m80 : 19|1@1+ (1,0) [0|0] "" Vector__XXX
 SG_ DAS_sw133_mainCamI2CbusFault m133 : 19|1@1+ (1,0) [0|0] "" Vector__XXX
 SG_ DAS_sw134_narrowCamI2CbusFault m134 : 19|1@1+ (1,0) [0|0] "" Vector__XXX
 SG_ DAS_sw135_fisheyeCamI2CbusFault m135 : 19|1@1+ (1,0) [0|0] "" Vector__XXX
 SG_ DAS_sw136_lPillarCamI2CbusFault m136 : 19|1@1+ (1,0) [0|0] "" Vector__XXX
 SG_ DAS_sw137_rPillarCamI2CbusFault m137 : 19|1@1+ (1,0) [0|0] "" Vector__XXX
 SG_ DAS_sw138_lRepeatCamI2CbusFault m138 : 19|1@1+ (1,0) [0|0] "" Vector__XXX
 SG_ DAS_sw139_rhtRptrCamI2CbusFault m139 : 19|1@1+ (1,0) [0|0] "" Vector__XXX
 SG_ DAS_sw140_backupCamDeserFault m140 : 19|3@1+ (1,0) [0|0] "" Vector__XXX
 SG_ DAS_sw144_selfieCamI2CbusFault m144 : 19|1@1+ (1,0) [0|0] "" Vector__XXX
 SG_ DAS_sw193_outOfFocusImage m193 : 19|1@1+ (1,0) [0|0] "" Vector__XXX
 SG_ DAS_sw195_s8Blocked m195 : 19|1@1+ (1,0) [0|0] "" Vector__XXX
 SG_ DAS_sw198_tsrMsgInvalid m198 : 19|1@1+ (1,0) [0|0] "" Vector__XXX
 SG_ DAS_sw201_steeringErrorOAL m201 : 19|3@1+ (1,0) [0|0] "" Vector__XXX
 SG_ DAS_sw202_s8Blocked m202 : 19|1@1+ (1,0) [0|0] "" Vector__XXX
 SG_ DAS_sw230_sensor4Blocked m230 : 19|1@1+ (1,0) [0|0] "" Vector__XXX
 SG_ DAS_sw004_radMia m4 : 20|1@1+ (1,0) [0|0] "" Vector__XXX
 SG_ DAS_sw005_fullBlockage m5 : 20|1@1+ (1,0) [0|0] "" Vector__XXX
 SG_ DAS_sw006_SunRay m6 : 20|1@1+ (1,0) [0|0] "" Vector__XXX
 SG_ DAS_sw010_HorizontalMisalignment m10 : 20|16@1+ (0.00137332,-45) [0|0] "" Vector__XXX
 SG_ DAS_sw011_scaRight m11 : 20|1@1+ (1,0) [0|0] "" Vector__XXX
 SG_ DAS_sw015_LowSun m15 : 20|2@1+ (1,0) [0|0] "" Vector__XXX
 SG_ DAS_sw017_Camera_Msg_Common_MIA m17 : 20|1@1+ (1,0) [0|0] "" Vector__XXX
 SG_ DAS_sw022_recordId m22 : 20|12@1+ (1,0) [0|0] "" Vector__XXX
 SG_ DAS_sw024_numVirtualLaneVeh m24 : 20|4@1+ (1,0) [0|0] "" Vector__XXX
 SG_ DAS_sw025_road_class m25 : 20|3@1+ (1,0) [0|0] "" Vector__XXX
 SG_ DAS_sw027_PLL_0_Failure m27 : 20|1@1+ (1,0) [0|0] "" Vector__XXX
 SG_ DAS_sw028_inv_multifrm_next m28 : 20|1@1+ (1,0) [0|0] "" Vector__XXX
 SG_ DAS_sw038_AutofixOutOfCalibYaw m38 : 20|1@1+ (1,0) [0|0] "" Vector__XXX
 SG_ DAS_sw047_roadClass m47 : 20|3@1+ (1,0) [0|0] "" Vector__XXX
 SG_ DAS_sw048_checkStop m48 : 20|1@1+ (1,0) [0|0] "" Vector__XXX
 SG_ DAS_sw051_a52radomeHtrInop m51 : 20|1@1+ (1,0) [0|0] "" Vector__XXX
 SG_ DAS_sw052_underTemperature m52 : 20|1@1+ (1,0) [0|0] "" Vector__XXX
 SG_ DAS_sw053_a14sccmMIA m53 : 20|1@1+ (1,0) [0|0] "" Vector__XXX
 SG_ DAS_sw057_dasRoadSignMia m57 : 20|1@1+ (1,0) [0|0] "" Vector__XXX
 SG_ DAS_sw069_parkMismatch m69 : 20|1@1+ (1,0) [0|0] "" Vector__XXX
 SG_ DAS_sw071_endPosX m71 : 20|10@1+ (0.05,-25.6) [0|0] "" Vector__XXX
 SG_ DAS_sw080_rad_tar_5_check m80 : 20|1@1+ (1,0) [0|0] "" Vector__XXX
 SG_ DAS_sw133_mainCamSensorFault m133 : 20|3@1+ (1,0) [0|0] "" Vector__XXX
 SG_ DAS_sw134_narrowCamSensorFault m134 : 20|3@1+ (1,0) [0|0] "" Vector__XXX
 SG_ DAS_sw135_fisheyeCamSensorFault m135 : 20|3@1+ (1,0) [0|0] "" Vector__XXX
 SG_ DAS_sw136_lPillarCamSensorFault m136 : 20|3@1+ (1,0) [0|0] "" Vector__XXX
 SG_ DAS_sw137_rPillarCamSensorFault m137 : 20|3@1+ (1,0) [0|0] "" Vector__XXX
 SG_ DAS_sw138_lRepeatCamSensorFault m138 : 20|3@1+ (1,0) [0|0] "" Vector__XXX
 SG_ DAS_sw139_rhtRptrCamSensorFault m139 : 20|3@1+ (1,0) [0|0] "" Vector__XXX
 SG_ DAS_sw144_selfieCamSensorFault m144 : 20|3@1+ (1,0) [0|0] "" Vector__XXX
 SG_ DAS_sw193_partialBlockage m193 : 20|1@1+ (1,0) [0|0] "" Vector__XXX
 SG_ DAS_sw195_s11Blocked m195 : 20|1@1+ (1,0) [0|0] "" Vector__XXX
 SG_ DAS_sw200_autopilotRestricted m200 : 20|1@1+ (1,0) [0|0] "" Vector__XXX
 SG_ DAS_sw202_s11Blocked m202 : 20|1@1+ (1,0) [0|0] "" Vector__XXX
 SG_ DAS_sw203_curbType m203 : 20|2@1+ (1,0) [0|0] "" Vector__XXX
 SG_ DAS_sw213_autopilotRestricted m213 : 20|1@1+ (1,0) [0|0] "" Vector__XXX
 SG_ DAS_sw219_vehicleSpeed m219 : 20|12@1+ (0.05,-25) [0|0] "" Vector__XXX
 SG_ DAS_sw220_vehicleSpeed m220 : 20|12@1+ (0.05,-25) [0|0] "" Vector__XXX
 SG_ DAS_sw230_sensor5Blocked m230 : 20|1@1+ (1,0) [0|0] "" Vector__XXX
 SG_ DAS_sw004_radDynamicsError m4 : 21|1@1+ (1,0) [0|0] "" Vector__XXX
 SG_ DAS_sw005_camObjHeader m5 : 21|1@1+ (1,0) [0|0] "" Vector__XXX
 SG_ DAS_sw006_Splashes m6 : 21|1@1+ (1,0) [0|0] "" Vector__XXX
 SG_ DAS_sw011_scaBlinker m11 : 21|2@1+ (1,0) [0|0] "" Vector__XXX
 SG_ DAS_sw013_numEyeqResets m13 : 21|3@1+ (1,0) [0|0] "" Vector__XXX
 SG_ DAS_sw017_Camera_Msg_FCW_PCW_MIA m17 : 21|1@1+ (1,0) [0|0] "" Vector__XXX
 SG_ DAS_sw027_Clock_Monitor_0_Low m27 : 21|1@1+ (1,0) [0|0] "" Vector__XXX
 SG_ DAS_sw028_unusedBits m28 : 21|11@1+ (1,0) [0|0] "" Vector__XXX
 SG_ DAS_sw038_FullBlockage m38 : 21|1@1+ (1,0) [0|0] "" Vector__XXX
 SG_ DAS_sw048_ecuWatchdog m48 : 21|1@1+ (1,0) [0|0] "" Vector__XXX
 SG_ DAS_sw051_unused m51 : 21|3@1+ (1,0) [0|0] "" Vector__XXX
 SG_ DAS_sw052_chirpError m52 : 21|1@1+ (1,0) [0|0] "" Vector__XXX
 SG_ DAS_sw053_a15adasMIA m53 : 21|1@1+ (1,0) [0|0] "" Vector__XXX
 SG_ DAS_sw057_radarMapDataMia m57 : 21|1@1+ (1,0) [0|0] "" Vector__XXX
 SG_ DAS_sw069_eacStatus m69 : 21|4@1+ (1,0) [0|0] "" Vector__XXX
 SG_ DAS_sw073_rawMobileyeLDW m73 : 21|2@1+ (1,0) [0|0] "" Vector__XXX
 SG_ DAS_sw080_ultrasonic_obs_check m80 : 21|1@1+ (1,0) [0|0] "" Vector__XXX
 SG_ DAS_sw193_smearedHalos m193 : 21|1@1+ (1,0) [0|0] "" Vector__XXX
 SG_ DAS_sw195_s12Blocked m195 : 21|1@1+ (1,0) [0|0] "" Vector__XXX
 SG_ DAS_sw200_endSpeed m200 : 21|10@1+ (0.1,-10) [0|0] "" Vector__XXX
 SG_ DAS_sw202_s12Blocked m202 : 21|1@1+ (1,0) [0|0] "" Vector__XXX
 SG_ DAS_sw213_endSpeed m213 : 21|10@1+ (0.1,-10) [0|0] "" Vector__XXX
 SG_ DAS_sw230_sensor6Blocked m230 : 21|1@1+ (1,0) [0|0] "" Vector__XXX
 SG_ DAS_sw004_espMIA m4 : 22|1@1+ (1,0) [0|0] "" Vector__XXX
 SG_ DAS_sw005_camCommonMsg m5 : 22|1@1+ (1,0) [0|0] "" Vector__XXX
 SG_ DAS_sw006_BlurredImage m6 : 22|1@1+ (1,0) [0|0] "" Vector__XXX
 SG_ DAS_sw015_BlurredImage m15 : 22|2@1+ (1,0) [0|0] "" Vector__XXX
 SG_ DAS_sw017_Camera_Msg_TFL_MIA m17 : 22|1@1+ (1,0) [0|0] "" Vector__XXX
 SG_ DAS_sw027_Clock_Monitor_0_Off m27 : 22|1@1+ (1,0) [0|0] "" Vector__XXX
 SG_ DAS_sw038_TooManyResets m38 : 22|1@1+ (1,0) [0|0] "" Vector__XXX
 SG_ DAS_sw048_ecuReset m48 : 22|1@1+ (1,0) [0|0] "" Vector__XXX
 SG_ DAS_sw052_rspError m52 : 22|1@1+ (1,0) [0|0] "" Vector__XXX
 SG_ DAS_sw053_a16bdyInvalidCount m53 : 22|1@1+ (1,0) [0|0] "" Vector__XXX
 SG_ DAS_sw057_csaRoadCurvMia m57 : 22|1@1+ (1,0) [0|0] "" Vector__XXX
 SG_ DAS_sw080_freespace_check m80 : 22|1@1+ (1,0) [0|0] "" Vector__XXX
 SG_ DAS_sw140_backupCamI2CbusFault m140 : 22|1@1+ (1,0) [0|0] "" Vector__XXX
 SG_ DAS_sw193_smearedSpots m193 : 22|1@1+ (1,0) [0|0] "" Vector__XXX
 SG_ DAS_sw194_leadDx m194 : 22|8@1+ (0.1,0) [0|0] "" Vector__XXX
 SG_ DAS_sw199_abortCodePARK m199 : 22|5@1+ (1,0) [0|0] "" Vector__XXX
 SG_ DAS_sw203_roadClass m203 : 22|3@1+ (1,0) [0|0] "" Vector__XXX
 SG_ DAS_sw230_sensor7Blocked m230 : 22|1@1+ (1,0) [0|0] "" Vector__XXX
 SG_ DAS_sw005_camFcwPcwMsg m5 : 23|1@1+ (1,0) [0|0] "" Vector__XXX
 SG_ DAS_sw006_LowSun m6 : 23|1@1+ (1,0) [0|0] "" Vector__XXX
 SG_ DAS_sw011_scaThreshold m11 : 23|1@1+ (1,0) [0|0] "" Vector__XXX
 SG_ DAS_sw017_Any_Lanes_Msg_Recd m17 : 23|1@1+ (1,0) [0|0] "" Vector__XXX
 SG_ DAS_sw025_road_match m25 : 23|1@1+ (1,0) [0|0] "" Vector__XXX
 SG_ DAS_sw027_LVD_4v5 m27 : 23|1@1+ (1,0) [0|0] "" Vector__XXX
 SG_ DAS_sw047_controlledAccess m47 : 23|1@1+ (1,0) [0|0] "" Vector__XXX
 SG_ DAS_sw048_radcVersionMismatch m48 : 23|1@1+ (1,0) [0|0] "" Vector__XXX
 SG_ DAS_sw052_sensorBlocked m52 : 23|1@1+ (1,0) [0|0] "" Vector__XXX
 SG_ DAS_sw053_a17adasInvalidCount m53 : 23|1@1+ (1,0) [0|0] "" Vector__XXX
 SG_ DAS_sw057_csaOfframpCurvMia m57 : 23|1@1+ (1,0) [0|0] "" Vector__XXX
 SG_ DAS_sw080_pedestrian_check m80 : 23|1@1+ (1,0) [0|0] "" Vector__XXX
 SG_ DAS_sw230_sensor8Blocked m230 : 23|1@1+ (1,0) [0|0] "" Vector__XXX
 SG_ DAS_sw004_accState m4 : 24|4@1+ (1,0) [0|0] "" Vector__XXX
 SG_ DAS_sw005_radHWFailure m5 : 24|1@1+ (1,0) [0|0] "" Vector__XXX
 SG_ DAS_sw006_SmearedSpots m6 : 24|1@1+ (1,0) [0|0] "" Vector__XXX
 SG_ DAS_sw011_scaSpeed m11 : 24|7@1+ (1,0) [0|0] "" Vector__XXX
 SG_ DAS_sw013_numCrcErrors m13 : 24|8@1+ (1,0) [0|0] "" Vector__XXX
 SG_ DAS_sw015_FullBlockage m15 : 24|2@1+ (1,0) [0|0] "" Vector__XXX
 SG_ DAS_sw017_Any_Objects_Msg_Recd m17 : 24|1@1+ (1,0) [0|0] "" Vector__XXX
 SG_ DAS_sw019_numFreeBytes m19 : 24|8@1+ (1,-191) [0|0] "" Vector__XXX
 SG_ DAS_sw021_minThreshold m21 : 24|8@1- (1,0) [0|0] "" Vector__XXX
 SG_ DAS_sw024_currentVehicleApp m24 : 24|8@1+ (1,0) [0|0] "" Vector__XXX
 SG_ DAS_sw025_controlled_access m25 : 24|1@1+ (1,0) [0|0] "" Vector__XXX
 SG_ DAS_sw027_Flash_Fatal_Error m27 : 24|1@1+ (1,0) [0|0] "" Vector__XXX
 SG_ DAS_sw030_unusedByte m30 : 24|8@1+ (1,0) [0|0] "" Vector__XXX
 SG_ DAS_sw031_errorType m31 : 24|8@1+ (1,0) [0|0] "" Vector__XXX
 SG_ DAS_sw032_errorType m32 : 24|8@1+ (1,0) [0|0] "" Vector__XXX
 SG_ DAS_sw033_unusedByte m33 : 24|8@1+ (1,0) [0|0] "" Vector__XXX
 SG_ DAS_sw034_unusedByte m34 : 24|8@1+ (1,0) [0|0] "" Vector__XXX
 SG_ DAS_sw035_unusedByte m35 : 24|8@1+ (1,0) [0|0] "" Vector__XXX
 SG_ DAS_sw036_unusedByte m36 : 24|8@1+ (1,0) [0|0] "" Vector__XXX
 SG_ DAS_sw037_issue m37 : 24|8@1+ (1,0) [0|0] "" Vector__XXX
 SG_ DAS_sw039_unusedByte m39 : 24|8@1+ (1,0) [0|0] "" Vector__XXX
 SG_ DAS_sw040_ego_veh_speed m40 : 24|8@1+ (0.2,0) [0|0] "" Vector__XXX
 SG_ DAS_sw042_view_range m42 : 24|8@1+ (1,0) [0|0] "" Vector__XXX
 SG_ DAS_sw044_appStatus m44 : 24|4@1+ (1,0) [0|0] "" Vector__XXX
 SG_ DAS_sw045_unusedByte m45 : 24|8@1+ (1,0) [0|0] "" Vector__XXX
 SG_ DAS_sw047_edrType m47 : 24|6@1+ (1,0) [0|0] "" Vector__XXX
 SG_ DAS_sw048_radcCalibration m48 : 24|1@1+ (1,0) [0|0] "" Vector__XXX
 SG_ DAS_sw051_SCUTemperature m51 : 24|8@1- (1,0) [0|0] "" Vector__XXX
 SG_ DAS_sw053_a18espInvalidCount m53 : 24|1@1+ (1,0) [0|0] "" Vector__XXX
 SG_ DAS_sw054_Autofix_horizon m54 : 24|8@1+ (1,0) [0|0] "" Vector__XXX
 SG_ DAS_sw056_unusedByte m56 : 24|8@1+ (1,0) [0|0] "" Vector__XXX
 SG_ DAS_sw057_telemetryControlMia m57 : 24|1@1+ (1,0) [0|0] "" Vector__XXX
 SG_ DAS_sw058_unusedByte m58 : 24|8@1+ (1,0) [0|0] "" Vector__XXX
 SG_ DAS_sw059_unusedByte m59 : 24|8@1+ (1,0) [0|0] "" Vector__XXX
 SG_ DAS_sw061_unusedByte m61 : 24|8@1+ (1,0) [0|0] "" Vector__XXX
 SG_ DAS_sw063_detectedMajorVer m63 : 24|8@1+ (1,0) [0|0] "" Vector__XXX
 SG_ DAS_sw065_mobileye_main_state m65 : 24|8@1+ (1,0) [0|0] "" Vector__XXX
 SG_ DAS_sw066_mobileye_main_state m66 : 24|8@1+ (1,0) [0|0] "" Vector__XXX
 SG_ DAS_sw070_diGear m70 : 24|3@1+ (1,0) [0|0] "" Vector__XXX
 SG_ DAS_sw073_freespaceLDW m73 : 24|2@1+ (1,0) [0|0] "" Vector__XXX
 SG_ DAS_sw074_ipsoDy m74 : 24|6@1+ (0.1,-3.2) [0|0] "" Vector__XXX
 SG_ DAS_sw075_unusedByte m75 : 24|8@1+ (1,0) [0|0] "" Vector__XXX
 SG_ DAS_sw078_ttc m78 : 24|8@1+ (0.02,0) [0|0] "" Vector__XXX
 SG_ DAS_sw080_rad_tar_5_dist m80 : 24|6@1+ (1,0) [0|0] "" Vector__XXX
 SG_ DAS_sw081_radarTTC m81 : 24|8@1+ (0.02,0) [0|0] "" Vector__XXX
 SG_ DAS_sw082_R_VL m82 : 24|8@1+ (0.05,-6.4) [0|0] "" Vector__XXX
 SG_ DAS_sw084_ipsoRCS m84 : 24|8@1+ (1,0) [0|0] "" Vector__XXX
 SG_ DAS_sw085_radarTTC m85 : 24|8@1+ (0.02,0) [0|0] "" Vector__XXX
 SG_ DAS_sw086_distanceEllipse m86 : 24|8@1+ (0.5,0) [0|0] "" Vector__XXX
 SG_ DAS_sw103_objectRCS m103 : 24|8@1+ (1,0) [0|0] "" Vector__XXX
 SG_ DAS_sw133_mainCamSerFault m133 : 24|3@1+ (1,0) [0|0] "" Vector__XXX
 SG_ DAS_sw134_narrowCamSerFault m134 : 24|3@1+ (1,0) [0|0] "" Vector__XXX
 SG_ DAS_sw135_fisheyeCamSerFault m135 : 24|3@1+ (1,0) [0|0] "" Vector__XXX
 SG_ DAS_sw136_lPillarCamSerFault m136 : 24|3@1+ (1,0) [0|0] "" Vector__XXX
 SG_ DAS_sw137_rPillarCamSerFault m137 : 24|3@1+ (1,0) [0|0] "" Vector__XXX
 SG_ DAS_sw138_lRepeatCamSerFault m138 : 24|3@1+ (1,0) [0|0] "" Vector__XXX
 SG_ DAS_sw139_rhtRptrCamSerFault m139 : 24|3@1+ (1,0) [0|0] "" Vector__XXX
 SG_ DAS_sw140_backupCamSensorFault m140 : 24|3@1+ (1,0) [0|0] "" Vector__XXX
 SG_ DAS_sw141_minThreshold m141 : 24|8@1- (1,0) [0|0] "" Vector__XXX
 SG_ DAS_sw144_selfieCamSerFault m144 : 24|3@1+ (1,0) [0|0] "" Vector__XXX
 SG_ DAS_sw195_sdiFrontCC m195 : 24|5@1+ (1,0) [0|0] "" Vector__XXX
 SG_ DAS_sw201_stwAngleReq m201 : 24|8@1- (1,0) [0|0] "" Vector__XXX
 SG_ DAS_sw202_sdiFrontCC m202 : 24|5@1+ (1,0) [0|0] "" Vector__XXX
 SG_ DAS_sw204_frLeftMiddle m204 : 24|8@1+ (1,0) [0|0] "" Vector__XXX
 SG_ DAS_sw205_rrLeft m205 : 24|8@1+ (1,0) [0|0] "" Vector__XXX
 SG_ DAS_sw207_eyeq3MainState m207 : 24|8@1+ (1,0) [0|0] "" Vector__XXX
 SG_ DAS_sw218_drivingOnHighway m218 : 24|1@1+ (1,0) [0|0] "" Vector__XXX
 SG_ DAS_sw230_sensor9Blocked m230 : 24|1@1+ (1,0) [0|0] "" Vector__XXX
 SG_ DAS_sw005_radSensorBlind m5 : 25|1@1+ (1,0) [0|0] "" Vector__XXX
 SG_ DAS_sw006_PartialBlockage m6 : 25|1@1+ (1,0) [0|0] "" Vector__XXX
 SG_ DAS_sw016_targetRelSpeed m16 : 25|9@1+ (0.0625,-31) [0|0] "" Vector__XXX
 SG_ DAS_sw017_Any_TFL_Msg_Recd m17 : 25|1@1+ (1,0) [0|0] "" Vector__XXX
 SG_ DAS_sw025_leftLaneUsage m25 : 25|2@1+ (1,0) [0|0] "" Vector__XXX
 SG_ DAS_sw027_PLL_1_Failure m27 : 25|1@1+ (1,0) [0|0] "" Vector__XXX
 SG_ DAS_sw048_radcMia m48 : 25|1@1+ (1,0) [0|0] "" Vector__XXX
 SG_ DAS_sw050_targetRelSpeed m50 : 25|9@1+ (0.0625,-31) [0|0] "" Vector__XXX
 SG_ DAS_sw053_a19sccmInvalidCount m53 : 25|1@1+ (1,0) [0|0] "" Vector__XXX
 SG_ DAS_sw057_phoneLocStatusMia m57 : 25|1@1+ (1,0) [0|0] "" Vector__XXX
 SG_ DAS_sw060_targetRelSpeed m60 : 25|9@1+ (0.0625,-31) [0|0] "" Vector__XXX
 SG_ DAS_sw069_diAPState m69 : 25|4@1+ (1,0) [0|0] "" Vector__XXX
 SG_ DAS_sw076_targetRelSpeed m76 : 25|9@1+ (0.0625,-31) [0|0] "" Vector__XXX
 SG_ DAS_sw077_oocConfidence m77 : 25|7@1+ (1,0) [0|0] "" Vector__XXX
 SG_ DAS_sw131_mainCamExtRollCal m131 : 25|9@1- (0.05,0) [0|0] "" Vector__XXX
 SG_ DAS_sw132_narrowCamExtRollCal m132 : 25|9@1- (0.05,0) [0|0] "" Vector__XXX
 SG_ DAS_sw142_pitchOffsetAtmptVal m142 : 25|9@1+ (1,-256) [0|0] "" Vector__XXX
 SG_ DAS_sw177_fisheyeCamExtRollCal m177 : 25|9@1- (0.05,0) [0|0] "" Vector__XXX
 SG_ DAS_sw178_lPillarCamExtRollCal m178 : 25|9@1- (0.05,0) [0|0] "" Vector__XXX
 SG_ DAS_sw179_rPillarCamExtRollCal m179 : 25|9@1- (0.05,0) [0|0] "" Vector__XXX
 SG_ DAS_sw180_lRepeatCamExtRollCal m180 : 25|9@1- (0.05,0) [0|0] "" Vector__XXX
 SG_ DAS_sw181_rRepeatCamExtRollCal m181 : 25|9@1- (0.05,0) [0|0] "" Vector__XXX
 SG_ DAS_sw203_slotSizeX m203 : 25|8@1+ (4,0) [0|0] "" Vector__XXX
 SG_ DAS_sw218_handsOnState m218 : 25|4@1+ (1,0) [0|0] "" Vector__XXX
 SG_ DAS_sw230_sensor10Blocked m230 : 25|1@1+ (1,0) [0|0] "" Vector__XXX
 SG_ DAS_sw231_predImpactVelocity m231 : 25|7@1+ (0.5,0) [0|0] "" Vector__XXX
 SG_ DAS_sw005_radSGUFailure m5 : 26|1@1+ (1,0) [0|0] "" Vector__XXX
 SG_ DAS_sw006_AutofixOutOfCalib m6 : 26|1@1+ (1,0) [0|0] "" Vector__XXX
 SG_ DAS_sw015_PartialBlockage m15 : 26|2@1+ (1,0) [0|0] "" Vector__XXX
 SG_ DAS_sw017_numCrcErrors m17 : 26|6@1+ (1,0) [0|0] "" Vector__XXX
 SG_ DAS_sw027_Unused_Bit_1 m27 : 26|1@1+ (1,0) [0|0] "" Vector__XXX
 SG_ DAS_sw041_max_rate m41 : 26|10@1- (1,0) [0|0] "" Vector__XXX
 SG_ DAS_sw048_eyeQVersionMismatch m48 : 26|1@1+ (1,0) [0|0] "" Vector__XXX
 SG_ DAS_sw053_a20bdyInvalidChkSm m53 : 26|1@1+ (1,0) [0|0] "" Vector__XXX
 SG_ DAS_sw068_virtualLaneSTW m68 : 26|14@1+ (0.1,-819.2) [0|0] "" Vector__XXX
 SG_ DAS_sw072_vehicleY m72 : 26|10@1+ (0.05,-25.6) [0|0] "" Vector__XXX
 SG_ DAS_sw073_freespaceLeftC0 m73 : 26|7@1+ (0.2,-12.8) [0|0] "" Vector__XXX
 SG_ DAS_sw230_sensor11Blocked m230 : 26|1@1+ (1,0) [0|0] "" Vector__XXX
 SG_ DAS_sw005_radMia m5 : 27|1@1+ (1,0) [0|0] "" Vector__XXX
 SG_ DAS_sw006_AutofixOutOfCalibHorzn m6 : 27|1@1+ (1,0) [0|0] "" Vector__XXX
 SG_ DAS_sw025_rightLaneUsage m25 : 27|2@1+ (1,0) [0|0] "" Vector__XXX
 SG_ DAS_sw026_execution_time m26 : 27|9@1+ (0.125,0) [0|0] "" Vector__XXX
 SG_ DAS_sw027_f_PLL_1_Off m27 : 27|1@1+ (1,0) [0|0] "" Vector__XXX
 SG_ DAS_sw048_camIssue m48 : 27|1@1+ (1,0) [0|0] "" Vector__XXX
 SG_ DAS_sw053_a21espInvalidChkSm m53 : 27|1@1+ (1,0) [0|0] "" Vector__XXX
 SG_ DAS_sw070_driveRail m70 : 27|1@1+ (1,0) [0|0] "" Vector__XXX
 SG_ DAS_sw140_backupCamUARTbusFault m140 : 27|1@1+ (1,0) [0|0] "" Vector__XXX
 SG_ DAS_sw199_currentSTW m199 : 27|14@1+ (0.1,-819.2) [0|0] "" Vector__XXX
 SG_ DAS_sw230_sensor12Blocked m230 : 27|1@1+ (1,0) [0|0] "" Vector__XXX
 SG_ DAS_sw004_appMobileyeStatus m4 : 28|5@1+ (1,0) [0|0] "" Vector__XXX
 SG_ DAS_sw005_radCalibration m5 : 28|1@1+ (1,0) [0|0] "" Vector__XXX
 SG_ DAS_sw006_AutofixOutOfCalibYaw m6 : 28|1@1+ (1,0) [0|0] "" Vector__XXX
 SG_ DAS_sw015_AutofixOutOfCalib m15 : 28|2@1+ (1,0) [0|0] "" Vector__XXX
 SG_ DAS_sw027_Unused_Nibble m27 : 28|4@1+ (1,0) [0|0] "" Vector__XXX
 SG_ DAS_sw044_meMainState m44 : 28|4@1+ (1,0) [0|0] "" Vector__XXX
 SG_ DAS_sw048_parkerIssue m48 : 28|1@1+ (1,0) [0|0] "" Vector__XXX
 SG_ DAS_sw053_a22sccmInvalidChkSm m53 : 28|1@1+ (1,0) [0|0] "" Vector__XXX
 SG_ DAS_sw070_accRail m70 : 28|1@1+ (1,0) [0|0] "" Vector__XXX
 SG_ DAS_sw140_backupCamHDMISerFault m140 : 28|1@1+ (1,0) [0|0] "" Vector__XXX
 SG_ DAS_sw005_brakePedal m5 : 29|1@1+ (1,0) [0|0] "" Vector__XXX
 SG_ DAS_sw006_FullBlockage m6 : 29|1@1+ (1,0) [0|0] "" Vector__XXX
 SG_ DAS_sw018_railID m18 : 29|2@1+ (1,0) [0|0] "" Vector__XXX
 SG_ DAS_sw025_vehiclesUsage m25 : 29|2@1+ (1,0) [0|0] "" Vector__XXX
 SG_ DAS_sw048_prolongedUiMia m48 : 29|1@1+ (1,0) [0|0] "" Vector__XXX
 SG_ DAS_sw053_a23sccmInvalidChkSm m53 : 29|1@1+ (1,0) [0|0] "" Vector__XXX
 SG_ DAS_sw069_parkCal m69 : 29|1@1+ (1,0) [0|0] "" Vector__XXX
 SG_ DAS_sw218_mcuAutosteerRestricted m218 : 29|1@1+ (1,0) [0|0] "" Vector__XXX
 SG_ DAS_sw005_steeringAngle m5 : 30|1@1+ (1,0) [0|0] "" Vector__XXX
 SG_ DAS_sw006_SmearedHalos m6 : 30|1@1+ (1,0) [0|0] "" Vector__XXX
 SG_ DAS_sw015_AutofixOutOfCalibYaw m15 : 30|2@1+ (1,0) [0|0] "" Vector__XXX
 SG_ DAS_sw047_edrBlackBox m47 : 30|2@1+ (1,0) [0|0] "" Vector__XXX
 SG_ DAS_sw048_uiMiaAtBootup m48 : 30|1@1+ (1,0) [0|0] "" Vector__XXX
 SG_ DAS_sw053_a24absValidity m53 : 30|1@1+ (1,0) [0|0] "" Vector__XXX
 SG_ DAS_sw067_epasSTW m67 : 30|14@1+ (0.1,-819.2) [0|0] "" Vector__XXX
 SG_ DAS_sw069_torsionBar m69 : 30|12@1+ (0.01,-20.5) [0|0] "" Vector__XXX
 SG_ DAS_sw071_endPosY m71 : 30|10@1+ (0.05,-25.6) [0|0] "" Vector__XXX
 SG_ DAS_sw194_leadVx m194 : 30|6@1- (0.2,0) [0|0] "" Vector__XXX
 SG_ DAS_sw227_sensorMeasurement m227 : 30|9@1+ (1,0) [0|0] "" Vector__XXX
 SG_ DAS_sw005_steeringAngleRate m5 : 31|1@1+ (1,0) [0|0] "" Vector__XXX
 SG_ DAS_sw006_FoggyLights m6 : 31|1@1+ (1,0) [0|0] "" Vector__XXX
 SG_ DAS_sw018_powerSequnceError m18 : 31|1@1+ (1,0) [0|0] "" Vector__XXX
 SG_ DAS_sw053_a25ambTValidity m53 : 31|1@1+ (1,0) [0|0] "" Vector__XXX
 SG_ DAS_sw200_epasHandsOnDetected m200 : 31|1@1+ (1,0) [0|0] "" Vector__XXX
 SG_ DAS_sw213_epasHandsOnDetected m213 : 31|1@1+ (1,0) [0|0] "" Vector__XXX
 SG_ DAS_sw005_speed m5 : 32|1@1+ (1,0) [0|0] "" Vector__XXX
 SG_ DAS_sw006_SelfGlare m6 : 32|1@1+ (1,0) [0|0] "" Vector__XXX
 SG_ DAS_sw011_scaSonicDist m11 : 32|5@1+ (0.05,0) [0|0] "" Vector__XXX
 SG_ DAS_sw012_bootDDRTempStatus m12 : 32|2@1+ (1,0) [0|0] "" Vector__XXX
 SG_ DAS_sw013_numSeqErrors m13 : 32|8@1+ (1,0) [0|0] "" Vector__XXX
 SG_ DAS_sw014_lineNumberInCode m14 : 32|16@1+ (1,0) [0|0] "" Vector__XXX
 SG_ DAS_sw015_AutofixOOfCalibHorizon m15 : 32|2@1+ (1,0) [0|0] "" Vector__XXX
 SG_ DAS_sw017_numSeqErrors m17 : 32|8@1+ (1,0) [0|0] "" Vector__XXX
 SG_ DAS_sw018_maxThreshold m18 : 32|15@1+ (1,50) [0|0] "" Vector__XXX
 SG_ DAS_sw019_timeStamp m19 : 32|32@1+ (1,0) [0|0] "" Vector__XXX
 SG_ DAS_sw020_unusedW1 m20 : 32|16@1+ (1,0) [0|0] "" Vector__XXX
 SG_ DAS_sw021_maxThreshold m21 : 32|8@1- (1,0) [0|0] "" Vector__XXX
 SG_ DAS_sw022_errorCode m22 : 32|32@1+ (1,0) [0|0] "" Vector__XXX
 SG_ DAS_sw024_taskProgramCounter m24 : 32|32@1+ (1,0) [0|0] "" Vector__XXX
 SG_ DAS_sw025_hppUsage m25 : 32|2@1+ (1,0) [0|0] "" Vector__XXX
 SG_ DAS_sw027_LVD_1v2 m27 : 32|1@1+ (1,0) [0|0] "" Vector__XXX
 SG_ DAS_sw028_highestSeqRcvd m28 : 32|16@1+ (1,0) [0|0] "" Vector__XXX
 SG_ DAS_sw029_highestSeqRcvd m29 : 32|16@1+ (1,0) [0|0] "" Vector__XXX
 SG_ DAS_sw030_unusedW0 m30 : 32|16@1+ (1,0) [0|0] "" Vector__XXX
 SG_ DAS_sw031_errorData1 m31 : 32|16@1+ (1,0) [0|0] "" Vector__XXX
 SG_ DAS_sw032_errorData1 m32 : 32|16@1+ (1,0) [0|0] "" Vector__XXX
 SG_ DAS_sw033_unusedW0 m33 : 32|16@1+ (1,0) [0|0] "" Vector__XXX
 SG_ DAS_sw034_unusedW0 m34 : 32|16@1+ (1,0) [0|0] "" Vector__XXX
 SG_ DAS_sw035_unusedW0 m35 : 32|16@1+ (1,0) [0|0] "" Vector__XXX
 SG_ DAS_sw036_unusedW0 m36 : 32|16@1+ (1,0) [0|0] "" Vector__XXX
 SG_ DAS_sw037_unusedW0 m37 : 32|16@1+ (1,0) [0|0] "" Vector__XXX
 SG_ DAS_sw039_unusedW0 m39 : 32|16@1+ (1,0) [0|0] "" Vector__XXX
 SG_ DAS_sw040_das_steering_req m40 : 32|8@1+ (1,-128) [0|0] "" Vector__XXX
 SG_ DAS_sw042_state_before_abort m42 : 32|4@1+ (1,0) [0|0] "" Vector__XXX
 SG_ DAS_sw043_mesp_health_main_state m43 : 32|16@1+ (1,0) [0|0] "" Vector__XXX
 SG_ DAS_sw044_timestampms m44 : 32|32@1+ (1,0) [0|0] "" Vector__XXX
 SG_ DAS_sw045_unusedW0 m45 : 32|16@1+ (1,0) [0|0] "" Vector__XXX
 SG_ DAS_sw046_errorCode m46 : 32|32@1+ (1,0) [0|0] "" Vector__XXX
 SG_ DAS_sw047_edrReturn m47 : 32|16@1+ (1,0) [0|0] "" Vector__XXX
 SG_ DAS_sw049_app_version_msw m49 : 32|16@1+ (1,0) [0|0] "" Vector__XXX
 SG_ DAS_sw051_HWFail m51 : 32|1@1+ (1,0) [0|0] "" Vector__XXX
 SG_ DAS_sw053_a26brakeValidity m53 : 32|1@1+ (1,0) [0|0] "" Vector__XXX
 SG_ DAS_sw054_Autofix_yaw m54 : 32|8@1+ (1,0) [0|0] "" Vector__XXX
 SG_ DAS_sw056_unusedW0 m56 : 32|16@1+ (1,0) [0|0] "" Vector__XXX
 SG_ DAS_sw058_unusedW0 m58 : 32|16@1+ (1,0) [0|0] "" Vector__XXX
 SG_ DAS_sw059_unusedW0 m59 : 32|16@1+ (1,0) [0|0] "" Vector__XXX
 SG_ DAS_sw061_unusedW0 m61 : 32|16@1+ (1,0) [0|0] "" Vector__XXX
 SG_ DAS_sw062_VerticalMisalignment m62 : 32|10@1+ (0.087977,-45) [0|0] "" Vector__XXX
 SG_ DAS_sw063_expectedMinorVer m63 : 32|8@1+ (1,0) [0|0] "" Vector__XXX
 SG_ DAS_sw065_unusedW0 m65 : 32|16@1+ (1,0) [0|0] "" Vector__XXX
 SG_ DAS_sw066_unusedW0 m66 : 32|16@1+ (1,0) [0|0] "" Vector__XXX
 SG_ DAS_sw070_temperature m70 : 32|8@1+ (0.5,-40) [0|0] "" Vector__XXX
 SG_ DAS_sw074_ipsoDz m74 : 32|6@1+ (0.2,-6.4) [0|0] "" Vector__XXX
 SG_ DAS_sw075_unusedW0 m75 : 32|16@1+ (1,0) [0|0] "" Vector__XXX
 SG_ DAS_sw077_oocCollisionSide m77 : 32|3@1+ (1,0) [0|0] "" Vector__XXX
 SG_ DAS_sw078_radarTarg5_dx m78 : 32|8@1+ (0.0625,0) [0|0] "" Vector__XXX
 SG_ DAS_sw080_stw_angle_deg m80 : 32|8@1+ (1,0) [0|0] "" Vector__XXX
 SG_ DAS_sw081_cameraDistance m81 : 32|8@1+ (0.0625,0) [0|0] "" Vector__XXX
 SG_ DAS_sw082_L_Lane m82 : 32|8@1+ (0.05,-6.4) [0|0] "" Vector__XXX
 SG_ DAS_sw083_Targ5_dx m83 : 32|12@1+ (0.0625,0) [0|0] "" Vector__XXX
 SG_ DAS_sw084_ipsoDx m84 : 32|8@1+ (0.1,0) [0|0] "" Vector__XXX
 SG_ DAS_sw085_roadClass m85 : 32|3@1+ (1,0) [0|0] "" Vector__XXX
 SG_ DAS_sw086_ellipseWidth m86 : 32|8@1+ (0.1,0) [0|0] "" Vector__XXX
 SG_ DAS_sw103_objectDy m103 : 32|8@1+ (0.5,-15.5) [0|0] "" Vector__XXX
 SG_ DAS_sw141_tempSensorId m141 : 32|8@1+ (1,0) [0|0] "" Vector__XXX
 SG_ DAS_sw195_sdiRearCC m195 : 32|5@1+ (1,0) [0|0] "" Vector__XXX
 SG_ DAS_sw200_startSpeed m200 : 32|10@1+ (0.1,-10) [0|0] "" Vector__XXX
 SG_ DAS_sw201_timeHorizon m201 : 32|8@1+ (0.1,0) [0|0] "" Vector__XXX
 SG_ DAS_sw202_sdiRearCC m202 : 32|5@1+ (1,0) [0|0] "" Vector__XXX
 SG_ DAS_sw204_frMiddle m204 : 32|8@1+ (1,0) [0|0] "" Vector__XXX
 SG_ DAS_sw205_rrLeftMiddle m205 : 32|8@1+ (1,0) [0|0] "" Vector__XXX
 SG_ DAS_sw207_lcUnavailableReason m207 : 32|8@1+ (1,0) [0|0] "" Vector__XXX
 SG_ DAS_sw213_startSpeed m213 : 32|10@1+ (0.1,-10) [0|0] "" Vector__XXX
 SG_ DAS_sw218_pedalPosition m218 : 32|7@1+ (1,0) [0|0] "" Vector__XXX
 SG_ DAS_sw231_targetDistance m231 : 32|7@1+ (0.1,0) [0|0] "" Vector__XXX
 SG_ DAS_sw004_diCruiseStateFault m4 : 33|1@1+ (1,0) [0|0] "" Vector__XXX
 SG_ DAS_sw005_gear m5 : 33|1@1+ (1,0) [0|0] "" Vector__XXX
 SG_ DAS_sw006_blinkers m6 : 33|1@1+ (1,0) [0|0] "" Vector__XXX
 SG_ DAS_sw027_Unused_Bit_2 m27 : 33|1@1+ (1,0) [0|0] "" Vector__XXX
 SG_ DAS_sw051_SGUFail m51 : 33|1@1+ (1,0) [0|0] "" Vector__XXX
 SG_ DAS_sw053_a27CntryCdValidity m53 : 33|1@1+ (1,0) [0|0] "" Vector__XXX
 SG_ DAS_sw073_freespaceRightC0 m73 : 33|7@1+ (0.2,-12.8) [0|0] "" Vector__XXX
 SG_ DAS_sw203_slotSizeY m203 : 33|8@1+ (4,0) [0|0] "" Vector__XXX
 SG_ DAS_sw004_diMIA m4 : 34|1@1+ (1,0) [0|0] "" Vector__XXX
 SG_ DAS_sw005_stabilityControl m5 : 34|1@1+ (1,0) [0|0] "" Vector__XXX
 SG_ DAS_sw006_seatbelt m6 : 34|1@1+ (1,0) [0|0] "" Vector__XXX
 SG_ DAS_sw012_mespFatalErrCode m12 : 34|8@1+ (1,0) [0|0] "" Vector__XXX
 SG_ DAS_sw015_Splashes m15 : 34|2@1+ (1,0) [0|0] "" Vector__XXX
 SG_ DAS_sw016_targetOverlap m16 : 34|6@1+ (0.1,0) [0|0] "" Vector__XXX
 SG_ DAS_sw025_navigationUsage m25 : 34|2@1+ (1,0) [0|0] "" Vector__XXX
 SG_ DAS_sw027_Watchdog m27 : 34|1@1+ (1,0) [0|0] "" Vector__XXX
 SG_ DAS_sw050_targetOverlap m50 : 34|6@1+ (0.1,0) [0|0] "" Vector__XXX
 SG_ DAS_sw051_unusedBits m51 : 34|6@1+ (1,0) [0|0] "" Vector__XXX
 SG_ DAS_sw053_a28espValidity m53 : 34|1@1+ (1,0) [0|0] "" Vector__XXX
 SG_ DAS_sw060_targetOverlap m60 : 34|6@1+ (0.1,0) [0|0] "" Vector__XXX
 SG_ DAS_sw076_targetOverlap m76 : 34|6@1+ (0.1,0) [0|0] "" Vector__XXX
 SG_ DAS_sw131_mainCamExtYawCal m131 : 34|9@1- (0.05,0) [0|0] "" Vector__XXX
 SG_ DAS_sw132_narrowCamExtYawCal m132 : 34|9@1- (0.05,0) [0|0] "" Vector__XXX
 SG_ DAS_sw142_problemCamPosition m142 : 34|4@1+ (1,0) [0|0] "" Vector__XXX
 SG_ DAS_sw177_fisheyeCamExtYawCal m177 : 34|9@1- (0.05,0) [0|0] "" Vector__XXX
 SG_ DAS_sw178_lPillarCamExtYawCal m178 : 34|9@1- (0.05,0) [0|0] "" Vector__XXX
 SG_ DAS_sw179_rPillarCamExtYawCal m179 : 34|9@1- (0.05,0) [0|0] "" Vector__XXX
 SG_ DAS_sw180_lRepeatCamExtYawCal m180 : 34|9@1- (0.05,0) [0|0] "" Vector__XXX
 SG_ DAS_sw181_rRepeatCamExtYawCal m181 : 34|9@1- (0.05,0) [0|0] "" Vector__XXX
 SG_ DAS_sw004_accelPedalInvalid m4 : 35|1@1+ (1,0) [0|0] "" Vector__XXX
 SG_ DAS_sw005_blinkers m5 : 35|1@1+ (1,0) [0|0] "" Vector__XXX
 SG_ DAS_sw006_accelPedal m6 : 35|1@1+ (1,0) [0|0] "" Vector__XXX
 SG_ DAS_sw027_Unused_Bit_3 m27 : 35|1@1+ (1,0) [0|0] "" Vector__XXX
 SG_ DAS_sw053_a29longAccOffValidity m53 : 35|1@1+ (1,0) [0|0] "" Vector__XXX
 SG_ DAS_sw077_oocHeight m77 : 35|2@1+ (1,0) [0|0] "" Vector__XXX
 SG_ DAS_sw085_leftLaneExist m85 : 35|6@1+ (2,0) [0|0] "" Vector__XXX
 SG_ DAS_sw004_stwAngleInvalid m4 : 36|1@1+ (1,0) [0|0] "" Vector__XXX
 SG_ DAS_sw005_yaw m5 : 36|1@1+ (1,0) [0|0] "" Vector__XXX
 SG_ DAS_sw006_radMia m6 : 36|1@1+ (1,0) [0|0] "" Vector__XXX
 SG_ DAS_sw010_VerticalMisalignment m10 : 36|10@1+ (0.087977,-45) [0|0] "" Vector__XXX
 SG_ DAS_sw015_SmearedSpots m15 : 36|2@1+ (1,0) [0|0] "" Vector__XXX
 SG_ DAS_sw025_modelUsage m25 : 36|2@1+ (1,0) [0|0] "" Vector__XXX
 SG_ DAS_sw026_can_mean_utilization m26 : 36|7@1+ (1,0) [0|0] "" Vector__XXX
 SG_ DAS_sw027_LVD_2v7_VREG m27 : 36|1@1+ (1,0) [0|0] "" Vector__XXX
 SG_ DAS_sw041_ego_speed m41 : 36|10@1+ (0.05,0) [0|0] "" Vector__XXX
 SG_ DAS_sw042_epas_error_code m42 : 36|4@1+ (1,0) [0|0] "" Vector__XXX
 SG_ DAS_sw053_a30longAccValidity m53 : 36|1@1+ (1,0) [0|0] "" Vector__XXX
 SG_ DAS_sw072_vehicleHeading m72 : 36|10@1+ (0.005,-2.56) [0|0] "" Vector__XXX
 SG_ DAS_sw194_numObstacles m194 : 36|4@1+ (1,0) [0|0] "" Vector__XXX
 SG_ DAS_sw004_accelerationInvalid m4 : 37|1@1+ (1,0) [0|0] "" Vector__XXX
 SG_ DAS_sw005_longAccel m5 : 37|1@1+ (1,0) [0|0] "" Vector__XXX
 SG_ DAS_sw006_radHWFailure m6 : 37|1@1+ (1,0) [0|0] "" Vector__XXX
 SG_ DAS_sw011_scaSteerAngle m11 : 37|10@1+ (0.1,-51.2) [0|0] "" Vector__XXX
 SG_ DAS_sw027_LVD_2v7_Flash m27 : 37|1@1+ (1,0) [0|0] "" Vector__XXX
 SG_ DAS_sw053_a31odoValidity m53 : 37|1@1+ (1,0) [0|0] "" Vector__XXX
 SG_ DAS_sw077_vehicleSpeed m77 : 37|10@1+ (0.05,-25) [0|0] "" Vector__XXX
 SG_ DAS_sw195_sdiSystemNoise m195 : 37|2@1+ (1,0) [0|0] "" Vector__XXX
 SG_ DAS_sw202_sdiSystemNoise m202 : 37|2@1+ (1,0) [0|0] "" Vector__XXX
 SG_ DAS_sw004_diSpeedInvalid m4 : 38|1@1+ (1,0) [0|0] "" Vector__XXX
 SG_ DAS_sw005_accelPedal m5 : 38|1@1+ (1,0) [0|0] "" Vector__XXX
 SG_ DAS_sw006_radSensorBlind m6 : 38|1@1+ (1,0) [0|0] "" Vector__XXX
 SG_ DAS_sw015_SmearedHalos m15 : 38|2@1+ (1,0) [0|0] "" Vector__XXX
 SG_ DAS_sw025_bottsDotsUsage m25 : 38|2@1+ (1,0) [0|0] "" Vector__XXX
 SG_ DAS_sw027_LVD_2v7_IO m27 : 38|1@1+ (1,0) [0|0] "" Vector__XXX
 SG_ DAS_sw053_a32gearValidity m53 : 38|1@1+ (1,0) [0|0] "" Vector__XXX
 SG_ DAS_sw004_DASFeaturesDisabled m4 : 39|1@1+ (1,0) [0|0] "" Vector__XXX
 SG_ DAS_sw005_fcmSensitivity m5 : 39|1@1+ (1,0) [0|0] "" Vector__XXX
 SG_ DAS_sw006_radSGUFailure m6 : 39|1@1+ (1,0) [0|0] "" Vector__XXX
 SG_ DAS_sw027_Unused_Bit_4 m27 : 39|1@1+ (1,0) [0|0] "" Vector__XXX
 SG_ DAS_sw053_a33steerAngValidity m53 : 39|1@1+ (1,0) [0|0] "" Vector__XXX
 SG_ DAS_sw195_sdiSystemStatus m195 : 39|1@1+ (1,0) [0|0] "" Vector__XXX
 SG_ DAS_sw202_sdiSystemStatus m202 : 39|1@1+ (1,0) [0|0] "" Vector__XXX
 SG_ DAS_sw231_targetRelVelocity m231 : 39|6@1+ (0.5,0) [0|0] "" Vector__XXX
 SG_ DAS_sw004_appMobileyeNotInVision m4 : 40|1@1+ (1,0) [0|0] "" Vector__XXX
 SG_ DAS_sw005_dasDisabled m5 : 40|1@1+ (1,0) [0|0] "" Vector__XXX
 SG_ DAS_sw006_brakePedal m6 : 40|1@1+ (1,0) [0|0] "" Vector__XXX
 SG_ DAS_sw013_numNaksReceived m13 : 40|8@1+ (1,0) [0|0] "" Vector__XXX
 SG_ DAS_sw015_FoggyLights m15 : 40|2@1+ (1,0) [0|0] "" Vector__XXX
 SG_ DAS_sw016_hostSpeed m16 : 40|8@1+ (1,0) [0|0] "" Vector__XXX
 SG_ DAS_sw017_numTransportErrors m17 : 40|8@1+ (1,0) [0|0] "" Vector__XXX
 SG_ DAS_sw021_currentTemperature m21 : 40|8@1- (1,0) [0|0] "" Vector__XXX
 SG_ DAS_sw025_offsetSide m25 : 40|2@1+ (1,0) [0|0] "" Vector__XXX
 SG_ DAS_sw027_Unused_Byte m27 : 40|8@1+ (1,0) [0|0] "" Vector__XXX
 SG_ DAS_sw040_epas_internal_sas m40 : 40|8@1+ (1,-128) [0|0] "" Vector__XXX
 SG_ DAS_sw042_cam_SunRay m42 : 40|1@1+ (1,0) [0|0] "" Vector__XXX
 SG_ DAS_sw050_hostSpeed m50 : 40|8@1+ (1,0) [0|0] "" Vector__XXX
 SG_ DAS_sw051_unusedB0 m51 : 40|8@1+ (1,0) [0|0] "" Vector__XXX
 SG_ DAS_sw053_a34steerAngSpdValidity m53 : 40|1@1+ (1,0) [0|0] "" Vector__XXX
 SG_ DAS_sw054_unusedByte m54 : 40|8@1+ (1,0) [0|0] "" Vector__XXX
 SG_ DAS_sw060_hostSpeed m60 : 40|7@1+ (2,0) [0|0] "" Vector__XXX
 SG_ DAS_sw063_detectedMinorVer m63 : 40|8@1+ (1,0) [0|0] "" Vector__XXX
 SG_ DAS_sw068_navigationSTW m68 : 40|14@1+ (0.1,-819.2) [0|0] "" Vector__XXX
 SG_ DAS_sw070_currentSpeed m70 : 40|12@1+ (0.1,-204.7) [0|0] "" Vector__XXX
 SG_ DAS_sw071_roadClass m71 : 40|3@1+ (1,0) [0|0] "" Vector__XXX
 SG_ DAS_sw073_freespaceLeftC1 m73 : 40|8@1+ (0.0016,-0.2) [0|0] "" Vector__XXX
 SG_ DAS_sw074_ipsoRCS m74 : 40|8@1+ (1,0) [0|0] "" Vector__XXX
 SG_ DAS_sw076_hostSpeed m76 : 40|8@1+ (1,0) [0|0] "" Vector__XXX
 SG_ DAS_sw078_radarTarg5_VxRel m78 : 40|8@1+ (0.2,-25.6) [0|0] "" Vector__XXX
 SG_ DAS_sw080_road_class m80 : 40|3@1+ (1,0) [0|0] "" Vector__XXX
 SG_ DAS_sw081_cameraTTC m81 : 40|8@1+ (0.02,0) [0|0] "" Vector__XXX
 SG_ DAS_sw082_R_Lane m82 : 40|8@1+ (0.05,-6.4) [0|0] "" Vector__XXX
 SG_ DAS_sw084_ipsoDy m84 : 40|8@1+ (0.1,-12.6) [0|0] "" Vector__XXX
 SG_ DAS_sw086_ellipseOverlap m86 : 40|8@1+ (0.1,-12.5) [0|0] "" Vector__XXX
 SG_ DAS_sw103_objectDz m103 : 40|8@1+ (0.25,-5) [0|0] "" Vector__XXX
 SG_ DAS_sw141_temperature m141 : 40|8@1- (1,0) [0|0] "" Vector__XXX
 SG_ DAS_sw194_numPedstrian m194 : 40|4@1+ (1,0) [0|0] "" Vector__XXX
 SG_ DAS_sw195_vehicleSpeed m195 : 40|12@1+ (0.1,0) [0|0] "" Vector__XXX
 SG_ DAS_sw201_vehSpeed m201 : 40|8@1+ (1,0) [0|0] "" Vector__XXX
 SG_ DAS_sw202_vehicleSpeed m202 : 40|12@1+ (0.1,0) [0|0] "" Vector__XXX
 SG_ DAS_sw204_frRight m204 : 40|8@1+ (1,0) [0|0] "" Vector__XXX
 SG_ DAS_sw205_rrMiddle m205 : 40|8@1+ (1,0) [0|0] "" Vector__XXX
 SG_ DAS_sw227_ambientTemperature m227 : 40|8@1+ (0.5,-40) [0|0] "" Vector__XXX
 SG_ DAS_sw004_CamCommonMIA m4 : 41|1@1+ (1,0) [0|0] "" Vector__XXX
 SG_ DAS_sw005_speedDerivative m5 : 41|1@1+ (1,0) [0|0] "" Vector__XXX
 SG_ DAS_sw006_steeringAngle m6 : 41|1@1+ (1,0) [0|0] "" Vector__XXX
 SG_ DAS_sw042_cam_RoadSpray m42 : 41|1@1+ (1,0) [0|0] "" Vector__XXX
 SG_ DAS_sw053_a35indctrValidity m53 : 41|1@1+ (1,0) [0|0] "" Vector__XXX
 SG_ DAS_sw085_rightLaneExist m85 : 41|6@1+ (2,0) [0|0] "" Vector__XXX
 SG_ DAS_sw199_currentSpeed m199 : 41|8@1+ (0.1,-12.2) [0|0] "" Vector__XXX
 SG_ DAS_sw203_startDistance m203 : 41|11@1+ (1,0) [0|0] "" Vector__XXX
 SG_ DAS_sw004_CamObjectsMIA m4 : 42|1@1+ (1,0) [0|0] "" Vector__XXX
 SG_ DAS_sw005_camWatchdog m5 : 42|1@1+ (1,0) [0|0] "" Vector__XXX
 SG_ DAS_sw006_steeringAngleRate m6 : 42|1@1+ (1,0) [0|0] "" Vector__XXX
 SG_ DAS_sw012_mespFatalErrDetails m12 : 42|8@1+ (1,0) [0|0] "" Vector__XXX
 SG_ DAS_sw015_SunRay m15 : 42|2@1+ (1,0) [0|0] "" Vector__XXX
 SG_ DAS_sw042_cam_BlurredImage m42 : 42|1@1+ (1,0) [0|0] "" Vector__XXX
 SG_ DAS_sw053_a36vehStndStllValidty m53 : 42|1@1+ (1,0) [0|0] "" Vector__XXX
 SG_ DAS_sw062_unusedBits m62 : 42|6@1+ (1,0) [0|0] "" Vector__XXX
 SG_ DAS_sw069_roadClass m69 : 42|4@1+ (1,0) [0|0] "" Vector__XXX
 SG_ DAS_sw004_CamWatchdog m4 : 43|1@1+ (1,0) [0|0] "" Vector__XXX
 SG_ DAS_sw005_AutofixOutOfCalibHorzn m5 : 43|1@1+ (1,0) [0|0] "" Vector__XXX
 SG_ DAS_sw006_speed m6 : 43|1@1+ (1,0) [0|0] "" Vector__XXX
 SG_ DAS_sw026_uds_mean_utilization m26 : 43|7@1+ (1,0) [0|0] "" Vector__XXX
 SG_ DAS_sw042_cam_LowSun m42 : 43|1@1+ (1,0) [0|0] "" Vector__XXX
 SG_ DAS_sw053_a37vinValidity m53 : 43|1@1+ (1,0) [0|0] "" Vector__XXX
 SG_ DAS_sw071_driverPresent m71 : 43|1@1+ (1,0) [0|0] "" Vector__XXX
 SG_ DAS_sw080_ego_speed m80 : 43|5@1+ (1,0) [0|0] "" Vector__XXX
 SG_ DAS_sw004_RadarLowVisibility m4 : 44|1@1+ (1,0) [0|0] "" Vector__XXX
 SG_ DAS_sw005_RadarLowVisibility m5 : 44|1@1+ (1,0) [0|0] "" Vector__XXX
 SG_ DAS_sw006_gear m6 : 44|1@1+ (1,0) [0|0] "" Vector__XXX
 SG_ DAS_sw015_ImpairedVD m15 : 44|2@1+ (1,0) [0|0] "" Vector__XXX
 SG_ DAS_sw042_cam_SmearedSpots m42 : 44|1@1+ (1,0) [0|0] "" Vector__XXX
 SG_ DAS_sw053_a38whlRotValidity m53 : 44|1@1+ (1,0) [0|0] "" Vector__XXX
 SG_ DAS_sw067_vehSpeed m67 : 44|12@1+ (0.1,-50) [0|0] "" Vector__XXX
 SG_ DAS_sw071_airSuspension m71 : 44|3@1+ (1,0) [0|0] "" Vector__XXX
 SG_ DAS_sw194_reasonForHold m194 : 44|4@1+ (1,0) [0|0] "" Vector__XXX
 SG_ DAS_sw004_RadarMisalignment m4 : 45|1@1+ (1,0) [0|0] "" Vector__XXX
 SG_ DAS_sw006_stabilityControl m6 : 45|1@1+ (1,0) [0|0] "" Vector__XXX
 SG_ DAS_sw042_cam_PartialBlock m42 : 45|1@1+ (1,0) [0|0] "" Vector__XXX
 SG_ DAS_sw053_a39whlSpdValidity m53 : 45|1@1+ (1,0) [0|0] "" Vector__XXX
 SG_ DAS_sw231_targetRelAcceleration m231 : 45|8@1+ (0.1,-12.8) [0|0] "" Vector__XXX
 SG_ DAS_sw004_OutOfFocusImage m4 : 46|1@1+ (1,0) [0|0] "" Vector__XXX
 SG_ DAS_sw006_dasDisabled m6 : 46|1@1+ (1,0) [0|0] "" Vector__XXX
 SG_ DAS_sw010_unusedBits m10 : 46|2@1+ (1,0) [0|0] "" Vector__XXX
 SG_ DAS_sw015_SelfGlare m15 : 46|2@1+ (1,0) [0|0] "" Vector__XXX
 SG_ DAS_sw041_unusedW2 m41 : 46|18@1+ (1,0) [0|0] "" Vector__XXX
 SG_ DAS_sw042_cam_Autofix m42 : 46|1@1+ (1,0) [0|0] "" Vector__XXX
 SG_ DAS_sw053_a40whlStndStllValidty m53 : 46|1@1+ (1,0) [0|0] "" Vector__XXX
 SG_ DAS_sw069_drivingLaneLeft m69 : 46|8@1+ (1,0) [0|0] "" Vector__XXX
 SG_ DAS_sw004_ImpairedVD m4 : 47|1@1+ (1,0) [0|0] "" Vector__XXX
 SG_ DAS_sw006_speedDerivative m6 : 47|1@1+ (1,0) [0|0] "" Vector__XXX
 SG_ DAS_sw011_egoRightOfCenter m11 : 47|1@1+ (1,0) [0|0] "" Vector__XXX
 SG_ DAS_sw018_railControl m18 : 47|1@1+ (1,0) [0|0] "" Vector__XXX
 SG_ DAS_sw042_cam_AutofixHorizon m42 : 47|1@1+ (1,0) [0|0] "" Vector__XXX
 SG_ DAS_sw053_a41wiperValidity m53 : 47|1@1+ (1,0) [0|0] "" Vector__XXX
 SG_ DAS_sw060_hostLongAccel m60 : 47|4@1+ (1,-7.5) [0|0] "" Vector__XXX
 SG_ DAS_sw085_averageSpeedHist m85 : 47|6@1+ (0.25,0) [0|0] "" Vector__XXX
 SG_ DAS_sw004_SunRay m4 : 48|1@1+ (1,0) [0|0] "" Vector__XXX
 SG_ DAS_sw006_camWatchdog m6 : 48|1@1+ (1,0) [0|0] "" Vector__XXX
 SG_ DAS_sw010_VmaPlausibility m10 : 48|16@1+ (1.52587890625005e-05,0) [0|0] "" Vector__XXX
 SG_ DAS_sw011_egoMovingRight m11 : 48|1@1+ (1,0) [0|0] "" Vector__XXX
 SG_ DAS_sw013_highestSeqRecd m13 : 48|12@1+ (1,0) [0|0] "" Vector__XXX
 SG_ DAS_sw014_assertData m14 : 48|16@1+ (1,0) [0|0] "" Vector__XXX
 SG_ DAS_sw015_OutOfFocusImage m15 : 48|2@1+ (1,0) [0|0] "" Vector__XXX
 SG_ DAS_sw016_hostLongAccel m16 : 48|7@1+ (0.15625,-10) [0|0] "" Vector__XXX
 SG_ DAS_sw017_highestSeqRecd m17 : 48|12@1+ (1,0) [0|0] "" Vector__XXX
 SG_ DAS_sw018_currentVoltage m18 : 48|16@1+ (1,0) [0|0] "" Vector__XXX
 SG_ DAS_sw020_unusedW2 m20 : 48|16@1+ (1,0) [0|0] "" Vector__XXX
 SG_ DAS_sw021_unusedWord m21 : 48|16@1+ (1,0) [0|0] "" Vector__XXX
 SG_ DAS_sw025_torsionBarTorque m25 : 48|8@1+ (0.1,-12.8) [0|0] "" Vector__XXX
 SG_ DAS_sw027_ESR0 m27 : 48|1@1+ (1,0) [0|0] "" Vector__XXX
 SG_ DAS_sw028_multifrm_rx_len m28 : 48|16@1+ (1,0) [0|0] "" Vector__XXX
 SG_ DAS_sw029_unusedW1 m29 : 48|16@1+ (1,0) [0|0] "" Vector__XXX
 SG_ DAS_sw030_unusedW1 m30 : 48|16@1+ (1,0) [0|0] "" Vector__XXX
 SG_ DAS_sw031_errorData2 m31 : 48|16@1+ (1,0) [0|0] "" Vector__XXX
 SG_ DAS_sw032_errorData2 m32 : 48|16@1+ (1,0) [0|0] "" Vector__XXX
 SG_ DAS_sw033_unusedW1 m33 : 48|16@1+ (1,0) [0|0] "" Vector__XXX
 SG_ DAS_sw034_unusedW1 m34 : 48|16@1+ (1,0) [0|0] "" Vector__XXX
 SG_ DAS_sw035_unusedW1 m35 : 48|16@1+ (1,0) [0|0] "" Vector__XXX
 SG_ DAS_sw036_unusedW1 m36 : 48|16@1+ (1,0) [0|0] "" Vector__XXX
 SG_ DAS_sw037_unusedW1 m37 : 48|16@1+ (1,0) [0|0] "" Vector__XXX
 SG_ DAS_sw039_unusedW1 m39 : 48|16@1+ (1,0) [0|0] "" Vector__XXX
 SG_ DAS_sw040_torsion_bar_torque m40 : 48|8@1+ (0.1,-12.8) [0|0] "" Vector__XXX
 SG_ DAS_sw042_cam_AutofixYaw m42 : 48|1@1+ (1,0) [0|0] "" Vector__XXX
 SG_ DAS_sw043_camLongRunTime_unused m43 : 48|16@1+ (1,0) [0|0] "" Vector__XXX
 SG_ DAS_sw045_unusedW1 m45 : 48|16@1+ (1,0) [0|0] "" Vector__XXX
 SG_ DAS_sw047_edrStateMachine m47 : 48|8@1+ (1,0) [0|0] "" Vector__XXX
 SG_ DAS_sw049_ffs_version_msw m49 : 48|16@1+ (1,0) [0|0] "" Vector__XXX
 SG_ DAS_sw050_hostLongAccel m50 : 48|7@1+ (0.15625,-10) [0|0] "" Vector__XXX
 SG_ DAS_sw051_unusedW1 m51 : 48|16@1+ (1,0) [0|0] "" Vector__XXX
 SG_ DAS_sw053_a42xwdValidity m53 : 48|1@1+ (1,0) [0|0] "" Vector__XXX
 SG_ DAS_sw054_unusedW0 m54 : 48|16@1+ (1,0) [0|0] "" Vector__XXX
 SG_ DAS_sw055_expectedCrcLsw m55 : 48|16@1+ (1,0) [0|0] "" Vector__XXX
 SG_ DAS_sw056_unusedW1 m56 : 48|16@1+ (1,0) [0|0] "" Vector__XXX
 SG_ DAS_sw058_unusedW1 m58 : 48|16@1+ (1,0) [0|0] "" Vector__XXX
 SG_ DAS_sw059_unusedW1 m59 : 48|16@1+ (1,0) [0|0] "" Vector__XXX
 SG_ DAS_sw061_unusedW1 m61 : 48|16@1+ (1,0) [0|0] "" Vector__XXX
 SG_ DAS_sw062_VmaPlausibility m62 : 48|16@1+ (1.52587890625005e-05,0) [0|0] "" Vector__XXX
 SG_ DAS_sw063_expectedSubMinorVer m63 : 48|8@1+ (1,0) [0|0] "" Vector__XXX
 SG_ DAS_sw065_unusedW1 m65 : 48|16@1+ (1,0) [0|0] "" Vector__XXX
 SG_ DAS_sw066_unusedW1 m66 : 48|16@1+ (1,0) [0|0] "" Vector__XXX
 SG_ DAS_sw071_temperature m71 : 48|8@1+ (0.5,-40) [0|0] "" Vector__XXX
 SG_ DAS_sw072_endDistance m72 : 48|8@1+ (1,0) [0|0] "" Vector__XXX
 SG_ DAS_sw073_freespaceRightC1 m73 : 48|8@1+ (0.0016,-0.2) [0|0] "" Vector__XXX
 SG_ DAS_sw074_ipsoConfidence m74 : 48|6@1+ (2,0) [0|0] "" Vector__XXX
 SG_ DAS_sw075_unusedW1 m75 : 48|16@1+ (1,0) [0|0] "" Vector__XXX
 SG_ DAS_sw076_hostLongAccel m76 : 48|7@1+ (0.15625,-10) [0|0] "" Vector__XXX
 SG_ DAS_sw077_oocUntrackedTime m77 : 48|6@1+ (0.1,0) [0|0] "" Vector__XXX
 SG_ DAS_sw078_radarTarg1_dx m78 : 48|8@1+ (0.0625,0) [0|0] "" Vector__XXX
 SG_ DAS_sw080_cipv_valid m80 : 48|1@1+ (1,0) [0|0] "" Vector__XXX
 SG_ DAS_sw081_pedalPosition m81 : 48|7@1+ (1,0) [0|0] "" Vector__XXX
 SG_ DAS_sw082_road_class m82 : 48|3@1+ (1,0) [0|0] "" Vector__XXX
 SG_ DAS_sw083_Targ5_dz m83 : 48|6@1+ (0.25,-5) [0|0] "" Vector__XXX
 SG_ DAS_sw086_ellipseAge m86 : 48|3@1+ (1,0) [0|0] "" Vector__XXX
 SG_ DAS_sw103_distanceEllipse m103 : 48|8@1+ (0.5,0) [0|0] "" Vector__XXX
 SG_ DAS_sw194_timeInHold m194 : 48|16@1+ (1,0) [0|0] "" Vector__XXX
 SG_ DAS_sw201_viewRangeOAL m201 : 48|3@1+ (1,0) [0|0] "" Vector__XXX
 SG_ DAS_sw204_frRightMiddle m204 : 48|8@1+ (1,0) [0|0] "" Vector__XXX
 SG_ DAS_sw205_rrRight m205 : 48|8@1+ (1,0) [0|0] "" Vector__XXX
 SG_ DAS_sw004_Splashes m4 : 49|1@1+ (1,0) [0|0] "" Vector__XXX
 SG_ DAS_sw006_camObjHeader m6 : 49|1@1+ (1,0) [0|0] "" Vector__XXX
 SG_ DAS_sw011_egoLeftOfCenter m11 : 49|1@1+ (1,0) [0|0] "" Vector__XXX
 SG_ DAS_sw027_ESR1 m27 : 49|1@1+ (1,0) [0|0] "" Vector__XXX
 SG_ DAS_sw042_cam_FullBlock m42 : 49|1@1+ (1,0) [0|0] "" Vector__XXX
 SG_ DAS_sw053_a43yawOffValidity m53 : 49|1@1+ (1,0) [0|0] "" Vector__XXX
 SG_ DAS_sw080_min_speed_check m80 : 49|1@1+ (1,0) [0|0] "" Vector__XXX
 SG_ DAS_sw199_internalState m199 : 49|4@1+ (1,0) [0|0] "" Vector__XXX
 SG_ DAS_sw004_BlurredImage m4 : 50|1@1+ (1,0) [0|0] "" Vector__XXX
 SG_ DAS_sw006_camCommonMsg m6 : 50|1@1+ (1,0) [0|0] "" Vector__XXX
 SG_ DAS_sw011_egoMovingLeft m11 : 50|1@1+ (1,0) [0|0] "" Vector__XXX
 SG_ DAS_sw012_mespDDRTempStatus m12 : 50|3@1+ (1,0) [0|0] "" Vector__XXX
 SG_ DAS_sw015_MainCameraLowLight m15 : 50|2@1+ (1,0) [0|0] "" Vector__XXX
 SG_ DAS_sw026_mob_mean_utilization m26 : 50|7@1+ (1,0) [0|0] "" Vector__XXX
 SG_ DAS_sw027_SW m27 : 50|1@1+ (1,0) [0|0] "" Vector__XXX
 SG_ DAS_sw042_cam_SmearedHalos m42 : 50|1@1+ (1,0) [0|0] "" Vector__XXX
 SG_ DAS_sw053_a44yawValidity m53 : 50|1@1+ (1,0) [0|0] "" Vector__XXX
 SG_ DAS_sw080_cruise_lever_state m80 : 50|3@1+ (1,0) [0|0] "" Vector__XXX
 SG_ DAS_sw004_LowSun m4 : 51|1@1+ (1,0) [0|0] "" Vector__XXX
 SG_ DAS_sw006_camFcwPcwMsg m6 : 51|1@1+ (1,0) [0|0] "" Vector__XXX
 SG_ DAS_sw011_polyValid m11 : 51|1@1+ (1,0) [0|0] "" Vector__XXX
 SG_ DAS_sw027_STM0 m27 : 51|1@1+ (1,0) [0|0] "" Vector__XXX
 SG_ DAS_sw042_cam_FoggySpots m42 : 51|1@1+ (1,0) [0|0] "" Vector__XXX
 SG_ DAS_sw053_a48steerAngOffSanity m53 : 51|1@1+ (1,0) [0|0] "" Vector__XXX
 SG_ DAS_sw060_RadarAssociationAge m60 : 51|4@1+ (100,0) [0|0] "" Vector__XXX
 SG_ DAS_sw086_activeBraking m86 : 51|1@1+ (1,0) [0|0] "" Vector__XXX
 SG_ DAS_sw004_SmearedSpots m4 : 52|1@1+ (1,0) [0|0] "" Vector__XXX
 SG_ DAS_sw006_longAccel m6 : 52|1@1+ (1,0) [0|0] "" Vector__XXX
 SG_ DAS_sw011_egoCentered m11 : 52|1@1+ (1,0) [0|0] "" Vector__XXX
 SG_ DAS_sw015_NarrowCameraLowLight m15 : 52|2@1+ (1,0) [0|0] "" Vector__XXX
 SG_ DAS_sw027_STM1 m27 : 52|1@1+ (1,0) [0|0] "" Vector__XXX
 SG_ DAS_sw042_cam_SelfGlare m42 : 52|1@1+ (1,0) [0|0] "" Vector__XXX
 SG_ DAS_sw053_a49tireSizeSanity m53 : 52|1@1+ (1,0) [0|0] "" Vector__XXX
 SG_ DAS_sw086_cipvValid m86 : 52|1@1+ (1,0) [0|0] "" Vector__XXX
 SG_ DAS_sw203_vehicleSkew m203 : 52|12@1+ (0.002,0) [0|0] "" Vector__XXX
 SG_ DAS_sw004_PartialBlockage m4 : 53|1@1+ (1,0) [0|0] "" Vector__XXX
 SG_ DAS_sw006_yawRate m6 : 53|1@1+ (1,0) [0|0] "" Vector__XXX
 SG_ DAS_sw011_scaReasonEldw m11 : 53|1@1+ (1,0) [0|0] "" Vector__XXX
 SG_ DAS_sw012_freescaleTemp m12 : 53|8@1- (1,0) [0|0] "" Vector__XXX
 SG_ DAS_sw027_STM2 m27 : 53|1@1+ (1,0) [0|0] "" Vector__XXX
 SG_ DAS_sw042_cam_OutofFocus m42 : 53|1@1+ (1,0) [0|0] "" Vector__XXX
 SG_ DAS_sw053_a50velocitySanity m53 : 53|1@1+ (1,0) [0|0] "" Vector__XXX
 SG_ DAS_sw080_cruise_speed_check m80 : 53|1@1+ (1,0) [0|0] "" Vector__XXX
 SG_ DAS_sw085_freeSpaceC0Left m85 : 53|5@1+ (1,-15) [0|0] "" Vector__XXX
 SG_ DAS_sw086_mcvlValid m86 : 53|1@1+ (1,0) [0|0] "" Vector__XXX
 SG_ DAS_sw199_maxSpeed m199 : 53|7@1+ (0.2,-12.2) [0|0] "" Vector__XXX
 SG_ DAS_sw231_targetIsACar m231 : 53|1@1+ (1,0) [0|0] "" Vector__XXX
 SG_ DAS_sw004_AutofixOutOfCalib m4 : 54|1@1+ (1,0) [0|0] "" Vector__XXX
 SG_ DAS_sw006_DIaebState_SNA m6 : 54|1@1+ (1,0) [0|0] "" Vector__XXX
 SG_ DAS_sw015_MainCameraBadAssoc m15 : 54|2@1+ (1,0) [0|0] "" Vector__XXX
 SG_ DAS_sw027_CBS_SYSTEM m27 : 54|1@1+ (1,0) [0|0] "" Vector__XXX
 SG_ DAS_sw042_road_match m42 : 54|1@1+ (1,0) [0|0] "" Vector__XXX
 SG_ DAS_sw053_a51yawSanity m53 : 54|1@1+ (1,0) [0|0] "" Vector__XXX
 SG_ DAS_sw069_drivingLaneRight m69 : 54|8@1+ (1,0) [0|0] "" Vector__XXX
 SG_ DAS_sw074_ipsowExist m74 : 54|5@1+ (1,0) [0|0] "" Vector__XXX
 SG_ DAS_sw077_oocOffCourseDist_cm m77 : 54|10@1- (1,0) [0|0] "" Vector__XXX
 SG_ DAS_sw083_Targ5_wObj m83 : 54|5@1+ (0.03125,0) [0|0] "" Vector__XXX
 SG_ DAS_sw086_mcvrValid m86 : 54|1@1+ (1,0) [0|0] "" Vector__XXX
 SG_ DAS_sw231_egoVehicleSpeed m231 : 54|5@1+ (5,0) [0|0] "" Vector__XXX
 SG_ DAS_sw004_AutofixOutOfCalibHorzn m4 : 55|1@1+ (1,0) [0|0] "" Vector__XXX
 SG_ DAS_sw006_DIaebStateUnavailable m6 : 55|1@1+ (1,0) [0|0] "" Vector__XXX
 SG_ DAS_sw016_driverPressedAccelPed m16 : 55|1@1+ (1,0) [0|0] "" Vector__XXX
 SG_ DAS_sw027_CBS_DEBUG m27 : 55|1@1+ (1,0) [0|0] "" Vector__XXX
 SG_ DAS_sw042_controlled_access m42 : 55|1@1+ (1,0) [0|0] "" Vector__XXX
 SG_ DAS_sw050_driverPressedAccelPed m50 : 55|1@1+ (1,0) [0|0] "" Vector__XXX
 SG_ DAS_sw053_a53espmodValidity m53 : 55|1@1+ (1,0) [0|0] "" Vector__XXX
 SG_ DAS_sw060_driverPressedBrakePed m60 : 55|1@1+ (1,0) [0|0] "" Vector__XXX
 SG_ DAS_sw076_driverPressedAccelPed m76 : 55|1@1+ (1,0) [0|0] "" Vector__XXX
 SG_ DAS_sw004_AutofixOutOfCalibYaw m4 : 56|1@1+ (1,0) [0|0] "" Vector__XXX
 SG_ DAS_sw006_brakeLights m6 : 56|1@1+ (1,0) [0|0] "" Vector__XXX
 SG_ DAS_sw011_laneWidth m11 : 56|8@1+ (0.025,0) [0|0] "" Vector__XXX
 SG_ DAS_sw015_NarrowCameraBadAssoc m15 : 56|2@1+ (1,0) [0|0] "" Vector__XXX
 SG_ DAS_sw016_driverPressedBrakePed m16 : 56|1@1+ (1,0) [0|0] "" Vector__XXX
 SG_ DAS_sw027_CBS_APP m27 : 56|1@1+ (1,0) [0|0] "" Vector__XXX
 SG_ DAS_sw040_view_range m40 : 56|8@1+ (1,0) [0|0] "" Vector__XXX
 SG_ DAS_sw042_road_class m42 : 56|3@1+ (1,0) [0|0] "" Vector__XXX
 SG_ DAS_sw047_edrLoggerBuffer m47 : 56|2@1+ (1,0) [0|0] "" Vector__XXX
 SG_ DAS_sw050_driverPressedBrakePed m50 : 56|1@1+ (1,0) [0|0] "" Vector__XXX
 SG_ DAS_sw053_a54gtwmodValidity m53 : 56|1@1+ (1,0) [0|0] "" Vector__XXX
 SG_ DAS_sw060_overrideAccelPed m60 : 56|1@1+ (1,0) [0|0] "" Vector__XXX
 SG_ DAS_sw063_detectedSubMinorVer m63 : 56|8@1+ (1,0) [0|0] "" Vector__XXX
 SG_ DAS_sw067_offsetEstimator m67 : 56|8@1+ (0.1,-12.8) [0|0] "" Vector__XXX
 SG_ DAS_sw071_activationType m71 : 56|2@1+ (1,0) [0|0] "" Vector__XXX
 SG_ DAS_sw072_guidanceComplete m72 : 56|1@1+ (1,0) [0|0] "" Vector__XXX
 SG_ DAS_sw073_freespaceLeftFarZ m73 : 56|4@1+ (4,0) [0|0] "" Vector__XXX
 SG_ DAS_sw076_driverPressedBrakePed m76 : 56|1@1+ (1,0) [0|0] "" Vector__XXX
 SG_ DAS_sw078_radarTarg1_VxRel m78 : 56|8@1+ (0.2,-25.6) [0|0] "" Vector__XXX
 SG_ DAS_sw086_roadClass m86 : 56|3@1+ (1,0) [0|0] "" Vector__XXX
 SG_ DAS_sw103_ipsoApproved m103 : 56|1@1+ (1,0) [0|0] "" Vector__XXX
 SG_ DAS_sw204_maxSpeed m204 : 56|8@1+ (0.1,-12.2) [0|0] "" Vector__XXX
 SG_ DAS_sw205_rrRightMiddle m205 : 56|8@1+ (1,0) [0|0] "" Vector__XXX
 SG_ DAS_sw004_FullBlockage m4 : 57|1@1+ (1,0) [0|0] "" Vector__XXX
 SG_ DAS_sw006_trailerMode m6 : 57|1@1+ (1,0) [0|0] "" Vector__XXX
 SG_ DAS_sw016_overrideAccelPed m16 : 57|1@1+ (1,0) [0|0] "" Vector__XXX
 SG_ DAS_sw026_veh_mean_utilization m26 : 57|7@1+ (1,0) [0|0] "" Vector__XXX
 SG_ DAS_sw027_EVR13 m27 : 57|1@1+ (1,0) [0|0] "" Vector__XXX
 SG_ DAS_sw050_aebEnable m50 : 57|1@1+ (1,0) [0|0] "" Vector__XXX
 SG_ DAS_sw053_a55stwmodValidity m53 : 57|1@1+ (1,0) [0|0] "" Vector__XXX
 SG_ DAS_sw060_overrideBlinker m60 : 57|1@1+ (1,0) [0|0] "" Vector__XXX
 SG_ DAS_sw072_guidanceRunaway m72 : 57|1@1+ (1,0) [0|0] "" Vector__XXX
 SG_ DAS_sw076_overrideAccelPed m76 : 57|1@1+ (1,0) [0|0] "" Vector__XXX
 SG_ DAS_sw103_constArea m103 : 57|2@1+ (1,0) [0|0] "" Vector__XXX
 SG_ DAS_sw004_SmearedHalos m4 : 58|1@1+ (1,0) [0|0] "" Vector__XXX
 SG_ DAS_sw006_timeOfDay m6 : 58|2@1+ (1,0) [0|0] "" Vector__XXX
 SG_ DAS_sw016_overrideBlinker m16 : 58|1@1+ (1,0) [0|0] "" Vector__XXX
 SG_ DAS_sw027_EVR33 m27 : 58|1@1+ (1,0) [0|0] "" Vector__XXX
 SG_ DAS_sw047_unused m47 : 58|6@1+ (1,0) [0|0] "" Vector__XXX
 SG_ DAS_sw050_overrideBlinker m50 : 58|1@1+ (1,0) [0|0] "" Vector__XXX
 SG_ DAS_sw053_a56bcmodValidity m53 : 58|1@1+ (1,0) [0|0] "" Vector__XXX
 SG_ DAS_sw060_overrideBrake m60 : 58|1@1+ (1,0) [0|0] "" Vector__XXX
 SG_ DAS_sw072_guidanceTimer m72 : 58|1@1+ (1,0) [0|0] "" Vector__XXX
 SG_ DAS_sw076_overrideBlinker m76 : 58|1@1+ (1,0) [0|0] "" Vector__XXX
 SG_ DAS_sw085_freeSpaceC0Right m85 : 58|5@1+ (1,-15) [0|0] "" Vector__XXX
 SG_ DAS_sw004_FoggyLights m4 : 59|1@1+ (1,0) [0|0] "" Vector__XXX
 SG_ DAS_sw016_overrideBrake m16 : 59|1@1+ (1,0) [0|0] "" Vector__XXX
 SG_ DAS_sw027_SWD m27 : 59|1@1+ (1,0) [0|0] "" Vector__XXX
 SG_ DAS_sw050_overrideBrake m50 : 59|1@1+ (1,0) [0|0] "" Vector__XXX
 SG_ DAS_sw053_a57dimodValidity m53 : 59|1@1+ (1,0) [0|0] "" Vector__XXX
 SG_ DAS_sw060_overrideSteer m60 : 59|1@1+ (1,0) [0|0] "" Vector__XXX
 SG_ DAS_sw072_handlePress m72 : 59|1@1+ (1,0) [0|0] "" Vector__XXX
 SG_ DAS_sw074_roadClass m74 : 59|3@1+ (1,0) [0|0] "" Vector__XXX
 SG_ DAS_sw076_overrideBrake m76 : 59|1@1+ (1,0) [0|0] "" Vector__XXX
 SG_ DAS_sw083_Targ5_wNonObj m83 : 59|5@1+ (0.03125,0) [0|0] "" Vector__XXX
 SG_ DAS_sw086_ipsoApproved m86 : 59|1@1+ (1,0) [0|0] "" Vector__XXX
 SG_ DAS_sw103_radAlignment m103 : 59|5@1+ (0.015625,-0.2343) [0|0] "" Vector__XXX
 SG_ DAS_sw231_steeringOverride m231 : 59|1@1+ (1,0) [0|0] "" Vector__XXX
 SG_ DAS_sw004_SelfGlare m4 : 60|1@1+ (1,0) [0|0] "" Vector__XXX
 SG_ DAS_sw013_numTransportErrors m13 : 60|4@1+ (1,0) [0|0] "" Vector__XXX
 SG_ DAS_sw016_overrideSteer m16 : 60|1@1+ (1,0) [0|0] "" Vector__XXX
 SG_ DAS_sw017_Any_Tsr_Msg_Recd m17 : 60|1@1+ (1,0) [0|0] "" Vector__XXX
 SG_ DAS_sw027_STDBY_WDG m27 : 60|1@1+ (1,0) [0|0] "" Vector__XXX
 SG_ DAS_sw050_overrideSteer m50 : 60|1@1+ (1,0) [0|0] "" Vector__XXX
 SG_ DAS_sw053_a59drmiInvalidChkSm m53 : 60|1@1+ (1,0) [0|0] "" Vector__XXX
 SG_ DAS_sw060_collisionWarningSource m60 : 60|3@1+ (1,0) [0|0] "" Vector__XXX
 SG_ DAS_sw072_keyfobPress m72 : 60|1@1+ (1,0) [0|0] "" Vector__XXX
 SG_ DAS_sw073_freespaceRightFarZ m73 : 60|4@1+ (4,0) [0|0] "" Vector__XXX
 SG_ DAS_sw076_overrideSteer m76 : 60|1@1+ (1,0) [0|0] "" Vector__XXX
 SG_ DAS_sw086_controlledAccess m86 : 60|1@1+ (1,0) [0|0] "" Vector__XXX
 SG_ DAS_sw199_numShifts m199 : 60|4@1+ (1,0) [0|0] "" Vector__XXX
 SG_ DAS_sw231_predOverlap m231 : 60|4@1+ (10,0) [0|0] "" Vector__XXX
 SG_ DAS_sw004_visionNotRunning m4 : 61|1@1+ (1,0) [0|0] "" Vector__XXX
 SG_ DAS_sw016_fcmModeAtEvent m16 : 61|2@1+ (1,0) [0|0] "" Vector__XXX
 SG_ DAS_sw017_Any_Hlb_Msg_Recd m17 : 61|1@1+ (1,0) [0|0] "" Vector__XXX
 SG_ DAS_sw027_PORST m27 : 61|1@1+ (1,0) [0|0] "" Vector__XXX
 SG_ DAS_sw050_fcmModeAtEvent m50 : 61|2@1+ (1,0) [0|0] "" Vector__XXX
 SG_ DAS_sw053_a60drmiInvalidCount m53 : 61|1@1+ (1,0) [0|0] "" Vector__XXX
 SG_ DAS_sw072_garageOpened m72 : 61|1@1+ (1,0) [0|0] "" Vector__XXX
 SG_ DAS_sw076_fcmModeAtEvent m76 : 61|2@1+ (1,0) [0|0] "" Vector__XXX
 SG_ DAS_sw086_driverHandsOn m86 : 61|1@1+ (1,0) [0|0] "" Vector__XXX
 SG_ DAS_sw017_Any_Common_Msg_Recd m17 : 62|1@1+ (1,0) [0|0] "" Vector__XXX
 SG_ DAS_sw027_Unused_word m27 : 62|2@1+ (1,0) [0|0] "" Vector__XXX
 SG_ DAS_sw053_a61radPositionMismatch m53 : 62|1@1+ (1,0) [0|0] "" Vector__XXX
 SG_ DAS_sw072_userTimeout m72 : 62|1@1+ (1,0) [0|0] "" Vector__XXX
 SG_ DAS_sw074_cruiseActive m74 : 62|1@1+ (1,0) [0|0] "" Vector__XXX
 SG_ DAS_sw016_accActive m16 : 63|1@1+ (1,0) [0|0] "" Vector__XXX
 SG_ DAS_sw017_Any_FCW_PCW_Msg_Recd m17 : 63|1@1+ (1,0) [0|0] "" Vector__XXX
 SG_ DAS_sw050_accActive m50 : 63|1@1+ (1,0) [0|0] "" Vector__XXX
 SG_ DAS_sw053_a62strRackMismatch m53 : 63|1@1+ (1,0) [0|0] "" Vector__XXX
 SG_ DAS_sw060_accActive m60 : 63|1@1+ (1,0) [0|0] "" Vector__XXX
 SG_ DAS_sw074_autopilotActive m74 : 63|1@1+ (1,0) [0|0] "" Vector__XXX
 SG_ DAS_sw076_accActive m76 : 63|1@1+ (1,0) [0|0] "" Vector__XXX

VAL_ 1332 VCFRONT_a117_VEH_status 0 "DISABLED" 1 "ENABLED" 2 "TEMPORARY_FAILURE" 3 "SNA" ;
VAL_ 1332 VCFRONT_a180_serviceMode 0 "DISABLED" 1 "ENABLED" ;
VAL_ 1332 VCFRONT_a192_serviceMode 0 "DISABLED" 1 "ENABLED" ;
VAL_ 1332 VCFRONT_a365_showroomMode 0 "DISABLED" 1 "ENABLED" ;
VAL_ 1332 VCFRONT_a514_cell4Voltage 65535 "SNA" ;
VAL_ 1332 VCFRONT_a515_cell4Voltage 65535 "SNA" ;
VAL_ 1332 VCFRONT_a669_vehicleSpeed 8191 "SNA" ;
VAL_ 1332 VCFRONT_a180_transportMode 0 "DISABLED" 1 "ENABLED" ;
VAL_ 1332 VCFRONT_a415_IBSVoltage 4095 "SNA" ;
VAL_ 1332 VCFRONT_a476_ECPAState 0 "OPEN" 1 "CLOSED" 2 "INVALID" 3 "SNA" ;
VAL_ 1332 VCFRONT_a595_IBSVoltage 4095 "SNA" ;
VAL_ 1332 VCFRONT_a104_BDY_status 0 "DISABLED" 1 "ENABLED" 2 "TEMPORARY_FAILURE" 3 "SNA" ;
VAL_ 1332 VCFRONT_a462_serviceMode 0 "DISABLED" 1 "ENABLED" ;
VAL_ 1332 VCFRONT_a561_cell2Voltage 65535 "SNA" ;
VAL_ 1332 VCFRONT_a562_cell2Voltage 65535 "SNA" ;
VAL_ 1332 VCFRONT_a220_serviceMode 0 "DISABLED" 1 "ENABLED" ;
VAL_ 1332 VCFRONT_a260_vehiclePowerState 0 "OFF" 1 "CONDITIONING" 2 "ACCESSORY" 3 "DRIVE" ;
VAL_ 1332 VCFRONT_a359_vehiclePowerState 0 "OFF" 1 "CONDITIONING" 2 "ACCESSORY" 3 "DRIVE" ;
VAL_ 1332 VCFRONT_a389_latchStatus 0 "SNA" 1 "OPENED" 2 "CLOSED" 3 "CLOSING" 4 "OPENING" 5 "AJAR" 6 "TIMEOUT" 7 "DEFAULT" 8 "FAULT" ;
VAL_ 1332 VCFRONT_a472_headlampTemperature_C 31 "SNA" ;
VAL_ 1332 VCFRONT_a473_headlampTemperature_C 31 "SNA" ;
VAL_ 1332 VCFRONT_a509_ambientTemp 4294966273 "SNA" ;
VAL_ 1332 VCFRONT_a510_serviceMode 0 "DISABLED" 1 "ENABLED" ;
VAL_ 1332 VCFRONT_a512_sumCellVoltage 65534 "INVALID" 65535 "SNA" ;
VAL_ 1332 VCFRONT_a513_packVoltage 65535 "SNA" ;
VAL_ 1332 VCFRONT_a521_ambientTemp 4294966273 "SNA" ;
VAL_ 1332 VCFRONT_a559_batterySMState 0 "INIT" 1 "CHARGE" 2 "DISCHARGE" 3 "STANDBY" 4 "RESISTANCE_ESTIMATION" 5 "OTA_STANDBY" 6 "DISCONNECTED_BATTERY_TEST" 7 "SHORTED_CELL_TEST" 8 "FAULT" 9 "RECOVERY" ;
VAL_ 1332 VCFRONT_a370_serviceMode 0 "DISABLED" 1 "ENABLED" ;
VAL_ 1332 VCFRONT_a260_batterySMState 0 "INIT" 1 "CHARGE" 2 "DISCHARGE" 3 "STANDBY" 4 "RESISTANCE_ESTIMATION" 5 "OTA_STANDBY" 6 "DISCONNECTED_BATTERY_TEST" 7 "SHORTED_CELL_TEST" 8 "FAULT" 9 "RECOVERY" ;
VAL_ 1332 VCFRONT_a359_batterySMState 0 "INIT" 1 "CHARGE" 2 "DISCHARGE" 3 "STANDBY" 4 "RESISTANCE_ESTIMATION" 5 "OTA_STANDBY" 6 "DISCONNECTED_BATTERY_TEST" 7 "SHORTED_CELL_TEST" 8 "FAULT" 9 "RECOVERY" ;
VAL_ 1332 VCFRONT_a370_sleepCurrent 4095 "SNA" ;
VAL_ 1332 VCFRONT_a414_IBSVoltage 4095 "SNA" ;
VAL_ 1332 VCFRONT_a477_cell4Voltage 65535 "SNA" ;
VAL_ 1332 VCFRONT_a627_cell4Voltage 65535 "SNA" ;
VAL_ 1332 VCFRONT_a191_ECPAState 0 "OPEN" 1 "CLOSED" 2 "INVALID" 3 "SNA" ;
VAL_ 1332 VCFRONT_a514_packVoltage 65535 "SNA" ;
VAL_ 1332 VCFRONT_a515_packVoltage 65535 "SNA" ;
VAL_ 1332 VCFRONT_a548_serviceMode 0 "DISABLED" 1 "ENABLED" ;
VAL_ 1332 VCFRONT_a527_cell4Voltage 65535 "SNA" ;
VAL_ 1332 VCFRONT_a555_cell4Voltage 65535 "SNA" ;
VAL_ 1332 VCFRONT_a561_cell3Voltage 65535 "SNA" ;
VAL_ 1332 VCFRONT_a562_cell3Voltage 65535 "SNA" ;
VAL_ 1332 VCFRONT_a171_serviceMode 0 "DISABLED" 1 "ENABLED" ;
VAL_ 1332 VCFRONT_a180_IBSVoltage 4095 "SNA" ;
VAL_ 1332 VCFRONT_a191_serviceMode 0 "DISABLED" 1 "ENABLED" ;
VAL_ 1332 VCFRONT_a359_hvState 0 "DOWN" 1 "COMING_UP" 2 "GOING_DOWN" 3 "UP_FOR_DRIVE" 4 "UP_FOR_CHARGE" 5 "UP_FOR_DC_CHARGE" 6 "UP" ;
VAL_ 1332 VCFRONT_a509_serviceMode 0 "DISABLED" 1 "ENABLED" ;
VAL_ 1332 VCFRONT_a511_hvState 0 "DOWN" 1 "COMING_UP" 2 "GOING_DOWN" 3 "UP_FOR_DRIVE" 4 "UP_FOR_CHARGE" 5 "UP_FOR_DC_CHARGE" 6 "UP" ;
VAL_ 1332 VCFRONT_a521_serviceMode 0 "DISABLED" 1 "ENABLED" ;
VAL_ 1332 VCFRONT_a191_vehicleLoadShedStage 0 "IDLE_OR_UNDEFINED" 1 "1" 2 "2" 3 "3" ;
VAL_ 1332 VCFRONT_a512_serviceMode 0 "DISABLED" 1 "ENABLED" ;
VAL_ 1332 VCFRONT_a559_factoryMode 0 "DISABLED" 1 "ENABLED" ;
VAL_ 1332 VCFRONT_a559_serviceMode 0 "DISABLED" 1 "ENABLED" ;
VAL_ 1332 VCFRONT_a370_SOC 127 "SNA" ;
VAL_ 1332 VCFRONT_a407_IBSTemperature 32767 "IBS_TEMPERATURE_SNA" ;
VAL_ 1332 VCFRONT_a477_sumCellVoltage 65534 "INVALID" 65535 "SNA" ;
VAL_ 1332 VCFRONT_a512_vehiclePowerState 0 "OFF" 1 "CONDITIONING" 2 "ACCESSORY" 3 "DRIVE" ;
VAL_ 1332 VCFRONT_a559_transportMode 0 "DISABLED" 1 "ENABLED" ;
VAL_ 1332 VCFRONT_a600_version 254 "LOCAL_BUILD" 255 "SNA" ;
VAL_ 1332 VCFRONT_a626_IBSTemperature 32767 "IBS_TEMPERATURE_SNA" ;
VAL_ 1332 VCFRONT_a627_sumCellVoltage 65534 "INVALID" 65535 "SNA" ;
VAL_ 1332 VCFRONT_a406_IBSTemperature 32767 "IBS_TEMPERATURE_SNA" ;
VAL_ 1332 VCFRONT_a561_cell4Voltage 65535 "SNA" ;
VAL_ 1332 VCFRONT_a562_cell4Voltage 65535 "SNA" ;
VAL_ 1332 VCFRONT_a197_serviceMode 0 "DISABLED" 1 "ENABLED" ;
VAL_ 1332 VCFRONT_a415_vehiclePowerState 0 "OFF" 1 "CONDITIONING" 2 "ACCESSORY" 3 "DRIVE" ;
VAL_ 1332 VCFRONT_a260_serviceMode 0 "DISABLED" 1 "ENABLED" ;
VAL_ 1332 VCFRONT_a359_serviceMode 0 "DISABLED" 1 "ENABLED" ;
VAL_ 1332 VCFRONT_a511_serviceMode 0 "DISABLED" 1 "ENABLED" ;
VAL_ 1332 VCFRONT_a196_ECPAState 0 "OPEN" 1 "CLOSED" 2 "INVALID" 3 "SNA" ;
VAL_ 1332 VCFRONT_a242_vehiclePowerState 0 "OFF" 1 "CONDITIONING" 2 "ACCESSORY" 3 "DRIVE" ;
VAL_ 1332 VCFRONT_a269_vehiclePowerState 0 "OFF" 1 "CONDITIONING" 2 "ACCESSORY" 3 "DRIVE" ;
VAL_ 1332 VCFRONT_a527_serviceMode 0 "DISABLED" 1 "ENABLED" ;
VAL_ 1332 VCFRONT_a541_SOC 127 "SNA" ;
VAL_ 1332 VCFRONT_a253_serviceMode 0 "DISABLED" 1 "ENABLED" ;
VAL_ 1332 VCFRONT_a623_factoryMode 0 "DISABLED" 1 "ENABLED" ;
VAL_ 1332 VCFRONT_a047_SingleCoreM4_M7_0 0 "0" 1 "1" 2 "2" 3 "3" 4 "4" 5 "5" 6 "6" 7 "7" 8 "8" 9 "9" 10 "10" 11 "11" 12 "12" 13 "13" 14 "14" 15 "15" 16 "16" 17 "17" 18 "18" 19 "19" 20 "20" 21 "21" 22 "22" 23 "23" 24 "24" 25 "25" 26 "26" 27 "27" 28 "28" 29 "29" 30 "30" 31 "31" ;
VAL_ 1332 VCFRONT_a513_serviceMode 0 "DISABLED" 1 "ENABLED" ;
VAL_ 1332 VCFRONT_a623_serviceMode 0 "DISABLED" 1 "ENABLED" ;
VAL_ 1332 VCFRONT_a518_serviceMode 0 "DISABLED" 1 "ENABLED" ;
VAL_ 1332 VCFRONT_a513_vehiclePowerState 0 "OFF" 1 "CONDITIONING" 2 "ACCESSORY" 3 "DRIVE" ;
VAL_ 1332 VCFRONT_a514_serviceMode 0 "DISABLED" 1 "ENABLED" ;
VAL_ 1332 VCFRONT_a515_serviceMode 0 "DISABLED" 1 "ENABLED" ;
VAL_ 1332 VCFRONT_a561_factoryMode 0 "DISABLED" 1 "ENABLED" ;
VAL_ 1332 VCFRONT_a562_factoryMode 0 "DISABLED" 1 "ENABLED" ;
VAL_ 1332 VCFRONT_a477_serviceMode 0 "DISABLED" 1 "ENABLED" ;
VAL_ 1332 VCFRONT_a518_vehiclePowerState 0 "OFF" 1 "CONDITIONING" 2 "ACCESSORY" 3 "DRIVE" ;
VAL_ 1332 VCFRONT_a561_serviceMode 0 "DISABLED" 1 "ENABLED" ;
VAL_ 1332 VCFRONT_a562_serviceMode 0 "DISABLED" 1 "ENABLED" ;
VAL_ 1332 VCFRONT_a627_serviceMode 0 "DISABLED" 1 "ENABLED" ;
VAL_ 1332 VCFRONT_a412_serviceMode 0 "DISABLED" 1 "ENABLED" ;
VAL_ 1332 VCFRONT_a414_vehiclePowerState 0 "OFF" 1 "CONDITIONING" 2 "ACCESSORY" 3 "DRIVE" ;
VAL_ 1332 VCFRONT_a514_vehiclePowerState 0 "OFF" 1 "CONDITIONING" 2 "ACCESSORY" 3 "DRIVE" ;
VAL_ 1332 VCFRONT_a515_vehiclePowerState 0 "OFF" 1 "CONDITIONING" 2 "ACCESSORY" 3 "DRIVE" ;
VAL_ 1332 VCFRONT_a172_serviceMode 0 "DISABLED" 1 "ENABLED" ;
VAL_ 1332 VCFRONT_a173_serviceMode 0 "DISABLED" 1 "ENABLED" ;
VAL_ 1337 DAS_infoIndex 0 "DEPRECATED_0" 1 "DEPRECATED_1" 2 "DEPRECATED_2" 3 "DEPRECATED_3" 4 "DEPRECATED_4" 5 "DEPRECATED_5" 6 "DEPRECATED_6" 7 "DEPRECATED_7" 8 "DEPRECATED_8" 9 "DEPRECATED_9" 10 "BUILD_HWID_COMPONENTID" 11 "PCBAID_ASSYID_USAGEID" 13 "APP_CRC" 14 "BOOTLOADER_SVN" 15 "BOOTLOADER_CRC" 16 "EYEQ_BOOT" 17 "APP_GITHASH" 18 "BOOTLOADER_GITHASH" 19 "VERSION_DEPRECATED" 20 "UDS_PROTOCOL_BOOTCRC" 23 "EYEQ_APP" 24 "EYEQ_FFS" 255 "END" ;
VAL_ 1337 DAS_infoBuildType 0 "UNKNOWN_BUILD" 1 "PLATFORM_BUILD" 2 "LOCAL_BUILD" 3 "TRACEABLE_CI_BUILD" 4 "MFG_BUILD" ;
VAL_ 1337 DAS_infoMajorVersion 254 "LOCAL_BUILD" 255 "SNA" ;
VAL_ 1337 DAS_infoBranchOrigin 254 "LOCAL_BUILD" 255 "SNA" ;
VAL_ 1337 DAS_infoMaturity 254 "LOCAL_BUILD" 255 "SNA" ;
VAL_ 1337 DAS_infoHardwareRevision 252 "CONFIGURABLE_HWID_PLACEHOLDER" ;
VAL_ 1352 APB_infoIndex 0 "DEPRECATED_0" 1 "DEPRECATED_1" 2 "DEPRECATED_2" 3 "DEPRECATED_3" 4 "DEPRECATED_4" 5 "DEPRECATED_5" 6 "DEPRECATED_6" 7 "DEPRECATED_7" 8 "DEPRECATED_8" 9 "DEPRECATED_9" 10 "BUILD_HWID_COMPONENTID" 11 "PCBAID_ASSYID_USAGEID" 13 "APP_CRC" 14 "BOOTLOADER_SVN" 15 "BOOTLOADER_CRC" 16 "SUBCOMPONENT" 17 "APP_GITHASH" 18 "BOOTLOADER_GITHASH" 19 "VERSION_DEPRECATED" 20 "UDS_PROTOCOL_BOOTCRC" 22 "VARIANTCRC" 25 "PACKAGE_PN_1_7" 26 "PACKAGE_PN_8_14" 27 "PACKAGE_PN_15_20" 29 "PACKAGE_SN_1_7" 30 "PACKAGE_SN_8_14" 31 "SUBCOMPONENT_GITHASH" 255 "END" ;
VAL_ 1352 APB_buildType 0 "UNKNOWN_BUILD" 1 "PLATFORM_BUILD" 2 "LOCAL_BUILD" 3 "TRACEABLE_CI_BUILD" 4 "MFG_BUILD" ;
VAL_ 1353 APP_infoIndex 0 "AP_BUILD_TYPE" 1 "FW_GITHASH" 2 "AP_GITHASH" ;
VAL_ 1353 APP_buildType 0 "SIGNED" 1 "LOCAL" 3 "REPO" ;
VAL_ 1365 RADC_alertID 0 "ALERT_DO_NOT_USE_ZERO" 1 "a001_DriverDoorOpen" 2 "a002_DoorOpen" 3 "a003_TrunkOpen" 4 "a004_FrunkOpen" 5 "a005_HeadlightsOnDoorOpen" 6 "a006_RemoteServiceAlert" 7 "a007_SoftPackConfigMismatch" 8 "a008_TouchScreenError" 9 "a009_SquashfsError" 10 "a010_MapsMissing" 11 "a011_IncorrectMap" 12 "a012_NotOnPrivateProperty" 13 "a013_TPMSHardWarning" 14 "a014_TPMSSoftWarning" 15 "a015_TPMSOverPressureWarning" 16 "a016_TPMSTemperatureWarning" 17 "a017_TPMSSystemFault" 18 "a018_SlipStartOn" 19 "a019_ParkBrakeFault" 20 "a020_SteeringReduced" 21 "a021_RearSeatbeltUnbuckled" 22 "a022_ApeFusesEtc" 23 "a023_CellInternetCheckFailed" 24 "a024_WifiInternetCheckFailed" 25 "a025_WifiOnlineCheckFailed" 26 "a026_ModemResetLoopDetected" 27 "a027_AutoSteerMIA" 28 "a028_FrontTrunkPopupClosed" 29 "a029_ModemMIA" 30 "a030_ModemVMCrash" 31 "a031_BrakeFluidLow" 32 "a032_CellModemRecoveryResets" 33 "a033_ApTrialExpired" 34 "a034_WakeupProblem" 35 "a035_AudioWatchdogKernelError" 36 "a036_AudioWatchdogHfpError" 37 "a037_AudioWatchdogXrunStormError" 38 "a038_AudioWatchdogA2bI2cLockupError" 39 "a039_AudioA2bNeedRediscovery" 40 "a040_HomelinkTransmit" 41 "a041_AudioDmesgXrun" 42 "a042_AudioDmesgRtThrottling" 43 "a043_InvalidMapDataOverride" 44 "a044_AudioDmesgDspException" 45 "a045_ECallNeedsService" 46 "a046_BackupCameraStreamError" 47 "a047_CellRoamingDisallowed" 48 "a048_AudioPremiumAmpCheckFailed" 49 "a049_BrakeShiftRequired" 50 "a050_BackupCameraIPUTimeout" 51 "a051_BackupCameraFrameTimeout" 52 "a052_KernelPanicReported" 53 "a053_QtCarExitError" 54 "a054_AudioBoostPowerBad" 55 "a055_ManualECallDisabled" 56 "a056_ManualECallButtonDisconnected" 57 "a057_CellAntennaDisconnected" 58 "a058_GPSAntennaDisconnected" 59 "a059_ECallSpeakerDisconnected" 60 "a060_ECallMicDisconnected" 61 "a061_SIMTestFailed" 62 "a062_ENSTestFailed" 63 "a063_CellularTestFailed" 64 "a064_ModemFirmwareTestFailed" 65 "a065_WiFiRecoveryReset" 66 "a066_GpuHangDetected" 67 "a067_WarnOnI915" 68 "a068_VideoUnexpectedExit" 69 "a069_VideoUDPTimeout" 70 "a070_VideoPipelineWarning" 71 "a071_VideoPipelineError" 72 "a072_ECallAnalogMicFailed" 73 "a073_ECallDigitalMicFailed" 74 "a074_EMMCHangDetected" 75 "a075_BackupCameraInitError" 76 "a076_NumFalseManualECalls" 77 "a077_AudioA2bMicChannelSwap" 78 "a078_DashcamUsbDriveUnmountable" 79 "a079_DashcamUsbDriveFull" 80 "a080_DashcamUsbDriveSlow" 81 "a081_CellModemSearchExpired" 82 "a082_NumModemRebootStuckInECall" 83 "a083_ECallProxyWatchdogTriggered" 84 "a084_SerializerError" 85 "a085_DeserializerError" 86 "a086_TouchEnumerationError" 87 "a087_BmpReset" 88 "a088_CellRemovableSimMissing" 89 "a089_RadioSoftResetError" 90 "a090_RadioPingFailError" 91 "a091_VehicleLinkStall" 92 "a092_updateStarted" 93 "a093_updateEnded" 94 "a094_ModemPowerOnFailure" 95 "a095_CidStorageRunningLow" 96 "a096_VideodPipelineIssueDetected" 97 "a097_AudiodRestarted" 98 "a098_DiskCheckFailure" 99 "a099_eMMCStatusError" 100 "a100_eMMCFTLError" 101 "a101_wifiStackProblem" 102 "a102_A2bDiscoveryFailed" 103 "a103_UsbHubNotEnumerating" 104 "a104_DashcamUsbDriveMissing" 105 "a105_firmwareReinstallRequested" 106 "a106_rebootBackstopTriggered" 107 "a107_DashcamUsbDriveTooBigForVfatFsck" 108 "a108_DashcamUsbDriveGettingFull" 109 "a109_DashcamUsbDriveTooSmall" 110 "a110_DashcamUsbDriveCorrupt" 111 "a111_DashcamUsbDriveWrongPort" 112 "a112_badUSBDevice" 113 "a113_DashcamHasOnboardSentryClips" ;
VAL_ 1365 RADC_alertState 0 "CLEARED" 1 "SET" ;
VAL_ 1383 ADSP_a2baState 0 "INIT" 1 "DOWN" 2 "RESTART" 3 "DISCOVER" 4 "DISCOVER_WAIT" 5 "IDLE" 6 "DIAG" 7 "DISCOVER_RETRY" 8 "GOING_DOWN" ;
VAL_ 1383 ADSP_a2bbState 0 "INIT" 1 "DOWN" 2 "RESTART" 3 "DISCOVER" 4 "DISCOVER_WAIT" 5 "IDLE" 6 "DIAG" 7 "DISCOVER_RETRY" 8 "GOING_DOWN" ;
VAL_ 1383 ADSP_baseamp0State 0 "INIT" 1 "CONFIGURED" 2 "ENABLED" 3 "HALT" 4 "TURN_OFF" 5 "OFF" 6 "DIAG" ;
VAL_ 1383 ADSP_baseamp1State 0 "INIT" 1 "CONFIGURED" 2 "ENABLED" 3 "HALT" 4 "TURN_OFF" 5 "OFF" 6 "DIAG" ;
VAL_ 1383 ADSP_baseamp2State 0 "INIT" 1 "CONFIGURED" 2 "ENABLED" 3 "HALT" 4 "TURN_OFF" 5 "OFF" 6 "DIAG" ;
VAL_ 1383 ADSP_ancState 0 "INIT" 1 "DSP_OFF" 2 "DSP_ON" 3 "ENABLED" ;
VAL_ 1383 ADSP_sourceSelect 0 "MEDIA" 1 "A2DP" 2 "TUNER" 3 "SINE" 4 "PINK" ;
VAL_ 1383 ADSP_tunerSelect 0 "FM" 1 "XM" ;
VAL_ 1383 ADSP_ancMode 0 "OFF" 1 "FRONT" 2 "REAR" 3 "ALL" 4 "CALIBRATING_00" 5 "DISABLED_REASON_A2BA" 6 "DISABLED_REASON_A2BB" 7 "DISABLED_REASON_CLOSURE_OPEN" 8 "DISABLED_REASON_HVAC" 9 "DISABLED_REASON_SEAT_MOVING" 10 "DISABLED_REASON_REAR_OCCUPANT" 11 "DISABLED_REASON_WINDOW_OPEN" 12 "CALIBRATING_20" 13 "CALIBRATING_40" 14 "CALIBRATING_60" 15 "CALIBRATING_80" 16 "UNKNOWN" ;
VAL_ 1383 ADSP_eCall_ENS_state 0 "UNKOWN" 1 "SIGNAL_ERROR" 2 "SOURCE_MISSING" 3 "SOURCE_ERROR" 4 "EMERGENCY" 5 "NORMAL" ;
VAL_ 1383 ADSP_eCallSelfTest 0 "NOT_RUN_YET" 1 "PASSED" 2 "FAILED" ;
VAL_ 1383 ADSP_eCallState 0 "INACTIVE" 1 "ACTIVE" ;
VAL_ 1383 ADSP_eCallMicrophoneStatus 0 "NOT_RUN_YET" 1 "PASSED" 2 "FAILED" ;
VAL_ 1383 ADSP_eCallSpeakerStatus 0 "NOT_RUN_YET" 1 "PASSED" 2 "FAILED_DISCONNECT" 3 "FAILED_DIAG" ;
VAL_ 1425 EPAS3S_alertID 0 "ALERT_DO_NOT_USE_ZERO" 1 "a001_DriverDoorOpen" 2 "a002_DoorOpen" 3 "a003_TrunkOpen" 4 "a004_FrunkOpen" 5 "a005_HeadlightsOnDoorOpen" 6 "a006_RemoteServiceAlert" 7 "a007_SoftPackConfigMismatch" 8 "a008_TouchScreenError" 9 "a009_SquashfsError" 10 "a010_MapsMissing" 11 "a011_IncorrectMap" 12 "a012_NotOnPrivateProperty" 13 "a013_TPMSHardWarning" 14 "a014_TPMSSoftWarning" 15 "a015_TPMSOverPressureWarning" 16 "a016_TPMSTemperatureWarning" 17 "a017_TPMSSystemFault" 18 "a018_SlipStartOn" 19 "a019_ParkBrakeFault" 20 "a020_SteeringReduced" 21 "a021_RearSeatbeltUnbuckled" 22 "a022_ApeFusesEtc" 23 "a023_CellInternetCheckFailed" 24 "a024_WifiInternetCheckFailed" 25 "a025_WifiOnlineCheckFailed" 26 "a026_ModemResetLoopDetected" 27 "a027_AutoSteerMIA" 28 "a028_FrontTrunkPopupClosed" 29 "a029_ModemMIA" 30 "a030_ModemVMCrash" 31 "a031_BrakeFluidLow" 32 "a032_CellModemRecoveryResets" 33 "a033_ApTrialExpired" 34 "a034_WakeupProblem" 35 "a035_AudioWatchdogKernelError" 36 "a036_AudioWatchdogHfpError" 37 "a037_AudioWatchdogXrunStormError" 38 "a038_AudioWatchdogA2bI2cLockupError" 39 "a039_AudioA2bNeedRediscovery" 40 "a040_HomelinkTransmit" 41 "a041_AudioDmesgXrun" 42 "a042_AudioDmesgRtThrottling" 43 "a043_InvalidMapDataOverride" 44 "a044_AudioDmesgDspException" 45 "a045_ECallNeedsService" 46 "a046_BackupCameraStreamError" 47 "a047_CellRoamingDisallowed" 48 "a048_AudioPremiumAmpCheckFailed" 49 "a049_BrakeShiftRequired" 50 "a050_BackupCameraIPUTimeout" 51 "a051_BackupCameraFrameTimeout" 52 "a052_KernelPanicReported" 53 "a053_QtCarExitError" 54 "a054_AudioBoostPowerBad" 55 "a055_ManualECallDisabled" 56 "a056_ManualECallButtonDisconnected" 57 "a057_CellAntennaDisconnected" 58 "a058_GPSAntennaDisconnected" 59 "a059_ECallSpeakerDisconnected" 60 "a060_ECallMicDisconnected" 61 "a061_SIMTestFailed" 62 "a062_ENSTestFailed" 63 "a063_CellularTestFailed" 64 "a064_ModemFirmwareTestFailed" 65 "a065_WiFiRecoveryReset" 66 "a066_GpuHangDetected" 67 "a067_WarnOnI915" 68 "a068_VideoUnexpectedExit" 69 "a069_VideoUDPTimeout" 70 "a070_VideoPipelineWarning" 71 "a071_VideoPipelineError" 72 "a072_ECallAnalogMicFailed" 73 "a073_ECallDigitalMicFailed" 74 "a074_EMMCHangDetected" 75 "a075_BackupCameraInitError" 76 "a076_NumFalseManualECalls" 77 "a077_AudioA2bMicChannelSwap" 78 "a078_DashcamUsbDriveUnmountable" 79 "a079_DashcamUsbDriveFull" 80 "a080_DashcamUsbDriveSlow" 81 "a081_CellModemSearchExpired" 82 "a082_NumModemRebootStuckInECall" 83 "a083_ECallProxyWatchdogTriggered" 84 "a084_SerializerError" 85 "a085_DeserializerError" 86 "a086_TouchEnumerationError" 87 "a087_BmpReset" 88 "a088_CellRemovableSimMissing" 89 "a089_RadioSoftResetError" 90 "a090_RadioPingFailError" 91 "a091_VehicleLinkStall" 92 "a092_updateStarted" 93 "a093_updateEnded" 94 "a094_ModemPowerOnFailure" 95 "a095_CidStorageRunningLow" 96 "a096_VideodPipelineIssueDetected" 97 "a097_AudiodRestarted" 98 "a098_DiskCheckFailure" 99 "a099_eMMCStatusError" 100 "a100_eMMCFTLError" 101 "a101_wifiStackProblem" 102 "a102_A2bDiscoveryFailed" 103 "a103_UsbHubNotEnumerating" 104 "a104_DashcamUsbDriveMissing" 105 "a105_firmwareReinstallRequested" 106 "a106_rebootBackstopTriggered" 107 "a107_DashcamUsbDriveTooBigForVfatFsck" 108 "a108_DashcamUsbDriveGettingFull" 109 "a109_DashcamUsbDriveTooSmall" 110 "a110_DashcamUsbDriveCorrupt" 111 "a111_DashcamUsbDriveWrongPort" 112 "a112_badUSBDevice" 113 "a113_DashcamHasOnboardSentryClips" ;
VAL_ 1425 EPAS3S_alertState 0 "CLEARED" 1 "SET" ;
VAL_ 1425 EPAS3S_a148_vehicleSpeed 8191 "SNA" ;
VAL_ 1425 EPAS3S_a154_vehicleSpeed 8191 "SNA" ;
VAL_ 1425 EPAS3S_a155_vehicleSpeed 8191 "SNA" ;
VAL_ 1425 EPAS3S_a156_vehicleSpeed 8191 "SNA" ;
VAL_ 1429 OCS1P_alertID 0 "ALERT_DO_NOT_USE_ZERO" 1 "a001_DriverDoorOpen" 2 "a002_DoorOpen" 3 "a003_TrunkOpen" 4 "a004_FrunkOpen" 5 "a005_HeadlightsOnDoorOpen" 6 "a006_RemoteServiceAlert" 7 "a007_SoftPackConfigMismatch" 8 "a008_TouchScreenError" 9 "a009_SquashfsError" 10 "a010_MapsMissing" 11 "a011_IncorrectMap" 12 "a012_NotOnPrivateProperty" 13 "a013_TPMSHardWarning" 14 "a014_TPMSSoftWarning" 15 "a015_TPMSOverPressureWarning" 16 "a016_TPMSTemperatureWarning" 17 "a017_TPMSSystemFault" 18 "a018_SlipStartOn" 19 "a019_ParkBrakeFault" 20 "a020_SteeringReduced" 21 "a021_RearSeatbeltUnbuckled" 22 "a022_ApeFusesEtc" 23 "a023_CellInternetCheckFailed" 24 "a024_WifiInternetCheckFailed" 25 "a025_WifiOnlineCheckFailed" 26 "a026_ModemResetLoopDetected" 27 "a027_AutoSteerMIA" 28 "a028_FrontTrunkPopupClosed" 29 "a029_ModemMIA" 30 "a030_ModemVMCrash" 31 "a031_BrakeFluidLow" 32 "a032_CellModemRecoveryResets" 33 "a033_ApTrialExpired" 34 "a034_WakeupProblem" 35 "a035_AudioWatchdogKernelError" 36 "a036_AudioWatchdogHfpError" 37 "a037_AudioWatchdogXrunStormError" 38 "a038_AudioWatchdogA2bI2cLockupError" 39 "a039_AudioA2bNeedRediscovery" 40 "a040_HomelinkTransmit" 41 "a041_AudioDmesgXrun" 42 "a042_AudioDmesgRtThrottling" 43 "a043_InvalidMapDataOverride" 44 "a044_AudioDmesgDspException" 45 "a045_ECallNeedsService" 46 "a046_BackupCameraStreamError" 47 "a047_CellRoamingDisallowed" 48 "a048_AudioPremiumAmpCheckFailed" 49 "a049_BrakeShiftRequired" 50 "a050_BackupCameraIPUTimeout" 51 "a051_BackupCameraFrameTimeout" 52 "a052_KernelPanicReported" 53 "a053_QtCarExitError" 54 "a054_AudioBoostPowerBad" 55 "a055_ManualECallDisabled" 56 "a056_ManualECallButtonDisconnected" 57 "a057_CellAntennaDisconnected" 58 "a058_GPSAntennaDisconnected" 59 "a059_ECallSpeakerDisconnected" 60 "a060_ECallMicDisconnected" 61 "a061_SIMTestFailed" 62 "a062_ENSTestFailed" 63 "a063_CellularTestFailed" 64 "a064_ModemFirmwareTestFailed" 65 "a065_WiFiRecoveryReset" 66 "a066_GpuHangDetected" 67 "a067_WarnOnI915" 68 "a068_VideoUnexpectedExit" 69 "a069_VideoUDPTimeout" 70 "a070_VideoPipelineWarning" 71 "a071_VideoPipelineError" 72 "a072_ECallAnalogMicFailed" 73 "a073_ECallDigitalMicFailed" 74 "a074_EMMCHangDetected" 75 "a075_BackupCameraInitError" 76 "a076_NumFalseManualECalls" 77 "a077_AudioA2bMicChannelSwap" 78 "a078_DashcamUsbDriveUnmountable" 79 "a079_DashcamUsbDriveFull" 80 "a080_DashcamUsbDriveSlow" 81 "a081_CellModemSearchExpired" 82 "a082_NumModemRebootStuckInECall" 83 "a083_ECallProxyWatchdogTriggered" 84 "a084_SerializerError" 85 "a085_DeserializerError" 86 "a086_TouchEnumerationError" 87 "a087_BmpReset" 88 "a088_CellRemovableSimMissing" 89 "a089_RadioSoftResetError" 90 "a090_RadioPingFailError" 91 "a091_VehicleLinkStall" 92 "a092_updateStarted" 93 "a093_updateEnded" 94 "a094_ModemPowerOnFailure" 95 "a095_CidStorageRunningLow" 96 "a096_VideodPipelineIssueDetected" 97 "a097_AudiodRestarted" 98 "a098_DiskCheckFailure" 99 "a099_eMMCStatusError" 100 "a100_eMMCFTLError" 101 "a101_wifiStackProblem" 102 "a102_A2bDiscoveryFailed" 103 "a103_UsbHubNotEnumerating" 104 "a104_DashcamUsbDriveMissing" 105 "a105_firmwareReinstallRequested" 106 "a106_rebootBackstopTriggered" 107 "a107_DashcamUsbDriveTooBigForVfatFsck" 108 "a108_DashcamUsbDriveGettingFull" 109 "a109_DashcamUsbDriveTooSmall" 110 "a110_DashcamUsbDriveCorrupt" 111 "a111_DashcamUsbDriveWrongPort" 112 "a112_badUSBDevice" 113 "a113_DashcamHasOnboardSentryClips" ;
VAL_ 1429 OCS1P_alertState 0 "CLEARED" 1 "SET" ;
VAL_ 1465 DAS_alertID 0 "ALERT_DO_NOT_USE_ZERO" 1 "a001_DriverDoorOpen" 2 "a002_DoorOpen" 3 "a003_TrunkOpen" 4 "a004_FrunkOpen" 5 "a005_HeadlightsOnDoorOpen" 6 "a006_RemoteServiceAlert" 7 "a007_SoftPackConfigMismatch" 8 "a008_TouchScreenError" 9 "a009_SquashfsError" 10 "a010_MapsMissing" 11 "a011_IncorrectMap" 12 "a012_NotOnPrivateProperty" 13 "a013_TPMSHardWarning" 14 "a014_TPMSSoftWarning" 15 "a015_TPMSOverPressureWarning" 16 "a016_TPMSTemperatureWarning" 17 "a017_TPMSSystemFault" 18 "a018_SlipStartOn" 19 "a019_ParkBrakeFault" 20 "a020_SteeringReduced" 21 "a021_RearSeatbeltUnbuckled" 22 "a022_ApeFusesEtc" 23 "a023_CellInternetCheckFailed" 24 "a024_WifiInternetCheckFailed" 25 "a025_WifiOnlineCheckFailed" 26 "a026_ModemResetLoopDetected" 27 "a027_AutoSteerMIA" 28 "a028_FrontTrunkPopupClosed" 29 "a029_ModemMIA" 30 "a030_ModemVMCrash" 31 "a031_BrakeFluidLow" 32 "a032_CellModemRecoveryResets" 33 "a033_ApTrialExpired" 34 "a034_WakeupProblem" 35 "a035_AudioWatchdogKernelError" 36 "a036_AudioWatchdogHfpError" 37 "a037_AudioWatchdogXrunStormError" 38 "a038_AudioWatchdogA2bI2cLockupError" 39 "a039_AudioA2bNeedRediscovery" 40 "a040_HomelinkTransmit" 41 "a041_AudioDmesgXrun" 42 "a042_AudioDmesgRtThrottling" 43 "a043_InvalidMapDataOverride" 44 "a044_AudioDmesgDspException" 45 "a045_ECallNeedsService" 46 "a046_BackupCameraStreamError" 47 "a047_CellRoamingDisallowed" 48 "a048_AudioPremiumAmpCheckFailed" 49 "a049_BrakeShiftRequired" 50 "a050_BackupCameraIPUTimeout" 51 "a051_BackupCameraFrameTimeout" 52 "a052_KernelPanicReported" 53 "a053_QtCarExitError" 54 "a054_AudioBoostPowerBad" 55 "a055_ManualECallDisabled" 56 "a056_ManualECallButtonDisconnected" 57 "a057_CellAntennaDisconnected" 58 "a058_GPSAntennaDisconnected" 59 "a059_ECallSpeakerDisconnected" 60 "a060_ECallMicDisconnected" 61 "a061_SIMTestFailed" 62 "a062_ENSTestFailed" 63 "a063_CellularTestFailed" 64 "a064_ModemFirmwareTestFailed" 65 "a065_WiFiRecoveryReset" 66 "a066_GpuHangDetected" 67 "a067_WarnOnI915" 68 "a068_VideoUnexpectedExit" 69 "a069_VideoUDPTimeout" 70 "a070_VideoPipelineWarning" 71 "a071_VideoPipelineError" 72 "a072_ECallAnalogMicFailed" 73 "a073_ECallDigitalMicFailed" 74 "a074_EMMCHangDetected" 75 "a075_BackupCameraInitError" 76 "a076_NumFalseManualECalls" 77 "a077_AudioA2bMicChannelSwap" 78 "a078_DashcamUsbDriveUnmountable" 79 "a079_DashcamUsbDriveFull" 80 "a080_DashcamUsbDriveSlow" 81 "a081_CellModemSearchExpired" 82 "a082_NumModemRebootStuckInECall" 83 "a083_ECallProxyWatchdogTriggered" 84 "a084_SerializerError" 85 "a085_DeserializerError" 86 "a086_TouchEnumerationError" 87 "a087_BmpReset" 88 "a088_CellRemovableSimMissing" 89 "a089_RadioSoftResetError" 90 "a090_RadioPingFailError" 91 "a091_VehicleLinkStall" 92 "a092_updateStarted" 93 "a093_updateEnded" 94 "a094_ModemPowerOnFailure" 95 "a095_CidStorageRunningLow" 96 "a096_VideodPipelineIssueDetected" 97 "a097_AudiodRestarted" 98 "a098_DiskCheckFailure" 99 "a099_eMMCStatusError" 100 "a100_eMMCFTLError" 101 "a101_wifiStackProblem" 102 "a102_A2bDiscoveryFailed" 103 "a103_UsbHubNotEnumerating" 104 "a104_DashcamUsbDriveMissing" 105 "a105_firmwareReinstallRequested" 106 "a106_rebootBackstopTriggered" 107 "a107_DashcamUsbDriveTooBigForVfatFsck" 108 "a108_DashcamUsbDriveGettingFull" 109 "a109_DashcamUsbDriveTooSmall" 110 "a110_DashcamUsbDriveCorrupt" 111 "a111_DashcamUsbDriveWrongPort" 112 "a112_badUSBDevice" 113 "a113_DashcamHasOnboardSentryClips" ;
VAL_ 1465 DAS_alertState 0 "CLEARED" 1 "SET" ;
VAL_ 1465 DAS_sw030_heaterState 0 "OFF_SNA" 1 "ON" ;
VAL_ 1465 DAS_sw042_health_state 0 "STANDBY" 1 "DRIVE" 2 "SUPPORT" 3 "CHARGE" 4 "FEIM" 5 "CLEAR_FAULT" 6 "FAULT" 7 "WELD" 8 "TEST" 9 "SNA" 10 "DIAG" ;
VAL_ 1465 DAS_sw043_mobileye_status 0 "DISABLED" 1 "ENABLED" 2 "TEMPORARY_FAILURE" 3 "SNA" ;
VAL_ 1465 DAS_sw065_app_mobileye_status 0 "DISABLED" 1 "ENABLED" 2 "TEMPORARY_FAILURE" 3 "SNA" ;
VAL_ 1465 DAS_sw066_app_mobileye_status 0 "DISABLED" 1 "ENABLED" 2 "TEMPORARY_FAILURE" 3 "SNA" ;
VAL_ 1465 DAS_sw078_camCipv_dx 255 "SNA" ;
VAL_ 1465 DAS_sw131_mainCamExtPitchCal 511 "SNA" ;
VAL_ 1465 DAS_sw132_narrowCamExtPitchCal 511 "SNA" ;
VAL_ 1465 DAS_sw177_fisheyeCamExtPitchCal 511 "SNA" ;
VAL_ 1465 DAS_sw178_lPillarCamExtPitchCal 511 "SNA" ;
VAL_ 1465 DAS_sw179_rPillarCamExtPitchCal 511 "SNA" ;
VAL_ 1465 DAS_sw180_lRepeatCamExtPitchCal 511 "SNA" ;
VAL_ 1465 DAS_sw181_rRepeatCamExtPitchCal 511 "SNA" ;
VAL_ 1465 DAS_sw064_status 0 "DISABLED" 1 "ENABLED" 2 "TEMPORARY_FAILURE" 3 "SNA" ;
VAL_ 1465 DAS_sw219_roadClass 0 "UNKNOWN_INVALID_SNA" 1 "CLASS_1_MAJOR" 2 "CLASS_2" 3 "CLASS_3" 4 "CLASS_4" 5 "CLASS_5" 6 "CLASS_6_MINOR" ;
VAL_ 1465 DAS_sw220_roadClass 0 "UNKNOWN_INVALID_SNA" 1 "CLASS_1_MAJOR" 2 "CLASS_2" 3 "CLASS_3" 4 "CLASS_4" 5 "CLASS_5" 6 "CLASS_6_MINOR" ;
VAL_ 1465 DAS_sw027_Unused_Bit_0 0 "0" 1 "1" 2 "2" 3 "3" 4 "4" 5 "5" 6 "6" 7 "7" 8 "8" 9 "9" 10 "10" 11 "11" 12 "12" 13 "13" 14 "14" 15 "15" 16 "16" 17 "17" 18 "18" 19 "19" 20 "20" 21 "21" 22 "22" 23 "23" 24 "24" 25 "25" 26 "26" 27 "27" 28 "28" 29 "29" 30 "30" 31 "31" ;
VAL_ 1465 DAS_sw227_vehicleSpeed 8191 "SNA" ;
VAL_ 1465 DAS_sw025_road_class 0 "SNA" 1 "SUPERCHARGER" 2 "URBANCHARGER" ;
VAL_ 1465 DAS_sw047_roadClass 0 "UNKNOWN_INVALID_SNA" 1 "CLASS_1_MAJOR" 2 "CLASS_2" 3 "CLASS_3" 4 "CLASS_4" 5 "CLASS_5" 6 "CLASS_6_MINOR" ;
VAL_ 1465 DAS_sw219_vehicleSpeed 8191 "SNA" ;
VAL_ 1465 DAS_sw220_vehicleSpeed 8191 "SNA" ;
VAL_ 1465 DAS_sw069_eacStatus 0 "INHIBITED" 1 "AVAILABLE" 2 "ACTIVE" 3 "FAULT" 4 "LKA_ELK_AVAILABLE" 5 "LKA_ACTIVE" 6 "ELK_AVAILABLE" 7 "ELK_ACTIVE" ;
VAL_ 1465 DAS_sw203_roadClass 0 "UNKNOWN_INVALID_SNA" 1 "CLASS_1_MAJOR" 2 "CLASS_2" 3 "CLASS_3" 4 "CLASS_4" 5 "CLASS_5" 6 "CLASS_6_MINOR" ;
VAL_ 1465 DAS_sw004_accState 0 "ACC_CANCEL_GENERIC" 3 "ACC_HOLD" 4 "ACC_ON" 5 "APC_BACKWARD" 6 "APC_FORWARD" 7 "APC_COMPLETE" 8 "APC_ABORT" 9 "APC_PAUSE" 10 "APC_UNPARK_COMPLETE" 11 "APC_SELFPARK_START" 13 "ACC_CANCEL_GENERIC_SILENT" 15 "FAULT_SNA" ;
VAL_ 1465 DAS_sw065_mobileye_main_state 0 "STANDBY" 1 "DRIVE" 2 "SUPPORT" 3 "CHARGE" 4 "FEIM" 5 "CLEAR_FAULT" 6 "FAULT" 7 "WELD" 8 "TEST" 9 "SNA" 10 "DIAG" ;
VAL_ 1465 DAS_sw066_mobileye_main_state 0 "STANDBY" 1 "DRIVE" 2 "SUPPORT" 3 "CHARGE" 4 "FEIM" 5 "CLEAR_FAULT" 6 "FAULT" 7 "WELD" 8 "TEST" 9 "SNA" 10 "DIAG" ;
VAL_ 1465 DAS_sw005_steeringAngle 16383 "SNA" ;
VAL_ 1465 DAS_sw043_mesp_health_main_state 0 "STANDBY" 1 "DRIVE" 2 "SUPPORT" 3 "CHARGE" 4 "FEIM" 5 "CLEAR_FAULT" 6 "FAULT" 7 "WELD" 8 "TEST" 9 "SNA" 10 "DIAG" ;
VAL_ 1465 DAS_sw078_radarTarg5_dx 255 "SNA" ;
VAL_ 1465 DAS_sw083_Targ5_dx 255 "SNA" ;
VAL_ 1465 DAS_sw085_roadClass 0 "UNKNOWN_INVALID_SNA" 1 "CLASS_1_MAJOR" 2 "CLASS_2" 3 "CLASS_3" 4 "CLASS_4" 5 "CLASS_5" 6 "CLASS_6_MINOR" ;
VAL_ 1465 DAS_sw005_gear 0 "INVALID" 1 "P" 2 "R" 3 "N" 4 "D" 7 "SNA" ;
VAL_ 1465 DAS_sw131_mainCamExtYawCal 511 "SNA" ;
VAL_ 1465 DAS_sw132_narrowCamExtYawCal 511 "SNA" ;
VAL_ 1465 DAS_sw177_fisheyeCamExtYawCal 511 "SNA" ;
VAL_ 1465 DAS_sw178_lPillarCamExtYawCal 511 "SNA" ;
VAL_ 1465 DAS_sw179_rPillarCamExtYawCal 511 "SNA" ;
VAL_ 1465 DAS_sw180_lRepeatCamExtYawCal 511 "SNA" ;
VAL_ 1465 DAS_sw181_rRepeatCamExtYawCal 511 "SNA" ;
VAL_ 1465 DAS_sw077_vehicleSpeed 8191 "SNA" ;
VAL_ 1465 DAS_sw025_offsetSide 0 "NO_OFFSET" 1 "OFFSET_RIGHT_OBJECT" 2 "OFFSET_LEFT_OBJECT" 3 "OFFSET_BOTH_OBJECTS" ;
VAL_ 1465 DAS_sw071_roadClass 0 "UNKNOWN_INVALID_SNA" 1 "CLASS_1_MAJOR" 2 "CLASS_2" 3 "CLASS_3" 4 "CLASS_4" 5 "CLASS_5" 6 "CLASS_6_MINOR" ;
VAL_ 1465 DAS_sw078_radarTarg5_VxRel 0 "NO_TARGET" ;
VAL_ 1465 DAS_sw080_road_class 0 "SNA" 1 "SUPERCHARGER" 2 "URBANCHARGER" ;
VAL_ 1465 DAS_sw195_vehicleSpeed 8191 "SNA" ;
VAL_ 1465 DAS_sw202_vehicleSpeed 8191 "SNA" ;
VAL_ 1465 DAS_sw006_steeringAngle 16383 "SNA" ;
VAL_ 1465 DAS_sw069_roadClass 0 "UNKNOWN_INVALID_SNA" 1 "CLASS_1_MAJOR" 2 "CLASS_2" 3 "CLASS_3" 4 "CLASS_4" 5 "CLASS_5" 6 "CLASS_6_MINOR" ;
VAL_ 1465 DAS_sw006_gear 0 "INVALID" 1 "P" 2 "R" 3 "N" 4 "D" 7 "SNA" ;
VAL_ 1465 DAS_sw071_airSuspension 0 "NONE" ;
VAL_ 1465 DAS_sw025_torsionBarTorque 4094 "UNDEFINABLE_DATA" 4095 "SNA" ;
VAL_ 1465 DAS_sw078_radarTarg1_dx 255 "SNA" ;
VAL_ 1465 DAS_sw082_road_class 0 "SNA" 1 "SUPERCHARGER" 2 "URBANCHARGER" ;
VAL_ 1465 DAS_sw199_internalState 0 "NO_MODE_ACTIVE" 1 "PRE_DRIVE_CHECK" 2 "LOCAL_BRAKE_REQUEST" 3 "EXTERNAL_BRAKE_REQUEST" 4 "DIAGNOSTIC" 5 "TRANSITION_TO_IDLE" 6 "POST_DRIVE_CHECK" ;
VAL_ 1465 DAS_sw080_cruise_lever_state 0 "STANDBY" 1 "DRIVE" 2 "SUPPORT" 3 "CHARGE" 4 "FEIM" 5 "CLEAR_FAULT" 6 "FAULT" 7 "WELD" 8 "TEST" 9 "SNA" 10 "DIAG" ;
VAL_ 1465 DAS_sw006_yawRate 4294934528 "SNA" ;
VAL_ 1465 DAS_sw077_oocOffCourseDist_cm 255 "MAX_DOOR_HEIGHT_SNA" ;
VAL_ 1465 DAS_sw042_road_class 0 "SNA" 1 "SUPERCHARGER" 2 "URBANCHARGER" ;
VAL_ 1465 DAS_sw078_radarTarg1_VxRel 0 "NO_TARGET" ;
VAL_ 1465 DAS_sw086_roadClass 0 "UNKNOWN_INVALID_SNA" 1 "CLASS_1_MAJOR" 2 "CLASS_2" 3 "CLASS_3" 4 "CLASS_4" 5 "CLASS_5" 6 "CLASS_6_MINOR" ;
VAL_ 1465 DAS_sw006_trailerMode 0 "OFF" 1 "ON" ;
VAL_ 1465 DAS_sw050_aebEnable 0 "AEB_OFF" 1 "AEB_ON" 3 "SNA" ;
VAL_ 1465 DAS_sw074_roadClass 0 "UNKNOWN_INVALID_SNA" 1 "CLASS_1_MAJOR" 2 "CLASS_2" 3 "CLASS_3" 4 "CLASS_4" 5 "CLASS_5" 6 "CLASS_6_MINOR" ;
